VERSION ""

NS_ :

BS_:

BU_:

BO_ 2163223550 CN: 8 Vector__XXX
 SG_ CrashChecksum : 60|4@1+ (1,0) [0|15] "count" Vector__XXX
 SG_ CrashCounter : 56|4@1+ (1,0) [0|15] "count" Vector__XXX
 SG_ CrashType : 0|5@1+ (1,0) [0|31] "" Vector__XXX

BO_ 2230333950 WAND: 8 Vector__XXX
 SG_ WandAngle : 0|16@1+ (0.002,-64) [-64|64.51] "deg" Vector__XXX
 SG_ WandSensorFigureOfMerit : 16|2@1+ (1,0) [0|3] "" Vector__XXX

BO_ 2230334206 LDISP: 8 Vector__XXX
 SG_ MeasuredLinearDisplacement : 0|16@1+ (0.1,0) [0|6425.5] "mm" Vector__XXX
 SG_ LnrDsplmntSnsrSnsrFgrOfMrt : 16|2@1+ (1,0) [0|3] "" Vector__XXX

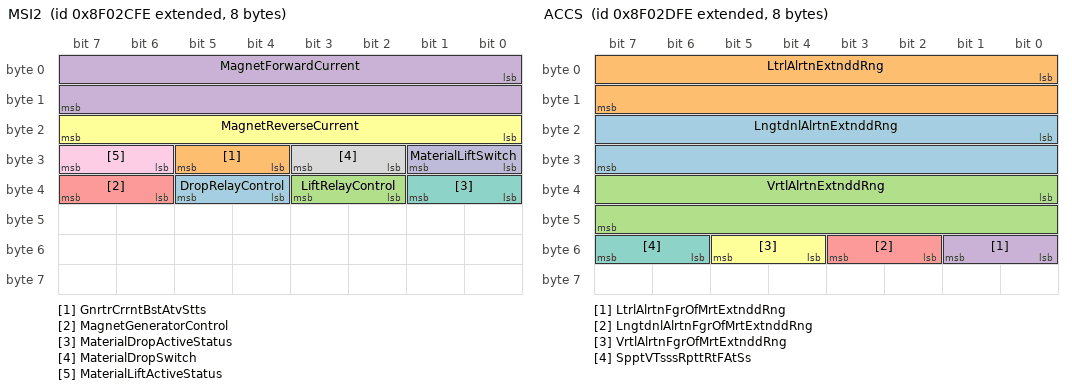
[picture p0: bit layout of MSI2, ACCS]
BO_ 2297441534 MSI2: 8 Vector__XXX
 SG_ DropRelayControl : 36|2@1+ (1,0) [0|3] "" Vector__XXX
 SG_ GnrtrCrrntBstAtvStts : 28|2@1+ (1,0) [0|3] "" Vector__XXX
 SG_ LiftRelayControl : 34|2@1+ (1,0) [0|3] "" Vector__XXX
 SG_ MagnetForwardCurrent : 0|16@1+ (1,0) [0|64255] "A" Vector__XXX
 SG_ MagnetGeneratorControl : 38|2@1+ (1,0) [0|3] "" Vector__XXX
 SG_ MagnetReverseCurrent : 16|8@1+ (1,0) [0|250] "A" Vector__XXX
 SG_ MaterialDropActiveStatus : 32|2@1+ (1,0) [0|3] "" Vector__XXX
 SG_ MaterialDropSwitch : 26|2@1+ (1,0) [0|3] "" Vector__XXX
 SG_ MaterialLiftActiveStatus : 30|2@1+ (1,0) [0|3] "" Vector__XXX
 SG_ MaterialLiftSwitch : 24|2@1+ (1,0) [0|3] "" Vector__XXX

BO_ 2297441790 ACCS: 8 Vector__XXX
 SG_ LngtdnlAlrtnExtnddRng : 16|16@1+ (0.01,-320) [-320|322.55] "m/(s*s)" Vector__XXX
 SG_ LtrlAlrtnExtnddRng : 0|16@1+ (0.01,-320) [-320|322.55] "m/(s*s)" Vector__XXX
 SG_ VrtlAlrtnExtnddRng : 32|16@1+ (0.01,-320) [-320|322.55] "m/(s*s)" Vector__XXX
 SG_ LtrlAlrtnFgrOfMrtExtnddRng : 48|2@1+ (1,0) [0|3] "" Vector__XXX
 SG_ LngtdnlAlrtnFgrOfMrtExtnddRng : 50|2@1+ (1,0) [0|3] "" Vector__XXX
 SG_ VrtlAlrtnFgrOfMrtExtnddRng : 52|2@1+ (1,0) [0|3] "" Vector__XXX
 SG_ SpptVTsssRpttRtFAtSs : 54|2@1+ (1,0) [0|3] "" Vector__XXX

BO_ 2297455358 ETC12: 8 Vector__XXX
 SG_ TrnsmssnDrtnlOtptShftSpd : 32|16@1+ (1,-32127) [-32127|32128] "rpm" Vector__XXX
 SG_ TrnsmssnHdrsttLp1Prssr : 0|16@1+ (1,0) [0|64255] "kPa" Vector__XXX
 SG_ TrnsmssnHdrsttLp2Prssr : 16|16@1+ (1,0) [0|64255] "kPa" Vector__XXX
 SG_ TrnsmssnIntrmdtShftSpd : 48|16@1+ (0.125,0) [0|8031.875] "rpm" Vector__XXX

BO_ 2297499902 B2: 8 Vector__XXX
 SG_ BrakePedalSwitch2 : 16|2@1+ (1,0) [0|3] "" Vector__XXX
 SG_ DmnddBrkAppltnPrssr : 0|16@1+ (0.1,0) [0|6425.5] "kPa" Vector__XXX

BO_ 2298375934 HRW: 8 Vector__XXX
 SG_ FrontAxleLeftWheelSpeed : 0|16@1+ (0.00390625,0) [0|250.99609375] "km/h" Vector__XXX
 SG_ FrontAxleRightWheelSpeed : 16|16@1+ (0.00390625,0) [0|250.99609375] "km/h" Vector__XXX
 SG_ RearAxleLeftWheelSpeed : 32|16@1+ (0.00390625,0) [0|250.99609375] "km/h" Vector__XXX
 SG_ RearAxleRightWheelSpeed : 48|16@1+ (0.00390625,0) [0|250.99609375] "km/h" Vector__XXX

BO_ 2348941054 TC1: 8 Vector__XXX
 SG_ DisengageDrivelineRequest : 4|2@1+ (1,0) [0|3] "" Vector__XXX
 SG_ DsnggDffrntlLkRqstCntrl : 32|2@1+ (1,0) [0|3] "" Vector__XXX
 SG_ DsnggDffrntlLkRqstCntrlFrnt : 34|2@1+ (1,0) [0|3] "" Vector__XXX
 SG_ DsnggDffrntlLkRqstCntrlRr : 36|2@1+ (1,0) [0|3] "" Vector__XXX
 SG_ DsnggDffrntlLkRqstFrntAxl1 : 24|2@1+ (1,0) [0|3] "" Vector__XXX
 SG_ DsnggDffrntlLkRqstFrntAxl2 : 26|2@1+ (1,0) [0|3] "" Vector__XXX
 SG_ DsnggDffrntlLkRqstRrAxl1 : 28|2@1+ (1,0) [0|3] "" Vector__XXX
 SG_ DsnggDffrntlLkRqstRrAxl2 : 30|2@1+ (1,0) [0|3] "" Vector__XXX
 SG_ RequestedPercentClutchSlip : 8|8@1+ (0.4,0) [0|100] "%" Vector__XXX
 SG_ TransmissionMode1 : 40|2@1+ (1,0) [0|3] "" Vector__XXX
 SG_ TransmissionMode2 : 42|2@1+ (1,0) [0|3] "" Vector__XXX
 SG_ TransmissionMode3 : 44|2@1+ (1,0) [0|3] "" Vector__XXX
 SG_ TransmissionMode4 : 46|2@1+ (1,0) [0|3] "" Vector__XXX
 SG_ TransmissionMode5 : 56|2@1+ (1,0) [0|3] "" Vector__XXX
 SG_ TransmissionMode6 : 58|2@1+ (1,0) [0|3] "" Vector__XXX
 SG_ TransmissionMode7 : 60|2@1+ (1,0) [0|3] "" Vector__XXX
 SG_ TransmissionMode8 : 62|2@1+ (1,0) [0|3] "" Vector__XXX
 SG_ TransmissionRequestedGear : 16|8@1+ (1,-125) [-64|64] "gear value" Vector__XXX
 SG_ TransmissionRequestedLaunchGear : 50|4@1+ (1,0) [0|15] "" Vector__XXX
 SG_ TrnsmssnAtNtrlMnlRtrnRqst : 48|2@1+ (1,0) [0|3] "" Vector__XXX
 SG_ TrnsmssnGrShftInhtRqst : 0|2@1+ (1,0) [0|3] "" Vector__XXX
 SG_ TrnsmssnLdRdtnInhtRqst : 38|2@1+ (1,0) [0|3] "" Vector__XXX
 SG_ TrnsmssnRvrsGrShftInhtRqst : 6|2@1+ (1,0) [0|3] "" Vector__XXX
 SG_ TrnsmssnShftSltrDsplMdSwth : 54|2@1+ (1,0) [0|3] "" Vector__XXX
 SG_ TrnsmssnTrqCnvrtrLkpRqst : 2|2@1+ (1,0) [0|3] "" Vector__XXX

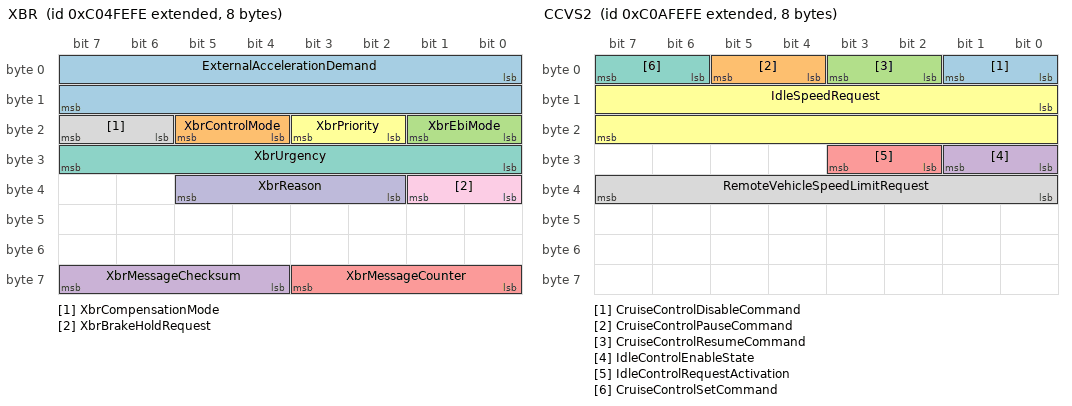
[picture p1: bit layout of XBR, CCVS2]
BO_ 2349137662 XBR: 8 Vector__XXX
 SG_ ExternalAccelerationDemand : 0|16@1+ (0.00048828125,-15.687) [-10|10] "m/(s*s)" Vector__XXX
 SG_ XbrControlMode : 20|2@1+ (1,0) [0|3] "" Vector__XXX
 SG_ XbrEbiMode : 16|2@1+ (1,0) [0|3] "" Vector__XXX
 SG_ XbrMessageChecksum : 60|4@1+ (1,0) [0|15] "count" Vector__XXX
 SG_ XbrMessageCounter : 56|4@1+ (1,0) [0|15] "count" Vector__XXX
 SG_ XbrPriority : 18|2@1+ (1,0) [0|3] "" Vector__XXX
 SG_ XbrUrgency : 24|8@1+ (0.4,0) [0|100] "%" Vector__XXX
 SG_ XbrCompensationMode : 22|2@1+ (1,0) [0|3] "" Vector__XXX
 SG_ XbrBrakeHoldRequest : 32|2@1+ (1,0) [0|3] "" Vector__XXX
 SG_ XbrReason : 34|4@1+ (1,0) [0|15] "" Vector__XXX

BO_ 2349399806 AUXIO5: 8 Vector__XXX
 SG_ AuxiliaryIOChannel3 : 48|16@1+ (1,0) [0|64255] "count" Vector__XXX
 SG_ AuxiliaryIOChannel4 : 32|16@1+ (1,0) [0|64255] "count" Vector__XXX
 SG_ AuxiliaryIOChannel5 : 16|16@1+ (1,0) [0|64255] "count" Vector__XXX
 SG_ AuxiliaryIOChannel6 : 0|16@1+ (1,0) [0|64255] "count" Vector__XXX

BO_ 2349465342 SRASI: 8 Vector__XXX
 SG_ StaticRollAngle : 0|8@1+ (1,-125) [-90|90] "deg" Vector__XXX
 SG_ StaticRollAngleStatus : 8|3@1+ (1,0) [0|7] "" Vector__XXX

BO_ 2349530878 CCVS2: 8 Vector__XXX
 SG_ CruiseControlDisableCommand : 0|2@1+ (1,0) [0|3] "" Vector__XXX
 SG_ CruiseControlPauseCommand : 4|2@1+ (1,0) [0|3] "" Vector__XXX
 SG_ CruiseControlResumeCommand : 2|2@1+ (1,0) [0|3] "" Vector__XXX
 SG_ IdleControlEnableState : 24|2@1+ (1,0) [0|3] "" Vector__XXX
 SG_ IdleControlRequestActivation : 26|2@1+ (1,0) [0|3] "" Vector__XXX
 SG_ IdleSpeedRequest : 8|16@1+ (0.125,0) [0|8031.875] "rpm" Vector__XXX
 SG_ CruiseControlSetCommand : 6|2@1+ (1,0) [0|3] "" Vector__XXX
 SG_ RemoteVehicleSpeedLimitRequest : 32|8@1+ (1,0) [0|250] "km/h" Vector__XXX

BO_ 2349596414 AEBS2: 8 Vector__XXX
 SG_ Aebs2MessageChecksum : 60|4@1+ (1,0) [0|15] "count" Vector__XXX
 SG_ Aebs2MessageCounter : 56|4@1+ (1,0) [0|15] "count" Vector__XXX
 SG_ DvAtvtDdFAdvdEBSst : 0|2@1+ (1,0) [0|3] "" Vector__XXX

BO_ 2349727486 TC2: 8 Vector__XXX
 SG_ TransmissionMode10 : 2|2@1+ (1,0) [0|3] "" Vector__XXX
 SG_ TransmissionMode9 : 0|2@1+ (1,0) [0|3] "" Vector__XXX
 SG_ TrnsmssnPrDfndMxmmGrAtvtnRqst : 4|2@1+ (1,0) [0|3] "" Vector__XXX
 SG_ TrnsmssnOtptShftBrkRqst : 6|2@1+ (1,0) [0|3] "" Vector__XXX
 SG_ TrnsmssnRqstdRvrsLnhGr : 8|4@1+ (1,0) [0|15] "" Vector__XXX
 SG_ SltdMxmmGrLmtAtvtnRqst : 12|2@1+ (1,0) [0|3] "" Vector__XXX
 SG_ TransmissionMode11 : 14|2@1+ (1,0) [0|3] "" Vector__XXX
 SG_ TransmissionMode12 : 16|2@1+ (1,0) [0|3] "" Vector__XXX
 SG_ TransmissionMode13 : 18|2@1+ (1,0) [0|3] "" Vector__XXX
 SG_ TransmissionMode14 : 20|2@1+ (1,0) [0|3] "" Vector__XXX
 SG_ TransmissionMode15 : 22|2@1+ (1,0) [0|3] "" Vector__XXX
 SG_ TransmissionMode16 : 24|2@1+ (1,0) [0|3] "" Vector__XXX
 SG_ TransmissionMode17 : 26|2@1+ (1,0) [0|3] "" Vector__XXX
 SG_ TransmissionMode18 : 28|2@1+ (1,0) [0|3] "" Vector__XXX
 SG_ TransmissionMode19 : 30|2@1+ (1,0) [0|3] "" Vector__XXX
 SG_ TransmissionMode20 : 32|2@1+ (1,0) [0|3] "" Vector__XXX
 SG_ DsnggDffrntlLkRqstRrAxl3 : 34|2@1+ (1,0) [0|3] "" Vector__XXX
 SG_ TrnsmssnCstMdDslRqst : 36|2@1+ (1,0) [0|3] "" Vector__XXX
 SG_ TrnsmssnExpltMnlMdRqst : 38|2@1+ (1,0) [0|3] "" Vector__XXX

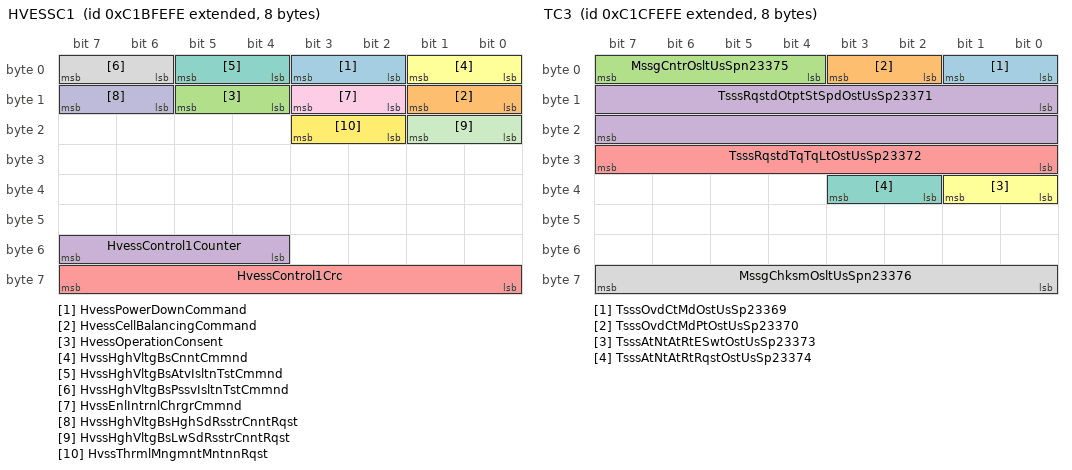
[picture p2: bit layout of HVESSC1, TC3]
BO_ 2350644990 HVESSC1: 8 Vector__XXX
 SG_ HvessPowerDownCommand : 2|2@1+ (1,0) [0|3] "" Vector__XXX
 SG_ HvessCellBalancingCommand : 8|2@1+ (1,0) [0|3] "" Vector__XXX
 SG_ HvessOperationConsent : 12|2@1+ (1,0) [0|3] "" Vector__XXX
 SG_ HvessControl1Counter : 52|4@1+ (1,0) [0|15] "" Vector__XXX
 SG_ HvessControl1Crc : 56|8@1+ (1,0) [0|250] "count" Vector__XXX
 SG_ HvssHghVltgBsCnntCmmnd : 0|2@1+ (1,0) [0|3] "" Vector__XXX
 SG_ HvssHghVltgBsAtvIsltnTstCmmnd : 4|2@1+ (1,0) [0|3] "" Vector__XXX
 SG_ HvssHghVltgBsPssvIsltnTstCmmnd : 6|2@1+ (1,0) [0|3] "" Vector__XXX
 SG_ HvssEnlIntrnlChrgrCmmnd : 10|2@1+ (1,0) [0|3] "" Vector__XXX
 SG_ HvssHghVltgBsHghSdRsstrCnntRqst : 14|2@1+ (1,0) [0|3] "" Vector__XXX
 SG_ HvssHghVltgBsLwSdRsstrCnntRqst : 16|2@1+ (1,0) [0|3] "" Vector__XXX
 SG_ HvssThrmlMngmntMntnnRqst : 18|2@1+ (1,0) [0|3] "" Vector__XXX

BO_ 2350710526 TC3: 8 Vector__XXX
 SG_ TsssOvdCtMdOstUsSp23369 : 0|2@1+ (1,0) [0|3] "" Vector__XXX
 SG_ TsssOvdCtMdPtOstUsSp23370 : 2|2@1+ (1,0) [0|3] "" Vector__XXX
 SG_ MssgCntrOsltUsSpn23375 : 4|4@1+ (1,0) [0|15] "count" Vector__XXX
 SG_ TsssRqstdOtptStSpdOstUsSp23371 : 8|16@1+ (0.25,-8031.75) [-8031.375|8031.75] "rpm" Vector__XXX
 SG_ TsssRqstdTqTqLtOstUsSp23372 : 24|8@1+ (1,-125) [-125|125] "%" Vector__XXX
 SG_ TsssAtNtAtRtESwtOstUsSp23373 : 32|2@1+ (1,0) [0|3] "" Vector__XXX
 SG_ TsssAtNtAtRtRqstOstUsSp23374 : 34|2@1+ (1,0) [0|3] "" Vector__XXX
 SG_ MssgChksmOsltUsSpn23376 : 56|8@1+ (1,0) [0|250] "count" Vector__XXX

BO_ 2350776062 EIC: 8 Vector__XXX
 SG_ EngineTimingAdvance : 0|16@1+ (0.0078125,-200) [-200|301.9921875] "deg" Vector__XXX

BO_ 2350841598 ALTC: 8 Vector__XXX
 SG_ AlternatorTorqueRampTimeCommand : 24|8@1+ (0.1,0) [0.1|25] "s" Vector__XXX
 SG_ AltrntrExttnMxmmCrrntLmt : 16|8@1+ (0.25,0) [0|62.5] "A" Vector__XXX
 SG_ AltrntrStpntVltgCmmnd : 0|16@1+ (0.001,0) [0|64.255] "V" Vector__XXX
 SG_ AltrntrTrqRmpMxmmSpdCmmnd : 32|8@1+ (32,0) [0|8000] "rpm" Vector__XXX

BO_ 2358902526 JLCM: 8 Vector__XXX
 SG_ Joystick1Lamp10Command : 18|2@1+ (1,0) [0|3] "" Vector__XXX
 SG_ Joystick1Lamp1Command : 0|2@1+ (1,0) [0|3] "" Vector__XXX
 SG_ Joystick1Lamp2Command : 2|2@1+ (1,0) [0|3] "" Vector__XXX
 SG_ Joystick1Lamp3Command : 4|2@1+ (1,0) [0|3] "" Vector__XXX
 SG_ Joystick1Lamp4Command : 6|2@1+ (1,0) [0|3] "" Vector__XXX
 SG_ Joystick1Lamp5Command : 8|2@1+ (1,0) [0|3] "" Vector__XXX
 SG_ Joystick1Lamp6Command : 10|2@1+ (1,0) [0|3] "" Vector__XXX
 SG_ Joystick1Lamp7Command : 12|2@1+ (1,0) [0|3] "" Vector__XXX
 SG_ Joystick1Lamp8Command : 14|2@1+ (1,0) [0|3] "" Vector__XXX
 SG_ Joystick1Lamp9Command : 16|2@1+ (1,0) [0|3] "" Vector__XXX
 SG_ Joystick2Lamp10Command : 38|2@1+ (1,0) [0|3] "" Vector__XXX
 SG_ Joystick2Lamp1Command : 20|2@1+ (1,0) [0|3] "" Vector__XXX
 SG_ Joystick2Lamp2Command : 22|2@1+ (1,0) [0|3] "" Vector__XXX
 SG_ Joystick2Lamp3Command : 24|2@1+ (1,0) [0|3] "" Vector__XXX
 SG_ Joystick2Lamp4Command : 26|2@1+ (1,0) [0|3] "" Vector__XXX
 SG_ Joystick2Lamp5Command : 28|2@1+ (1,0) [0|3] "" Vector__XXX
 SG_ Joystick2Lamp6Command : 30|2@1+ (1,0) [0|3] "" Vector__XXX
 SG_ Joystick2Lamp7Command : 32|2@1+ (1,0) [0|3] "" Vector__XXX
 SG_ Joystick2Lamp8Command : 34|2@1+ (1,0) [0|3] "" Vector__XXX
 SG_ Joystick2Lamp9Command : 36|2@1+ (1,0) [0|3] "" Vector__XXX
 SG_ Joystick3Lamp10Command : 58|2@1+ (1,0) [0|3] "" Vector__XXX
 SG_ Joystick3Lamp1Command : 40|2@1+ (1,0) [0|3] "" Vector__XXX
 SG_ Joystick3Lamp2Command : 42|2@1+ (1,0) [0|3] "" Vector__XXX
 SG_ Joystick3Lamp3Command : 44|2@1+ (1,0) [0|3] "" Vector__XXX
 SG_ Joystick3Lamp4Command : 46|2@1+ (1,0) [0|3] "" Vector__XXX
 SG_ Joystick3Lamp5Command : 48|2@1+ (1,0) [0|3] "" Vector__XXX
 SG_ Joystick3Lamp6Command : 50|2@1+ (1,0) [0|3] "" Vector__XXX
 SG_ Joystick3Lamp7Command : 52|2@1+ (1,0) [0|3] "" Vector__XXX
 SG_ Joystick3Lamp8Command : 54|2@1+ (1,0) [0|3] "" Vector__XXX
 SG_ Joystick3Lamp9Command : 56|2@1+ (1,0) [0|3] "" Vector__XXX

BO_ 2362572542 ASC6: 8 Vector__XXX
 SG_ LevelPresetFrontAxleLeft : 0|16@1+ (0.1,-3200) [-3200|3225.5] "mm" Vector__XXX
 SG_ LevelPresetFrontAxleRight : 16|16@1+ (0.1,-3200) [-3200|3225.5] "mm" Vector__XXX
 SG_ LevelPresetRearAxleLeft : 32|16@1+ (0.1,-3200) [-3200|3225.5] "mm" Vector__XXX
 SG_ LevelPresetRearAxleRight : 48|16@1+ (0.1,-3200) [-3200|3225.5] "mm" Vector__XXX

BO_ 2362638078 ASC2: 8 Vector__XXX
 SG_ AllwLvlCntrlDrngBrkngCmmnd : 54|2@1+ (1,0) [0|3] "" Vector__XXX
 SG_ AtmtTrtnHlpLdTrnsfr : 0|2@1+ (1,0) [0|3] "" Vector__XXX
 SG_ DamperStiffnessRequestFrontAxle : 24|8@1+ (0.4,0) [0|100] "%" Vector__XXX
 SG_ DamperStiffnessRequestRearAxle : 32|8@1+ (0.4,0) [0|100] "%" Vector__XXX
 SG_ DmprStffnssRqstLftTgAxl : 40|8@1+ (0.4,0) [0|100] "%" Vector__XXX
 SG_ KneelingCommandFrontAxle : 48|2@1+ (1,0) [0|3] "" Vector__XXX
 SG_ KneelingCommandRearAxle : 50|2@1+ (1,0) [0|3] "" Vector__XXX
 SG_ KneelingControlModeRequest : 6|2@1+ (1,0) [0|3] "" Vector__XXX
 SG_ KneelingRequestLeftSide : 2|2@1+ (1,0) [0|3] "" Vector__XXX
 SG_ KneelingRequestRightSide : 4|2@1+ (1,0) [0|3] "" Vector__XXX
 SG_ LevelControlModeRequest : 16|4@1+ (1,0) [0|15] "" Vector__XXX
 SG_ LiftAxle1PositionCommand : 20|2@1+ (1,0) [0|3] "" Vector__XXX
 SG_ LiftAxle2PositionCommand : 22|2@1+ (1,0) [0|3] "" Vector__XXX
 SG_ MemoryLevelRequest : 60|4@1+ (1,0) [0|15] "" Vector__XXX
 SG_ NominalLevelRequestFrontAxle : 8|4@1+ (1,0) [0|15] "" Vector__XXX
 SG_ NominalLevelRequestRearAxle : 12|4@1+ (1,0) [0|15] "" Vector__XXX
 SG_ PrhtAtmtArSspnsnCntrl : 58|2@1+ (1,0) [0|3] "" Vector__XXX
 SG_ ProhibitAirSuspensionControl : 52|2@1+ (1,0) [0|3] "" Vector__XXX
 SG_ SpdDpndntLvlCntrlRqst : 56|2@1+ (1,0) [0|3] "" Vector__XXX

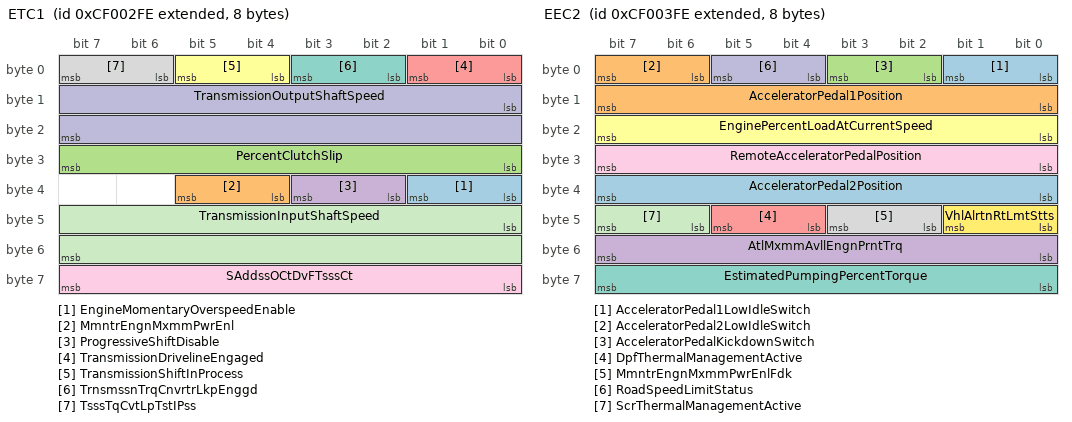
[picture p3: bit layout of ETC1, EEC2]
BO_ 2364539646 ETC1: 8 Vector__XXX
 SG_ EngineMomentaryOverspeedEnable : 32|2@1+ (1,0) [0|3] "" Vector__XXX
 SG_ MmntrEngnMxmmPwrEnl : 36|2@1+ (1,0) [0|3] "" Vector__XXX
 SG_ PercentClutchSlip : 24|8@1+ (0.4,0) [0|100] "%" Vector__XXX
 SG_ ProgressiveShiftDisable : 34|2@1+ (1,0) [0|3] "" Vector__XXX
 SG_ TransmissionDrivelineEngaged : 0|2@1+ (1,0) [0|3] "" Vector__XXX
 SG_ TransmissionShiftInProcess : 4|2@1+ (1,0) [0|3] "" Vector__XXX
 SG_ TrnsmssnTrqCnvrtrLkpEnggd : 2|2@1+ (1,0) [0|3] "" Vector__XXX
 SG_ TsssTqCvtLpTstIPss : 6|2@1+ (1,0) [0|3] "" Vector__XXX
 SG_ SAddssOCtDvFTsssCt : 56|8@1+ (1,0) [0|253] "sourceadr" Vector__XXX
 SG_ TransmissionOutputShaftSpeed : 8|16@1+ (0.125,0) [0|8031.875] "rpm" Vector__XXX
 SG_ TransmissionInputShaftSpeed : 40|16@1+ (0.125,0) [0|8031.875] "rpm" Vector__XXX

BO_ 2364539902 EEC2: 8 Vector__XXX
 SG_ AcceleratorPedal1LowIdleSwitch : 0|2@1+ (1,0) [0|3] "" Vector__XXX
 SG_ AcceleratorPedal2LowIdleSwitch : 6|2@1+ (1,0) [0|3] "" Vector__XXX
 SG_ AcceleratorPedalKickdownSwitch : 2|2@1+ (1,0) [0|3] "" Vector__XXX
 SG_ AtlMxmmAvllEngnPrntTrq : 48|8@1+ (0.4,0) [0|100] "%" Vector__XXX
 SG_ DpfThermalManagementActive : 44|2@1+ (1,0) [0|3] "" Vector__XXX
 SG_ EnginePercentLoadAtCurrentSpeed : 16|8@1+ (1,0) [0|125] "%" Vector__XXX
 SG_ EstimatedPumpingPercentTorque : 56|8@1+ (1,-125) [-125|125] "%" Vector__XXX
 SG_ MmntrEngnMxmmPwrEnlFdk : 42|2@1+ (1,0) [0|3] "" Vector__XXX
 SG_ RemoteAcceleratorPedalPosition : 24|8@1+ (0.4,0) [0|100] "%" Vector__XXX
 SG_ RoadSpeedLimitStatus : 4|2@1+ (1,0) [0|3] "" Vector__XXX
 SG_ ScrThermalManagementActive : 46|2@1+ (1,0) [0|3] "" Vector__XXX
 SG_ VhlAlrtnRtLmtStts : 40|2@1+ (1,0) [0|3] "" Vector__XXX
 SG_ AcceleratorPedal2Position : 32|8@1+ (0.4,0) [0|100] "%" Vector__XXX
 SG_ AcceleratorPedal1Position : 8|8@1+ (0.4,0) [0|100] "%" Vector__XXX

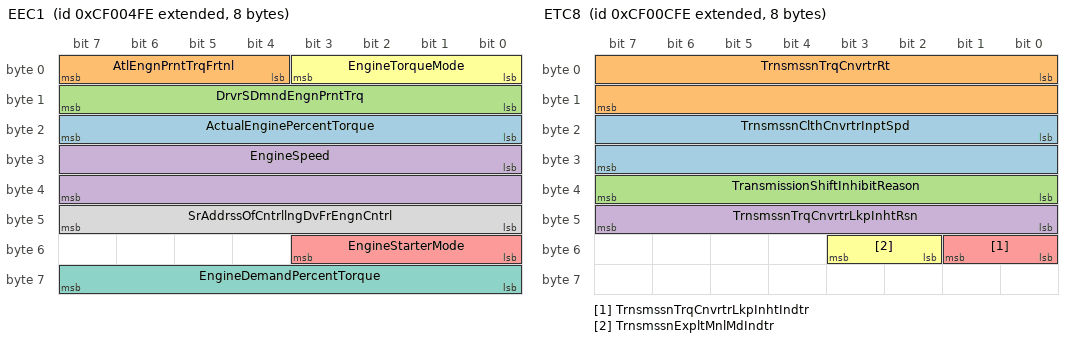
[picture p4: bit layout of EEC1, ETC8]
BO_ 2364540158 EEC1: 8 Vector__XXX
 SG_ ActualEnginePercentTorque : 16|8@1+ (1,-125) [0|125] "%" Vector__XXX
 SG_ AtlEngnPrntTrqFrtnl : 4|4@1+ (0.125,0) [0|0.875] "%" Vector__XXX
 SG_ DrvrSDmndEngnPrntTrq : 8|8@1+ (1,-125) [0|125] "%" Vector__XXX
 SG_ EngineSpeed : 24|16@1+ (0.125,0) [0|8031.875] "rpm" Vector__XXX
 SG_ EngineStarterMode : 48|4@1+ (1,0) [0|15] "" Vector__XXX
 SG_ EngineTorqueMode : 0|4@1+ (1,0) [0|15] "" Vector__XXX
 SG_ EngineDemandPercentTorque : 56|8@1+ (1,-125) [-125|125] "%" Vector__XXX
 SG_ SrAddrssOfCntrllngDvFrEngnCntrl : 40|8@1+ (1,0) [0|253] "sourceadr" Vector__XXX

BO_ 2364541694 EGF1: 8 Vector__XXX
 SG_ EngineIntakeAirMassFlowRate : 16|16@1+ (0.05,0) [0|3212.75] "kg/h" Vector__XXX
 SG_ EngnExhstGsRrltn1MssFlwRt : 0|16@1+ (0.05,0) [0|3212.75] "kg/h" Vector__XXX
 SG_ EngnExhstGsRrltn2MssFlwRt : 32|16@1+ (0.05,0) [0|3212.75] "kg/h" Vector__XXX
 SG_ TargetFreshAirMassFlow : 48|16@1+ (0.05,0) [0|3212.75] "kg/h" Vector__XXX

BO_ 2364542206 ETC8: 8 Vector__XXX
 SG_ TrnsmssnClthCnvrtrInptSpd : 16|16@1+ (0.125,0) [0|8031.875] "rpm" Vector__XXX
 SG_ TrnsmssnTrqCnvrtrRt : 0|16@1+ (0.001,0) [0|64.255] "" Vector__XXX
 SG_ TransmissionShiftInhibitReason : 32|8@1+ (1,0) [0|250] "" Vector__XXX
 SG_ TrnsmssnTrqCnvrtrLkpInhtRsn : 40|8@1+ (1,0) [0|250] "" Vector__XXX
 SG_ TrnsmssnTrqCnvrtrLkpInhtIndtr : 48|2@1+ (1,0) [0|3] "" Vector__XXX
 SG_ TrnsmssnExpltMnlMdIndtr : 50|2@1+ (1,0) [0|3] "" Vector__XXX

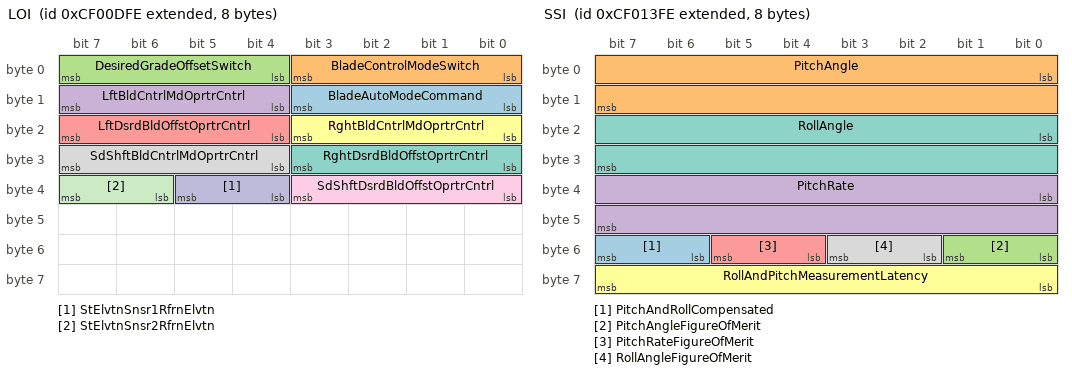
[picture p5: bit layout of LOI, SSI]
BO_ 2364542462 LOI: 8 Vector__XXX
 SG_ BladeAutoModeCommand : 8|4@1+ (1,0) [0|15] "" Vector__XXX
 SG_ BladeControlModeSwitch : 0|4@1+ (1,0) [0|15] "" Vector__XXX
 SG_ DesiredGradeOffsetSwitch : 4|4@1+ (1,0) [0|15] "" Vector__XXX
 SG_ LftBldCntrlMdOprtrCntrl : 12|4@1+ (1,0) [0|15] "" Vector__XXX
 SG_ LftDsrdBldOffstOprtrCntrl : 20|4@1+ (1,0) [0|15] "" Vector__XXX
 SG_ RghtBldCntrlMdOprtrCntrl : 16|4@1+ (1,0) [0|15] "" Vector__XXX
 SG_ RghtDsrdBldOffstOprtrCntrl : 24|4@1+ (1,0) [0|15] "" Vector__XXX
 SG_ SdShftBldCntrlMdOprtrCntrl : 28|4@1+ (1,0) [0|15] "" Vector__XXX
 SG_ SdShftDsrdBldOffstOprtrCntrl : 32|4@1+ (1,0) [0|15] "" Vector__XXX
 SG_ StElvtnSnsr1RfrnElvtn : 36|2@1+ (1,0) [0|3] "" Vector__XXX
 SG_ StElvtnSnsr2RfrnElvtn : 38|2@1+ (1,0) [0|3] "" Vector__XXX

BO_ 2364543998 SSI: 8 Vector__XXX
 SG_ PitchAndRollCompensated : 54|2@1+ (1,0) [0|3] "" Vector__XXX
 SG_ PitchAngle : 0|16@1+ (0.002,-64) [-64|64.51] "deg" Vector__XXX
 SG_ PitchAngleFigureOfMerit : 48|2@1+ (1,0) [0|3] "" Vector__XXX
 SG_ PitchRate : 32|16@1+ (0.002,-64) [-64|64.51] "deg/s" Vector__XXX
 SG_ PitchRateFigureOfMerit : 52|2@1+ (1,0) [0|3] "" Vector__XXX
 SG_ RollAndPitchMeasurementLatency : 56|8@1+ (0.5,0) [0|125] "ms" Vector__XXX
 SG_ RollAngle : 16|16@1+ (0.002,-64) [-64|64.51] "deg" Vector__XXX
 SG_ RollAngleFigureOfMerit : 50|2@1+ (1,0) [0|3] "" Vector__XXX

BO_ 2364544254 BI: 8 Vector__XXX
 SG_ BladeRotationAngle : 16|16@1+ (0.0078125,-200) [-200|301.9921875] "deg" Vector__XXX
 SG_ BladeRotationAngleFigureOfMerit : 42|2@1+ (1,0) [0|3] "" Vector__XXX
 SG_ RelativeBladeHeight : 0|16@1+ (0.1,-3200) [-3200|3225.5] "mm" Vector__XXX
 SG_ RtvBdHtAdBdRttAMstLt : 32|8@1+ (0.5,0) [0|125] "ms" Vector__XXX
 SG_ RltvBldHghtFgrOfMrt : 40|2@1+ (1,0) [0|3] "" Vector__XXX

BO_ 2364544510 RGTACRP: 8 Vector__XXX
 SG_ RqstdGnrtrOvrllPwrFtr : 32|16@1+ (0.00006103515625,-1) [-1|1] "" Vector__XXX
 SG_ RqstdGnrtrOvrllPwrFtrLggng : 48|2@1+ (1,0) [0|3] "" Vector__XXX
 SG_ RqstdGnrtrTtlARtvPwr : 0|32@1+ (1,-2000000000) [-2000000000|2211081215] "VA" Vector__XXX

BO_ 2364544766 CCS: 8 Vector__XXX
 SG_ EngineCylinder1CombustionStatus : 0|2@1+ (1,0) [0|3] "" Vector__XXX
 SG_ EngineCylinder2CombustionStatus : 2|2@1+ (1,0) [0|3] "" Vector__XXX
 SG_ EngineCylinder3CombustionStatus : 4|2@1+ (1,0) [0|3] "" Vector__XXX
 SG_ EngineCylinder4CombustionStatus : 6|2@1+ (1,0) [0|3] "" Vector__XXX
 SG_ EngineCylinder5CombustionStatus : 8|2@1+ (1,0) [0|3] "" Vector__XXX
 SG_ EngineCylinder6CombustionStatus : 10|2@1+ (1,0) [0|3] "" Vector__XXX
 SG_ EngineCylinder7CombustionStatus : 12|2@1+ (1,0) [0|3] "" Vector__XXX
 SG_ EngineCylinder8CombustionStatus : 14|2@1+ (1,0) [0|3] "" Vector__XXX
 SG_ EngineCylinder9CombustionStatus : 16|2@1+ (1,0) [0|3] "" Vector__XXX
 SG_ EngnClndr10CmstnStts : 18|2@1+ (1,0) [0|3] "" Vector__XXX
 SG_ EngnClndr11CmstnStts : 20|2@1+ (1,0) [0|3] "" Vector__XXX
 SG_ EngnClndr12CmstnStts : 22|2@1+ (1,0) [0|3] "" Vector__XXX
 SG_ EngnClndr13CmstnStts : 24|2@1+ (1,0) [0|3] "" Vector__XXX
 SG_ EngnClndr14CmstnStts : 26|2@1+ (1,0) [0|3] "" Vector__XXX
 SG_ EngnClndr15CmstnStts : 28|2@1+ (1,0) [0|3] "" Vector__XXX
 SG_ EngnClndr16CmstnStts : 30|2@1+ (1,0) [0|3] "" Vector__XXX
 SG_ EngnClndr17CmstnStts : 32|2@1+ (1,0) [0|3] "" Vector__XXX
 SG_ EngnClndr18CmstnStts : 34|2@1+ (1,0) [0|3] "" Vector__XXX
 SG_ EngnClndr19CmstnStts : 36|2@1+ (1,0) [0|3] "" Vector__XXX
 SG_ EngnClndr20CmstnStts : 38|2@1+ (1,0) [0|3] "" Vector__XXX
 SG_ EngnClndr21CmstnStts : 40|2@1+ (1,0) [0|3] "" Vector__XXX
 SG_ EngnClndr22CmstnStts : 42|2@1+ (1,0) [0|3] "" Vector__XXX
 SG_ EngnClndr23CmstnStts : 44|2@1+ (1,0) [0|3] "" Vector__XXX
 SG_ EngnClndr24CmstnStts : 46|2@1+ (1,0) [0|3] "" Vector__XXX

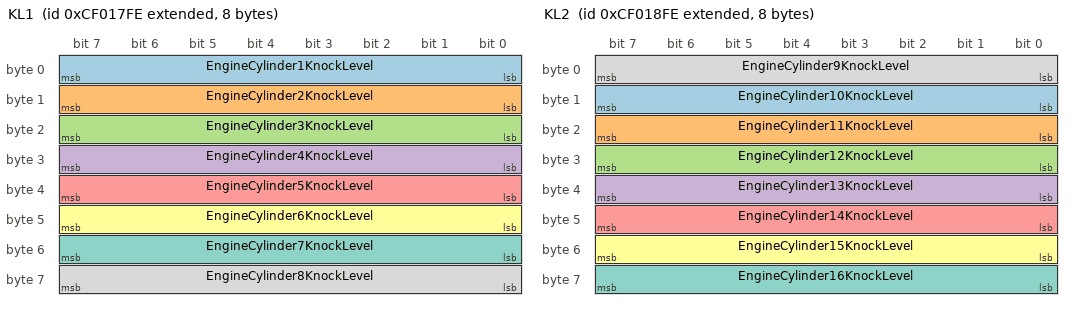
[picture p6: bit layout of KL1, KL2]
BO_ 2364545022 KL1: 8 Vector__XXX
 SG_ EngineCylinder1KnockLevel : 0|8@1+ (1,0) [0|100] "%" Vector__XXX
 SG_ EngineCylinder2KnockLevel : 8|8@1+ (1,0) [0|250] "%" Vector__XXX
 SG_ EngineCylinder3KnockLevel : 16|8@1+ (1,0) [0|250] "%" Vector__XXX
 SG_ EngineCylinder4KnockLevel : 24|8@1+ (1,0) [0|250] "%" Vector__XXX
 SG_ EngineCylinder5KnockLevel : 32|8@1+ (1,0) [0|250] "%" Vector__XXX
 SG_ EngineCylinder6KnockLevel : 40|8@1+ (1,0) [0|250] "%" Vector__XXX
 SG_ EngineCylinder7KnockLevel : 48|8@1+ (1,0) [0|250] "%" Vector__XXX
 SG_ EngineCylinder8KnockLevel : 56|8@1+ (1,0) [0|250] "%" Vector__XXX

BO_ 2364545278 KL2: 8 Vector__XXX
 SG_ EngineCylinder10KnockLevel : 8|8@1+ (1,0) [0|250] "%" Vector__XXX
 SG_ EngineCylinder11KnockLevel : 16|8@1+ (1,0) [0|250] "%" Vector__XXX
 SG_ EngineCylinder12KnockLevel : 24|8@1+ (1,0) [0|250] "%" Vector__XXX
 SG_ EngineCylinder13KnockLevel : 32|8@1+ (1,0) [0|250] "%" Vector__XXX
 SG_ EngineCylinder14KnockLevel : 40|8@1+ (1,0) [0|250] "%" Vector__XXX
 SG_ EngineCylinder15KnockLevel : 48|8@1+ (1,0) [0|250] "%" Vector__XXX
 SG_ EngineCylinder16KnockLevel : 56|8@1+ (1,0) [0|250] "%" Vector__XXX
 SG_ EngineCylinder9KnockLevel : 0|8@1+ (1,0) [0|250] "%" Vector__XXX

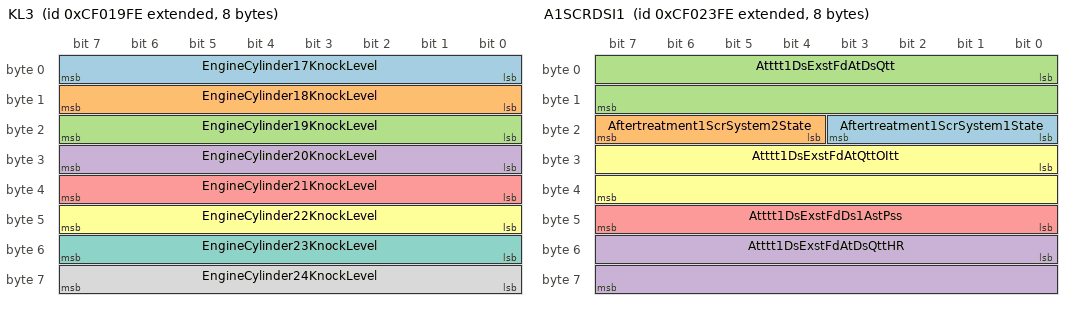
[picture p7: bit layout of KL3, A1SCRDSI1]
BO_ 2364545534 KL3: 8 Vector__XXX
 SG_ EngineCylinder17KnockLevel : 0|8@1+ (1,0) [0|250] "%" Vector__XXX
 SG_ EngineCylinder18KnockLevel : 8|8@1+ (1,0) [0|250] "%" Vector__XXX
 SG_ EngineCylinder19KnockLevel : 16|8@1+ (1,0) [0|250] "%" Vector__XXX
 SG_ EngineCylinder20KnockLevel : 24|8@1+ (1,0) [0|250] "%" Vector__XXX
 SG_ EngineCylinder21KnockLevel : 32|8@1+ (1,0) [0|250] "%" Vector__XXX
 SG_ EngineCylinder22KnockLevel : 40|8@1+ (1,0) [0|250] "%" Vector__XXX
 SG_ EngineCylinder23KnockLevel : 48|8@1+ (1,0) [0|250] "%" Vector__XXX
 SG_ EngineCylinder24KnockLevel : 56|8@1+ (1,0) [0|250] "%" Vector__XXX

BO_ 2364546302 RGAAC: 8 Vector__XXX
 SG_ RqstdGnrtrAvrgLnLnARmsVltg : 0|32@1+ (0.0078125,0) [0|32899071.9921875] "V" Vector__XXX

BO_ 2364546814 GC2: 8 Vector__XXX
 SG_ EngineLoadSetpointRequest : 24|16@1+ (0.5,0) [0|32127.5] "kW" Vector__XXX
 SG_ EngineSelfInducedDerateInhibit : 16|2@1+ (1,0) [0|3] "" Vector__XXX
 SG_ GeneratorGoverningBias : 0|16@1+ (0.004,-125) [-125|125] "%" Vector__XXX

BO_ 2364548094 A1SCRDSI1: 8 Vector__XXX
 SG_ Aftertreatment1ScrSystem1State : 16|4@1+ (1,0) [0|15] "" Vector__XXX
 SG_ Aftertreatment1ScrSystem2State : 20|4@1+ (1,0) [0|15] "" Vector__XXX
 SG_ Atttt1DsExstFdAtDsQtt : 0|16@1+ (0.3,0) [0|19276.5] "g/h" Vector__XXX
 SG_ Atttt1DsExstFdAtDsQttHR : 48|16@1+ (0.05,0) [0|3212.75] "g/min" Vector__XXX
 SG_ Atttt1DsExstFdDs1AstPss : 40|8@1+ (8,0) [0|2000] "kPa" Vector__XXX
 SG_ Atttt1DsExstFdAtQttOItt : 24|16@1+ (0.1,0) [0|6425.5] "g" Vector__XXX

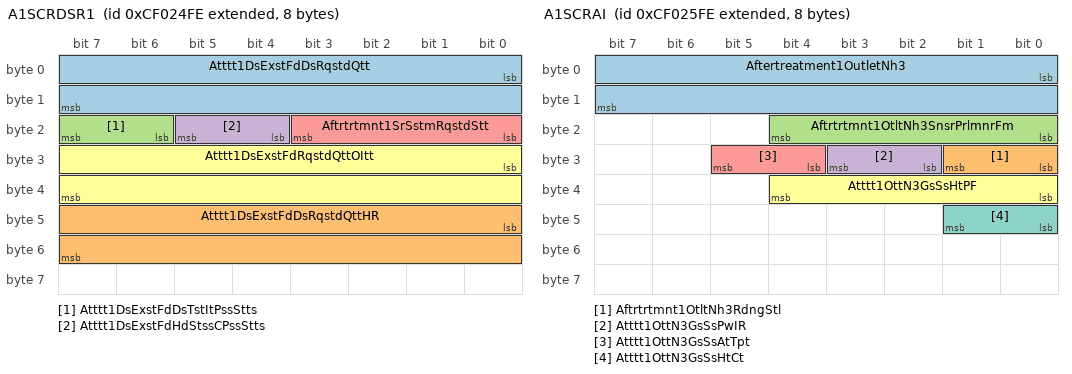
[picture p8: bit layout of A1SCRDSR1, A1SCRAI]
BO_ 2364548350 A1SCRDSR1: 8 Vector__XXX
 SG_ Atttt1DsExstFdDsRqstdQtt : 0|16@1+ (0.3,0) [0|19276.5] "g/h" Vector__XXX
 SG_ Atttt1DsExstFdDsRqstdQttHR : 40|16@1+ (0.05,0) [0|3212.75] "g/min" Vector__XXX
 SG_ Atttt1DsExstFdDsTstItPssStts : 22|2@1+ (1,0) [0|3] "" Vector__XXX
 SG_ Atttt1DsExstFdHdStssCPssStts : 20|2@1+ (1,0) [0|3] "" Vector__XXX
 SG_ Aftrtrtmnt1SrSstmRqstdStt : 16|4@1+ (1,0) [0|15] "" Vector__XXX
 SG_ Atttt1DsExstFdRqstdQttOItt : 24|16@1+ (0.1,0) [0|6425.5] "g" Vector__XXX

BO_ 2364548606 A1SCRAI: 8 Vector__XXX
 SG_ Aftertreatment1OutletNh3 : 0|16@1+ (0.05,-200) [-200|3012.75] "ppm" Vector__XXX
 SG_ Aftrtrtmnt1OtltNh3RdngStl : 24|2@1+ (1,0) [0|3] "" Vector__XXX
 SG_ Aftrtrtmnt1OtltNh3SnsrPrlmnrFm : 16|5@1+ (1,0) [0|31] "" Vector__XXX
 SG_ Atttt1OttN3GsSsPwIR : 26|2@1+ (1,0) [0|3] "" Vector__XXX
 SG_ Atttt1OttN3GsSsAtTpt : 28|2@1+ (1,0) [0|3] "" Vector__XXX
 SG_ Atttt1OttN3GsSsHtPF : 32|5@1+ (1,0) [0|31] "" Vector__XXX
 SG_ Atttt1OttN3GsSsHtCt : 40|2@1+ (1,0) [0|3] "" Vector__XXX

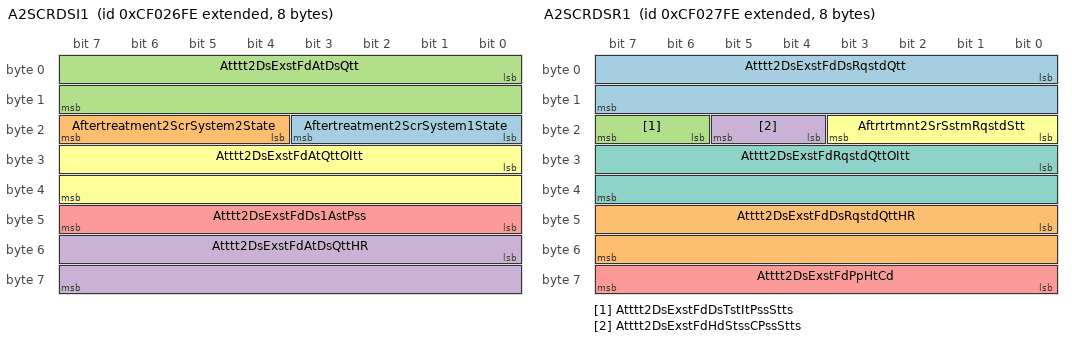
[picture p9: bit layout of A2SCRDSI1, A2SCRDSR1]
BO_ 2364548862 A2SCRDSI1: 8 Vector__XXX
 SG_ Aftertreatment2ScrSystem1State : 16|4@1+ (1,0) [0|15] "" Vector__XXX
 SG_ Aftertreatment2ScrSystem2State : 20|4@1+ (1,0) [0|15] "" Vector__XXX
 SG_ Atttt2DsExstFdAtDsQtt : 0|16@1+ (0.3,0) [0|19276.5] "g/h" Vector__XXX
 SG_ Atttt2DsExstFdAtDsQttHR : 48|16@1+ (0.05,0) [0|3212.75] "g/min" Vector__XXX
 SG_ Atttt2DsExstFdDs1AstPss : 40|8@1+ (8,0) [0|2000] "kPa" Vector__XXX
 SG_ Atttt2DsExstFdAtQttOItt : 24|16@1+ (0.1,0) [0|6425.5] "g" Vector__XXX

BO_ 2364549118 A2SCRDSR1: 8 Vector__XXX
 SG_ Atttt2DsExstFdDsRqstdQtt : 0|16@1+ (0.3,0) [0|19276.5] "g/h" Vector__XXX
 SG_ Atttt2DsExstFdDsRqstdQttHR : 40|16@1+ (0.05,0) [0|3212.75] "g/min" Vector__XXX
 SG_ Atttt2DsExstFdDsTstItPssStts : 22|2@1+ (1,0) [0|3] "" Vector__XXX
 SG_ Atttt2DsExstFdHdStssCPssStts : 20|2@1+ (1,0) [0|3] "" Vector__XXX
 SG_ Atttt2DsExstFdPpHtCd : 56|8@1+ (0.4,0) [0|100] "%" Vector__XXX
 SG_ Aftrtrtmnt2SrSstmRqstdStt : 16|4@1+ (1,0) [0|15] "" Vector__XXX
 SG_ Atttt2DsExstFdRqstdQttOItt : 24|16@1+ (0.1,0) [0|6425.5] "g" Vector__XXX

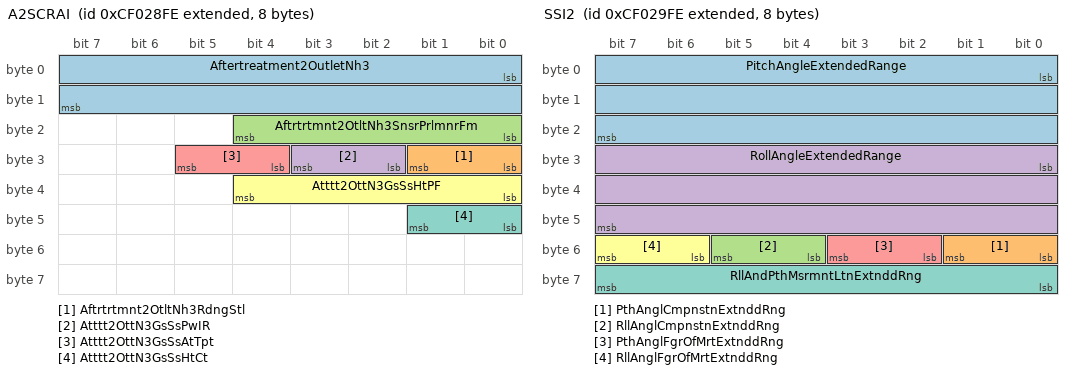
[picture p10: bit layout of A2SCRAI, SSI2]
BO_ 2364549374 A2SCRAI: 8 Vector__XXX
 SG_ Aftertreatment2OutletNh3 : 0|16@1+ (0.05,-200) [-200|3012.75] "ppm" Vector__XXX
 SG_ Aftrtrtmnt2OtltNh3RdngStl : 24|2@1+ (1,0) [0|3] "" Vector__XXX
 SG_ Aftrtrtmnt2OtltNh3SnsrPrlmnrFm : 16|5@1+ (1,0) [0|31] "" Vector__XXX
 SG_ Atttt2OttN3GsSsPwIR : 26|2@1+ (1,0) [0|3] "" Vector__XXX
 SG_ Atttt2OttN3GsSsAtTpt : 28|2@1+ (1,0) [0|3] "" Vector__XXX
 SG_ Atttt2OttN3GsSsHtPF : 32|5@1+ (1,0) [0|31] "" Vector__XXX
 SG_ Atttt2OttN3GsSsHtCt : 40|2@1+ (1,0) [0|3] "" Vector__XXX

BO_ 2364549630 SSI2: 8 Vector__XXX
 SG_ PitchAngleExtendedRange : 0|24@1+ (0.000030517578125,-250) [-250|251.999969482421] "deg" Vector__XXX
 SG_ PthAnglCmpnstnExtnddRng : 48|2@1+ (1,0) [0|3] "" Vector__XXX
 SG_ RllAnglCmpnstnExtnddRng : 52|2@1+ (1,0) [0|3] "" Vector__XXX
 SG_ RollAngleExtendedRange : 24|24@1+ (0.000030517578125,-250) [-250|251.999969482421] "deg" Vector__XXX
 SG_ PthAnglFgrOfMrtExtnddRng : 50|2@1+ (1,0) [0|3] "" Vector__XXX
 SG_ RllAnglFgrOfMrtExtnddRng : 54|2@1+ (1,0) [0|3] "" Vector__XXX
 SG_ RllAndPthMsrmntLtnExtnddRng : 56|8@1+ (0.5,0) [0|125] "ms" Vector__XXX

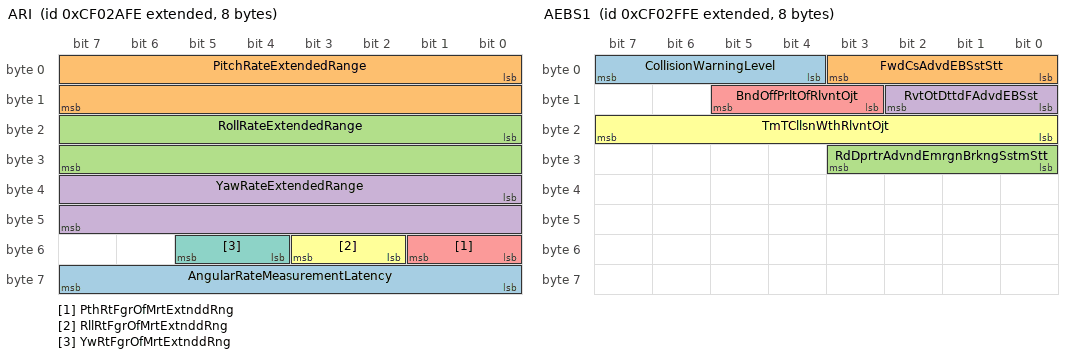
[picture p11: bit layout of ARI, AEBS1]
BO_ 2364549886 ARI: 8 Vector__XXX
 SG_ AngularRateMeasurementLatency : 56|8@1+ (0.5,0) [0|125] "ms" Vector__XXX
 SG_ PitchRateExtendedRange : 0|16@1+ (0.0078125,-250) [-250|251.9921875] "deg/s" Vector__XXX
 SG_ RollRateExtendedRange : 16|16@1+ (0.0078125,-250) [-250|251.9921875] "deg/s" Vector__XXX
 SG_ YawRateExtendedRange : 32|16@1+ (0.0078125,-250) [-250|251.9921875] "deg/s" Vector__XXX
 SG_ PthRtFgrOfMrtExtnddRng : 48|2@1+ (1,0) [0|3] "" Vector__XXX
 SG_ RllRtFgrOfMrtExtnddRng : 50|2@1+ (1,0) [0|3] "" Vector__XXX
 SG_ YwRtFgrOfMrtExtnddRng : 52|2@1+ (1,0) [0|3] "" Vector__XXX

BO_ 2364551166 AEBS1: 8 Vector__XXX
 SG_ CollisionWarningLevel : 4|4@1+ (1,0) [0|15] "" Vector__XXX
 SG_ FwdCsAdvdEBSstStt : 0|4@1+ (1,0) [0|15] "" Vector__XXX
 SG_ RdDprtrAdvndEmrgnBrkngSstmStt : 24|4@1+ (1,0) [0|15] "" Vector__XXX
 SG_ RvtOtDttdFAdvdEBSst : 8|3@1+ (1,0) [0|7] "" Vector__XXX
 SG_ BndOffPrltOfRlvntOjt : 11|3@1+ (1,0) [0|7] "" Vector__XXX
 SG_ TmTCllsnWthRlvntOjt : 16|8@1+ (0.05,0) [0|12.5] "s" Vector__XXX

BO_ 2364551422 WS: 8 Vector__XXX
 SG_ TransmitterCommandState : 20|4@1+ (1,0) [0|15] "" Vector__XXX
 SG_ TransmitterId1 : 24|24@1+ (1,0) [0|16449535] "ID" Vector__XXX
 SG_ WirelessRollingMessageCounter : 0|16@1+ (1,0) [0|64255] "count" Vector__XXX
 SG_ WirelessSignalStrength1 : 48|8@1+ (0.5,-125) [-125|0] "dBm" Vector__XXX

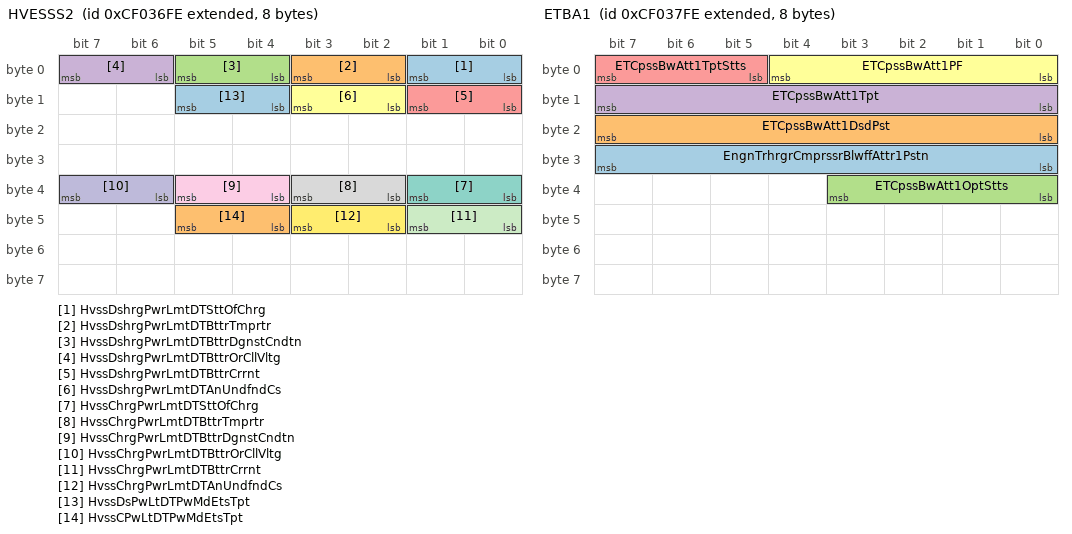
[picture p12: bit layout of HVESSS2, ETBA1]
BO_ 2364552958 HVESSS2: 8 Vector__XXX
 SG_ HvssDshrgPwrLmtDTSttOfChrg : 0|2@1+ (1,0) [0|3] "" Vector__XXX
 SG_ HvssDshrgPwrLmtDTBttrTmprtr : 2|2@1+ (1,0) [0|3] "" Vector__XXX
 SG_ HvssDshrgPwrLmtDTBttrDgnstCndtn : 4|2@1+ (1,0) [0|3] "" Vector__XXX
 SG_ HvssDshrgPwrLmtDTBttrOrCllVltg : 6|2@1+ (1,0) [0|3] "" Vector__XXX
 SG_ HvssDshrgPwrLmtDTBttrCrrnt : 8|2@1+ (1,0) [0|3] "" Vector__XXX
 SG_ HvssDshrgPwrLmtDTAnUndfndCs : 10|2@1+ (1,0) [0|3] "" Vector__XXX
 SG_ HvssChrgPwrLmtDTSttOfChrg : 32|2@1+ (1,0) [0|3] "" Vector__XXX
 SG_ HvssChrgPwrLmtDTBttrTmprtr : 34|2@1+ (1,0) [0|3] "" Vector__XXX
 SG_ HvssChrgPwrLmtDTBttrDgnstCndtn : 36|2@1+ (1,0) [0|3] "" Vector__XXX
 SG_ HvssChrgPwrLmtDTBttrOrCllVltg : 38|2@1+ (1,0) [0|3] "" Vector__XXX
 SG_ HvssChrgPwrLmtDTBttrCrrnt : 40|2@1+ (1,0) [0|3] "" Vector__XXX
 SG_ HvssChrgPwrLmtDTAnUndfndCs : 42|2@1+ (1,0) [0|3] "" Vector__XXX
 SG_ HvssDsPwLtDTPwMdEtsTpt : 12|2@1+ (1,0) [0|3] "" Vector__XXX
 SG_ HvssCPwLtDTPwMdEtsTpt : 44|2@1+ (1,0) [0|3] "" Vector__XXX

BO_ 2364553214 ETBA1: 8 Vector__XXX
 SG_ EngnTrhrgrCmprssrBlwffAttr1Pstn : 24|8@1+ (0.4,0) [0|100] "%" Vector__XXX
 SG_ ETCpssBwAtt1DsdPst : 16|8@1+ (0.4,0) [0|100] "%" Vector__XXX
 SG_ ETCpssBwAtt1OptStts : 32|4@1+ (1,0) [0|15] "" Vector__XXX
 SG_ ETCpssBwAtt1Tpt : 8|8@1+ (1,-40) [-40|210] "degC" Vector__XXX
 SG_ ETCpssBwAtt1TptStts : 5|3@1+ (1,0) [0|7] "" Vector__XXX
 SG_ ETCpssBwAtt1PF : 0|5@1+ (1,0) [0|31] "" Vector__XXX

BO_ 2364553470 ETFR: 8 Vector__XXX
 SG_ EngineCylinderTorque : 40|16@1+ (1,0) [0|64255] "Nm" Vector__XXX
 SG_ EngineDualFuelModeCommand : 56|2@1+ (1,0) [0|100] "" Vector__XXX
 SG_ EngnClndrDslMssFlwRtCmmnd : 24|16@1+ (0.00006103515625,0) [0|3.92181396484375] "kg/s" Vector__XXX
 SG_ EngnClndrGsMssFlwRtCmmnd : 8|16@1+ (0.00006103515625,0) [0|3.92181396484375] "kg/s" Vector__XXX
 SG_ EngnGsSstttnFlPrntgCmmnd : 0|8@1+ (0.5,0) [0|100] "%" Vector__XXX

BO_ 2364553726 EASI: 8 Vector__XXX
 SG_ EngineDesiredAirFuelRatio : 0|16@1+ (0.001,0) [0|64.255] "" Vector__XXX
 SG_ EngnFlSstm1TtlIntkMssArFlwRt : 16|16@1+ (0.0009765625,0) [0|62.7490234375] "kg/s" Vector__XXX
 SG_ EngnFlSstm2TtlIntkMssArFlwRt : 32|16@1+ (0.0009765625,0) [0|62.7490234375] "kg/s" Vector__XXX
 SG_ CommandedEquivalenceRatio : 48|16@1+ (0.001,0) [0|64.255] "" Vector__XXX

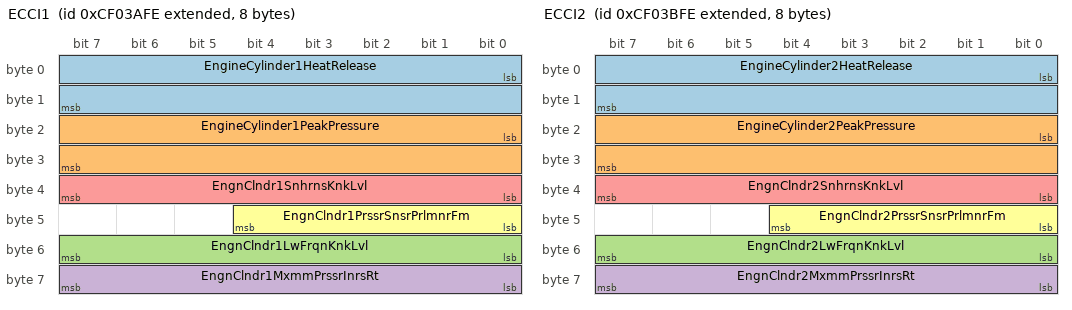
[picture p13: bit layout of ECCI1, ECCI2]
BO_ 2364553982 ECCI1: 8 Vector__XXX
 SG_ EngineCylinder1HeatRelease : 0|16@1+ (0.0001220703125,-1) [-1|6.8436279296875] "kJ/l" Vector__XXX
 SG_ EngineCylinder1PeakPressure : 16|16@1+ (0.0009765625,0) [0|62.7490234375] "MPa" Vector__XXX
 SG_ EngnClndr1LwFrqnKnkLvl : 48|8@1+ (1,0) [0|250] "%" Vector__XXX
 SG_ EngnClndr1MxmmPrssrInrsRt : 56|8@1+ (16,0) [0|4000] "kPa/deg crank angle" Vector__XXX
 SG_ EngnClndr1SnhrnsKnkLvl : 32|8@1+ (1,0) [0|100] "%" Vector__XXX
 SG_ EngnClndr1PrssrSnsrPrlmnrFm : 40|5@1+ (1,0) [0|31] "" Vector__XXX

BO_ 2364554238 ECCI2: 8 Vector__XXX
 SG_ EngineCylinder2HeatRelease : 0|16@1+ (0.0001220703125,-1) [-1|6.8436279296875] "kJ/l" Vector__XXX
 SG_ EngineCylinder2PeakPressure : 16|16@1+ (0.0009765625,0) [0|62.7490234375] "MPa" Vector__XXX
 SG_ EngnClndr2LwFrqnKnkLvl : 48|8@1+ (1,0) [0|250] "%" Vector__XXX
 SG_ EngnClndr2MxmmPrssrInrsRt : 56|8@1+ (16,0) [0|4000] "kPa/deg crank angle" Vector__XXX
 SG_ EngnClndr2SnhrnsKnkLvl : 32|8@1+ (1,0) [0|250] "%" Vector__XXX
 SG_ EngnClndr2PrssrSnsrPrlmnrFm : 40|5@1+ (1,0) [0|31] "" Vector__XXX

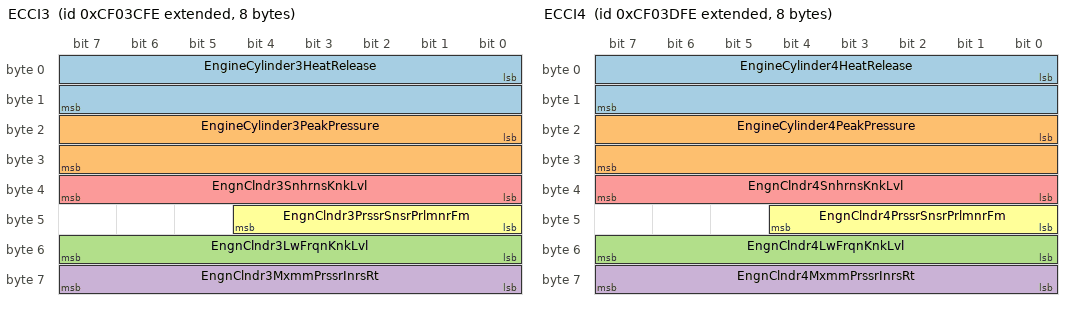
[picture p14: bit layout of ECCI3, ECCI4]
BO_ 2364554494 ECCI3: 8 Vector__XXX
 SG_ EngineCylinder3HeatRelease : 0|16@1+ (0.0001220703125,-1) [-1|6.8436279296875] "kJ/l" Vector__XXX
 SG_ EngineCylinder3PeakPressure : 16|16@1+ (0.0009765625,0) [0|62.7490234375] "MPa" Vector__XXX
 SG_ EngnClndr3LwFrqnKnkLvl : 48|8@1+ (1,0) [0|250] "%" Vector__XXX
 SG_ EngnClndr3MxmmPrssrInrsRt : 56|8@1+ (16,0) [0|4000] "kPa/deg crank angle" Vector__XXX
 SG_ EngnClndr3SnhrnsKnkLvl : 32|8@1+ (1,0) [0|250] "%" Vector__XXX
 SG_ EngnClndr3PrssrSnsrPrlmnrFm : 40|5@1+ (1,0) [0|31] "" Vector__XXX

BO_ 2364554750 ECCI4: 8 Vector__XXX
 SG_ EngineCylinder4HeatRelease : 0|16@1+ (0.0001220703125,-1) [-1|6.8436279296875] "kJ/l" Vector__XXX
 SG_ EngineCylinder4PeakPressure : 16|16@1+ (0.0009765625,0) [0|62.7490234375] "MPa" Vector__XXX
 SG_ EngnClndr4LwFrqnKnkLvl : 48|8@1+ (1,0) [0|250] "%" Vector__XXX
 SG_ EngnClndr4MxmmPrssrInrsRt : 56|8@1+ (16,0) [0|4000] "kPa/deg crank angle" Vector__XXX
 SG_ EngnClndr4SnhrnsKnkLvl : 32|8@1+ (1,0) [0|250] "%" Vector__XXX
 SG_ EngnClndr4PrssrSnsrPrlmnrFm : 40|5@1+ (1,0) [0|31] "" Vector__XXX

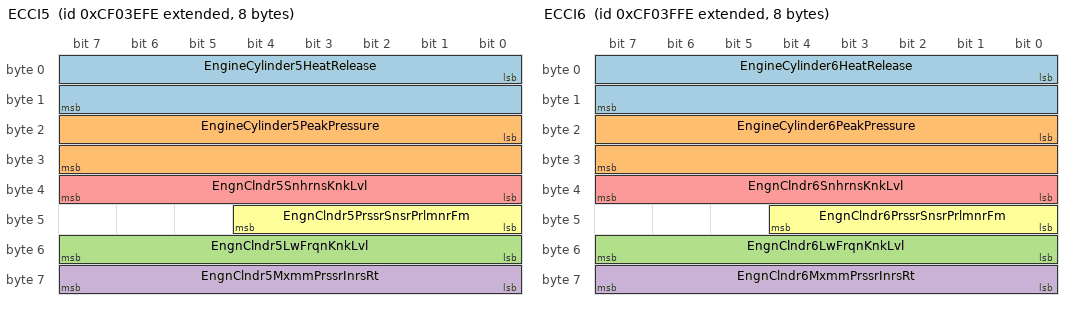
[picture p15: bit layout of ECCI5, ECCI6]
BO_ 2364555006 ECCI5: 8 Vector__XXX
 SG_ EngineCylinder5HeatRelease : 0|16@1+ (0.0001220703125,-1) [-1|6.8436279296875] "kJ/l" Vector__XXX
 SG_ EngineCylinder5PeakPressure : 16|16@1+ (0.0009765625,0) [0|62.7490234375] "MPa" Vector__XXX
 SG_ EngnClndr5LwFrqnKnkLvl : 48|8@1+ (1,0) [0|250] "%" Vector__XXX
 SG_ EngnClndr5MxmmPrssrInrsRt : 56|8@1+ (16,0) [0|4000] "kPa/deg crank angle" Vector__XXX
 SG_ EngnClndr5SnhrnsKnkLvl : 32|8@1+ (1,0) [0|250] "%" Vector__XXX
 SG_ EngnClndr5PrssrSnsrPrlmnrFm : 40|5@1+ (1,0) [0|31] "" Vector__XXX

BO_ 2364555262 ECCI6: 8 Vector__XXX
 SG_ EngineCylinder6HeatRelease : 0|16@1+ (0.0001220703125,-1) [-1|6.8436279296875] "kJ/l" Vector__XXX
 SG_ EngineCylinder6PeakPressure : 16|16@1+ (0.0009765625,0) [0|62.7490234375] "MPa" Vector__XXX
 SG_ EngnClndr6LwFrqnKnkLvl : 48|8@1+ (1,0) [0|250] "%" Vector__XXX
 SG_ EngnClndr6MxmmPrssrInrsRt : 56|8@1+ (16,0) [0|4000] "kPa/deg crank angle" Vector__XXX
 SG_ EngnClndr6SnhrnsKnkLvl : 32|8@1+ (1,0) [0|250] "%" Vector__XXX
 SG_ EngnClndr6PrssrSnsrPrlmnrFm : 40|5@1+ (1,0) [0|31] "" Vector__XXX

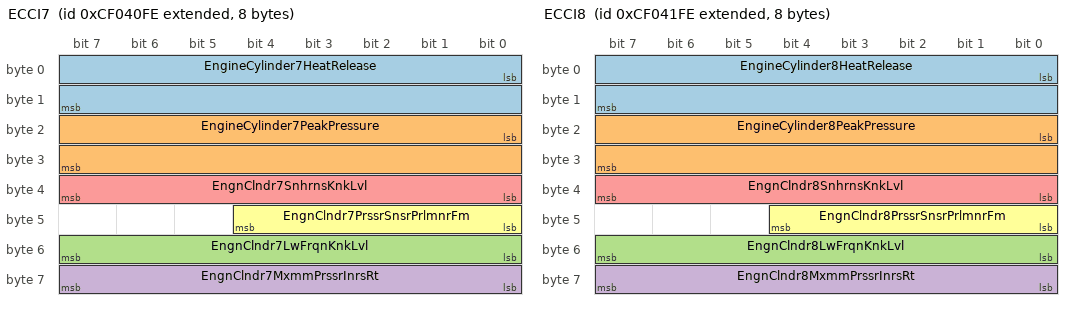
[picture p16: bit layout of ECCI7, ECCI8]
BO_ 2364555518 ECCI7: 8 Vector__XXX
 SG_ EngineCylinder7HeatRelease : 0|16@1+ (0.0001220703125,-1) [-1|6.8436279296875] "kJ/l" Vector__XXX
 SG_ EngineCylinder7PeakPressure : 16|16@1+ (0.0009765625,0) [0|62.7490234375] "MPa" Vector__XXX
 SG_ EngnClndr7LwFrqnKnkLvl : 48|8@1+ (1,0) [0|250] "%" Vector__XXX
 SG_ EngnClndr7MxmmPrssrInrsRt : 56|8@1+ (16,0) [0|4000] "kPa/deg crank angle" Vector__XXX
 SG_ EngnClndr7SnhrnsKnkLvl : 32|8@1+ (1,0) [0|250] "%" Vector__XXX
 SG_ EngnClndr7PrssrSnsrPrlmnrFm : 40|5@1+ (1,0) [0|31] "" Vector__XXX

BO_ 2364555774 ECCI8: 8 Vector__XXX
 SG_ EngineCylinder8HeatRelease : 0|16@1+ (0.0001220703125,-1) [-1|6.8436279296875] "kJ/l" Vector__XXX
 SG_ EngineCylinder8PeakPressure : 16|16@1+ (0.0009765625,0) [0|62.7490234375] "MPa" Vector__XXX
 SG_ EngnClndr8LwFrqnKnkLvl : 48|8@1+ (1,0) [0|250] "%" Vector__XXX
 SG_ EngnClndr8MxmmPrssrInrsRt : 56|8@1+ (16,0) [0|4000] "kPa/deg crank angle" Vector__XXX
 SG_ EngnClndr8SnhrnsKnkLvl : 32|8@1+ (1,0) [0|250] "%" Vector__XXX
 SG_ EngnClndr8PrssrSnsrPrlmnrFm : 40|5@1+ (1,0) [0|31] "" Vector__XXX

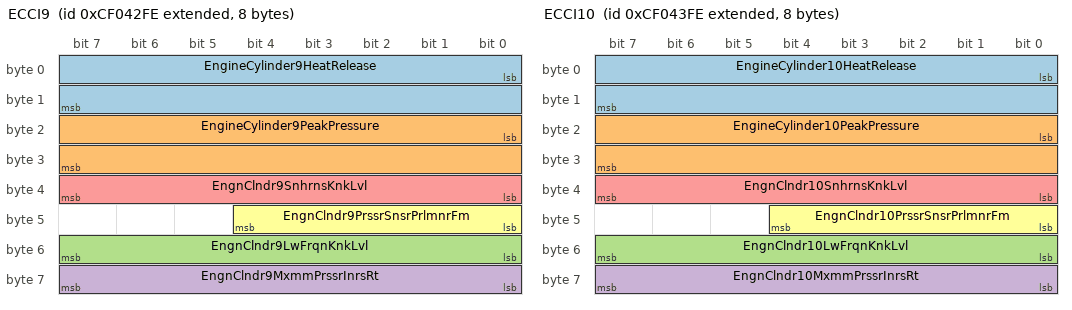
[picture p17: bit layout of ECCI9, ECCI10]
BO_ 2364556030 ECCI9: 8 Vector__XXX
 SG_ EngineCylinder9HeatRelease : 0|16@1+ (0.0001220703125,-1) [-1|6.8436279296875] "kJ/l" Vector__XXX
 SG_ EngineCylinder9PeakPressure : 16|16@1+ (0.0009765625,0) [0|62.7490234375] "MPa" Vector__XXX
 SG_ EngnClndr9LwFrqnKnkLvl : 48|8@1+ (1,0) [0|250] "%" Vector__XXX
 SG_ EngnClndr9MxmmPrssrInrsRt : 56|8@1+ (16,0) [0|4000] "kPa/deg crank angle" Vector__XXX
 SG_ EngnClndr9SnhrnsKnkLvl : 32|8@1+ (1,0) [0|250] "%" Vector__XXX
 SG_ EngnClndr9PrssrSnsrPrlmnrFm : 40|5@1+ (1,0) [0|31] "" Vector__XXX

BO_ 2364556286 ECCI10: 8 Vector__XXX
 SG_ EngineCylinder10HeatRelease : 0|16@1+ (0.0001220703125,-1) [-1|6.8436279296875] "kJ/l" Vector__XXX
 SG_ EngineCylinder10PeakPressure : 16|16@1+ (0.0009765625,0) [0|62.7490234375] "MPa" Vector__XXX
 SG_ EngnClndr10LwFrqnKnkLvl : 48|8@1+ (1,0) [0|250] "%" Vector__XXX
 SG_ EngnClndr10MxmmPrssrInrsRt : 56|8@1+ (16,0) [0|4000] "kPa/deg crank angle" Vector__XXX
 SG_ EngnClndr10SnhrnsKnkLvl : 32|8@1+ (1,0) [0|250] "%" Vector__XXX
 SG_ EngnClndr10PrssrSnsrPrlmnrFm : 40|5@1+ (1,0) [0|31] "" Vector__XXX

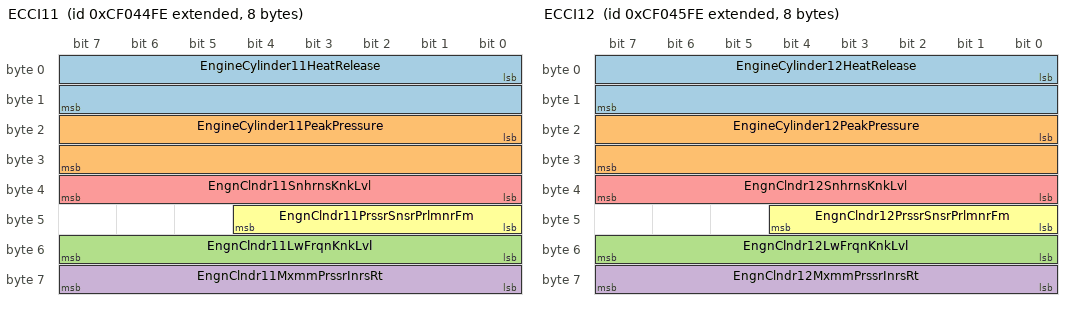
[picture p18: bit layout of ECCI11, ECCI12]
BO_ 2364556542 ECCI11: 8 Vector__XXX
 SG_ EngineCylinder11HeatRelease : 0|16@1+ (0.0001220703125,-1) [-1|6.8436279296875] "kJ/l" Vector__XXX
 SG_ EngineCylinder11PeakPressure : 16|16@1+ (0.0009765625,0) [0|62.7490234375] "MPa" Vector__XXX
 SG_ EngnClndr11LwFrqnKnkLvl : 48|8@1+ (1,0) [0|250] "%" Vector__XXX
 SG_ EngnClndr11MxmmPrssrInrsRt : 56|8@1+ (16,0) [0|4000] "kPa/deg crank angle" Vector__XXX
 SG_ EngnClndr11SnhrnsKnkLvl : 32|8@1+ (1,0) [0|250] "%" Vector__XXX
 SG_ EngnClndr11PrssrSnsrPrlmnrFm : 40|5@1+ (1,0) [0|31] "" Vector__XXX

BO_ 2364556798 ECCI12: 8 Vector__XXX
 SG_ EngineCylinder12HeatRelease : 0|16@1+ (0.0001220703125,-1) [-1|6.8436279296875] "kJ/l" Vector__XXX
 SG_ EngineCylinder12PeakPressure : 16|16@1+ (0.0009765625,0) [0|62.7490234375] "MPa" Vector__XXX
 SG_ EngnClndr12LwFrqnKnkLvl : 48|8@1+ (1,0) [0|250] "%" Vector__XXX
 SG_ EngnClndr12MxmmPrssrInrsRt : 56|8@1+ (16,0) [0|4000] "kPa/deg crank angle" Vector__XXX
 SG_ EngnClndr12SnhrnsKnkLvl : 32|8@1+ (1,0) [0|250] "%" Vector__XXX
 SG_ EngnClndr12PrssrSnsrPrlmnrFm : 40|5@1+ (1,0) [0|31] "" Vector__XXX

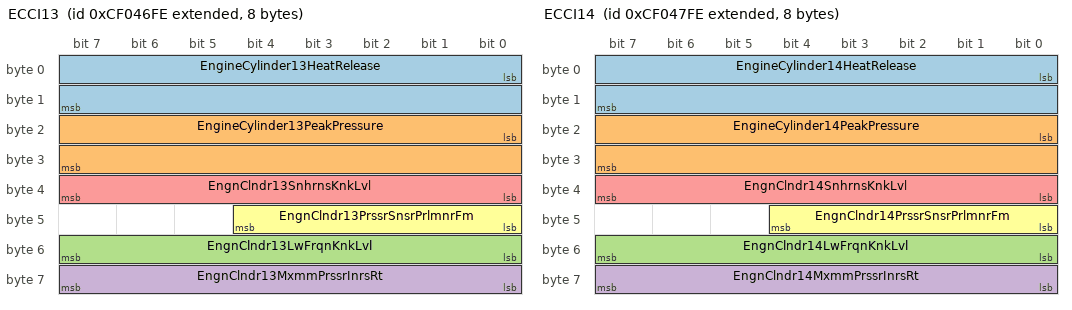
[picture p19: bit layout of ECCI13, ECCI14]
BO_ 2364557054 ECCI13: 8 Vector__XXX
 SG_ EngineCylinder13HeatRelease : 0|16@1+ (0.0001220703125,-1) [-1|6.8436279296875] "kJ/l" Vector__XXX
 SG_ EngineCylinder13PeakPressure : 16|16@1+ (0.0009765625,0) [0|62.7490234375] "MPa" Vector__XXX
 SG_ EngnClndr13LwFrqnKnkLvl : 48|8@1+ (1,0) [0|250] "%" Vector__XXX
 SG_ EngnClndr13MxmmPrssrInrsRt : 56|8@1+ (16,0) [0|4000] "kPa/deg crank angle" Vector__XXX
 SG_ EngnClndr13SnhrnsKnkLvl : 32|8@1+ (1,0) [0|250] "%" Vector__XXX
 SG_ EngnClndr13PrssrSnsrPrlmnrFm : 40|5@1+ (1,0) [0|31] "" Vector__XXX

BO_ 2364557310 ECCI14: 8 Vector__XXX
 SG_ EngineCylinder14HeatRelease : 0|16@1+ (0.0001220703125,-1) [-1|6.8436279296875] "kJ/l" Vector__XXX
 SG_ EngineCylinder14PeakPressure : 16|16@1+ (0.0009765625,0) [0|62.7490234375] "MPa" Vector__XXX
 SG_ EngnClndr14LwFrqnKnkLvl : 48|8@1+ (1,0) [0|250] "%" Vector__XXX
 SG_ EngnClndr14MxmmPrssrInrsRt : 56|8@1+ (16,0) [0|4000] "kPa/deg crank angle" Vector__XXX
 SG_ EngnClndr14SnhrnsKnkLvl : 32|8@1+ (1,0) [0|250] "%" Vector__XXX
 SG_ EngnClndr14PrssrSnsrPrlmnrFm : 40|5@1+ (1,0) [0|31] "" Vector__XXX

BO_ 2364557566 ECCI15: 8 Vector__XXX
 SG_ EngineCylinder15HeatRelease : 0|16@1+ (0.0001220703125,-1) [-1|6.8436279296875] "kJ/l" Vector__XXX
 SG_ EngineCylinder15PeakPressure : 16|16@1+ (0.0009765625,0) [0|62.7490234375] "MPa" Vector__XXX
 SG_ EngnClndr15LwFrqnKnkLvl : 48|8@1+ (1,0) [0|250] "%" Vector__XXX
 SG_ EngnClndr15MxmmPrssrInrsRt : 56|8@1+ (16,0) [0|4000] "kPa/deg crank angle" Vector__XXX
 SG_ EngnClndr15SnhrnsKnkLvl : 32|8@1+ (1,0) [0|250] "%" Vector__XXX
 SG_ EngnClndr15PrssrSnsrPrlmnrFm : 40|5@1+ (1,0) [0|31] "" Vector__XXX

CM_ BO_ 2163223550 "Crash Notification";
CM_ SG_ 2163223550 CrashChecksum "Crash Checksum: The Crash Checksum is used to verify the signal path from the airbag ECU to other devices in case of a crash.The 4 bit checksum is the sum of the high nibble and the low nibble of the sum of the identifier, the first 7 data bytes and ...";
CM_ SG_ 2163223550 CrashCounter "Crash Counter: The Crash Counter prevents other ECUs from reacting to a faulty transmission of the Crash Notification PG and serves as a safety mechanism. The Crash Counter becomes incremented by 1 for every sent message, and wraps around to 0 when t...";
CM_ SG_ 2163223550 CrashType "Crash Type: Type of crash event. 00000b = no crash00001b = frontal crash00010b = rear crash00100b = side crash (left)01000b = side crash (right)10000b = rolloverIt is possible to combine different Crash Types. (e.g. frontal and side crash (left) = 00...";
CM_ BO_ 2230333950 "Wand Sensor";
CM_ SG_ 2230333950 WandAngle "Wand Angle: A wand sensor measures the angle of deflection of a wand from its null position. This parameter reports the measured angle of a wand sensor.";
CM_ SG_ 2230333950 WandSensorFigureOfMerit "Wand Sensor Figure of Merit: Figure of Merit sensor status for a wand sensor.00b = Sensor fully functional01b = Sensor degraded10b = Sensor failed11b = Sensor not available";
CM_ BO_ 2230334206 "Linear Displacement Sensor";
CM_ SG_ 2230334206 MeasuredLinearDisplacement "Measured Linear Displacement: Distance to target as measured by the Linear Displacement Sensor.";
CM_ SG_ 2230334206 LnrDsplmntSnsrSnsrFgrOfMrt "Linear Displacement Sensor Sensor Figure of Merit: Figure of Merit sensor status of Linear Displacement Sensor.00b = Sensor fully functional01b = Sensor degraded10b = Sensor failed11b = Sensor not available";
CM_ BO_ 2297441534 "Magnet Status Information 2";
CM_ SG_ 2297441534 DropRelayControl "Drop Relay Control: Command signal used to Engage and Disengage the Drop Relay controlling a Steady-State Magnet.00b = Off, Disable Drop Relay Request01b = On, Enable Drop Relay Request10b = Reserved11b = Take No Action";
CM_ SG_ 2297441534 GnrtrCrrntBstAtvStts "Generator Current Boost Active Status: Status of generator current boost relay that can boost the generator output current for picking-up material operations. When this relay is on, the generator is generating the maximum current for the material han...";
CM_ SG_ 2297441534 LiftRelayControl "Lift Relay Control: Command signal used to Engage and Disengage the Lift Relay controlling a Steady-State Magnet.00b = Off, Disable Lift Relay Request 01b = On, Enable Lift Relay Request10b = Reserved11b = Take No Action";
CM_ SG_ 2297441534 MagnetForwardCurrent "Magnet Forward Current: The forward current being supplied by the generator to the electric magnet to create a magnet field to lift material.";
CM_ SG_ 2297441534 MagnetGeneratorControl "Magnet Generator Control: Command signal used to Enable and Disable the Generator controlling a Magnet.00b = Off, Disable Generator01b = On, Enable Generator10b = Reserved11b = Take No Action";
CM_ SG_ 2297441534 MagnetReverseCurrent "Magnet Reverse Current: A reverse current being supplied to the electric magnet to reduce the forward current generated magnet field as quick as possible so that the magnet can release material as fast as possible.";
CM_ SG_ 2297441534 MaterialDropActiveStatus "Material Drop Active Status: The status of Material Drop Relay. When it is on, the generator generates reverse direction current so that the material handler machine can release material.00b = Off01b = On10b = Error11b = Not Available";
CM_ SG_ 2297441534 MaterialDropSwitch "Material Drop Switch: This is a switch that can be used to enable the drop functionality of the Material Handler machine.00b = Don't Drop01b = Drop10b = Error11b = Not Available";
CM_ SG_ 2297441534 MaterialLiftActiveStatus "Material Lift Active Status: The status of Material Lift Relay. When it is on, the generator generates forward direction current so that the material handler machine can pick up material.00b = Off01b = On10b = Error11b = Not Available";
CM_ SG_ 2297441534 MaterialLiftSwitch "Material Lift Switch: This is a switch that can be used to enable the lift functionality of the Material Handler machine. When it is activated, the magnet is energized to pick up material.00b = Don't Lift01b = Lift10b = Error11b = Not Available...";
CM_ BO_ 2297441790 "Acceleration Sensor";
CM_ SG_ 2297441790 LngtdnlAlrtnExtnddRng "Longitudinal Acceleration (Extended Range): Indicates longitudinal acceleration of the vehicle (the component of vehicle acceleration vector along the X-axis).  A positive longitudinal acceleration signal results when the vehicle speed increases in t...";
CM_ SG_ 2297441790 LtrlAlrtnExtnddRng "Lateral Acceleration (Extended Range): Indicates lateral acceleration of the vehicle (the component of vehicle acceleration vector along the Y-axis).  A positive lateral acceleration signal results when the vehicle is accelerated to the left.  This p...";
CM_ SG_ 2297441790 VrtlAlrtnExtnddRng "Vertical Acceleration (Extended Range): Indicates vertical acceleration of the vehicle and the effect of gravity (the component of vehicle acceleration vector along the Z-axis).  A positive vertical acceleration signal of 1 gravity results when the v...";
CM_ SG_ 2297441790 LtrlAlrtnFgrOfMrtExtnddRng "Lateral Acceleration Figure of Merit (Extended Range): Figure of merit for lateral acceleration measurement.00b = lateral acceleration is fully functional.  Data is within sensor specification01b = lateral acceleration is degraded.  Data is suspect d...";
CM_ SG_ 2297441790 LngtdnlAlrtnFgrOfMrtExtnddRng "Longitudinal Acceleration Figure of Merit (Extended Range): Figure of merit for longitudinal acceleration measurement.00b = longitudinal acceleration is fully functional.  Data is within sensor specification01b = longitudinal acceleration is degraded...";
CM_ SG_ 2297441790 VrtlAlrtnFgrOfMrtExtnddRng "Vertical Acceleration Figure of Merit (Extended Range): Figure of merit for vertical acceleration measurement.00b = vertical acceleration is fully functional.  Data is within sensor specification01b = verticalacceleration is degraded.  Data is suspec...";
CM_ SG_ 2297441790 SpptVTsssRpttRtFAtSs "Support Variable Transmission Repetition Rate for Acceleration Sensor: Indicates which acceleration transmission rate are supported by the ECU in addition to the required 10 ms transmission rate.00b = Reserve for SAE assignment01b = Reserved for SAE ...";
CM_ BO_ 2297455358 "Electronic Transmission Controller #12";
CM_ SG_ 2297455358 TrnsmssnDrtnlOtptShftSpd "Transmission Directional Output Shaft Speed: The rotational velocity and direction of the output shaft. Positive values are used for forward vehicle motion, negative values for reverse vehicle motion.SPN 191 should be used when direction is not used....";
CM_ SG_ 2297455358 TrnsmssnHdrsttLp1Prssr "Transmission Hydrostatic Loop 1 Pressure: Oil pressure in the transmission hydrostatic loop #1 between the pump and motor.";
CM_ SG_ 2297455358 TrnsmssnHdrsttLp2Prssr "Transmission Hydrostatic Loop 2 Pressure: Oil pressure in the transmission hydrostatic loop #2 between the pump and motor.";
CM_ SG_ 2297455358 TrnsmssnIntrmdtShftSpd "Transmission Intermediate Shaft Speed: Rotational velocity of the first intermediate shaft of the transmission.";
CM_ BO_ 2297499902 "Brakes 2";
CM_ SG_ 2297499902 BrakePedalSwitch2 "Brake Pedal Switch 2: Second switch signal instance which indicates that the driver operated brake foot pedal is being pressed. This parameter is functionally equivalent to SPN 597, but derived from a second, independent sensor and may be used where ...";
CM_ SG_ 2297499902 DmnddBrkAppltnPrssr "Demanded Brake Application Pressure: Gage pressure of the compressed air or fluid in the vehicle braking system that is used to apply brake shoes (or pads) against the brake drums (or discs). This is the brake application pressure demanded by the veh...";
CM_ BO_ 2298375934 "High Resolution Wheel Speed";
CM_ SG_ 2298375934 FrontAxleLeftWheelSpeed "Front Axle, Left Wheel Speed: High resolution measurement of the speed of the left wheel on the front axle.";
CM_ SG_ 2298375934 FrontAxleRightWheelSpeed "Front axle, right wheel speed: High resolution measurement of the speed of the right wheel on the front axle.";
CM_ SG_ 2298375934 RearAxleLeftWheelSpeed "Rear axle, left wheel speed: High resolution measurement of the speed of the left wheel on the rear axle.";
CM_ SG_ 2298375934 RearAxleRightWheelSpeed "Rear axle, right wheel speed: High resolution measurement of the speed of the right wheel on the rear axle.";
CM_ BO_ 2348941054 "Transmission Control 1";
CM_ SG_ 2348941054 DisengageDrivelineRequest "Disengage Driveline Request: Command signal used to simply disengage the driveline, e.g., to prevent engine drag torque from causing high wheel slip on slippery surfaces.00b = Allow driveline engagement01b = Disengage driveline10b = Reserved11b = Tak...";
CM_ SG_ 2348941054 DsnggDffrntlLkRqstCntrl "Disengage Differential Lock Request - Central: Command parameter used to disengage the various differential locks, e.g., to allow an undistributed individual wheel control by ABS.  The differential locks are located as defined in Figure SPN564_A.00b ...";
CM_ SG_ 2348941054 DsnggDffrntlLkRqstCntrlFrnt "Disengage Differential Lock Request - Central Front: Command parameter used to disengage the various differential locks, e.g., to allow an undistributed individual wheel control by ABS.  The differential locks are located as defined in Figure SPN564_...";
CM_ SG_ 2348941054 DsnggDffrntlLkRqstCntrlRr "Disengage Differential Lock Request - Central Rear: Command parameter used to disengage the various differential locks, e.g., to allow an undistributed individual wheel control by ABS.  The differential locks are located as defined in Figure SPN564_A...";
CM_ SG_ 2348941054 DsnggDffrntlLkRqstFrntAxl1 "Disengage Differential Lock Request - Front Axle 1: Command parameter used to disengage the various differential locks, e.g., to allow an undistributed individual wheel control by ABS.  The differential locks are located as defined in Figure SPN564_A...";
CM_ SG_ 2348941054 DsnggDffrntlLkRqstFrntAxl2 "Disengage Differential Lock Request - Front Axle 2: Command parameter used to disengage the various differential locks, e.g., to allow an undistributed individual wheel control by ABS.  The differential locks are located as defined in Figure SPN564_A...";
CM_ SG_ 2348941054 DsnggDffrntlLkRqstRrAxl1 "Disengage Differential Lock Request - Rear Axle 1: Command parameter used to disengage the various differential locks, e.g., to allow an undistributed individual wheel control by ABS.  The differential locks are located as defined in Figure SPN564_A....";
CM_ SG_ 2348941054 DsnggDffrntlLkRqstRrAxl2 "Disengage Differential Lock Request - Rear Axle 2: Command parameter used to disengage the various differential locks, e.g., to allow an undistributed individual wheel control by ABS.  The differential locks are located as defined in Figure SPN564_A....";
CM_ SG_ 2348941054 RequestedPercentClutchSlip "Requested Percent Clutch Slip: Parameter which represents the percent clutch slip requested by a device.";
CM_ SG_ 2348941054 TransmissionMode1 "Transmission Mode 1: Indicates whether transmission mode 1 is enabled.  Modes are manufacturer specific and are not necessarily mutually exclusive.  See also SPN 2536.00b = Disable01b = Enable10b = Reserved11b = Take no action";
CM_ SG_ 2348941054 TransmissionMode2 "Transmission Mode 2: Indicates whether transmission mode 2 is enabled.  Modes are manufacturer specific and are not necessarily mutually exclusive.  See also SPN 2537.00b = Disable01b = Enable10b = Reserved11b = Take no action";
CM_ SG_ 2348941054 TransmissionMode3 "Transmission Mode 3: Indicates whether transmission mode 3 is enabled.  Modes are manufacturer specific and are not necessarily mutually exclusive.  See also SPN 2538.00b = Disable01b = Enable10b = Reserved11b = Take no action";
CM_ SG_ 2348941054 TransmissionMode4 "Transmission Mode 4: Indicates whether transmission mode 4 is enabled.  Modes are manufacturer specific and are not necessarily mutually exclusive.  See also SPN 2539.00b = Disable01b = Enable10b = Reserved11b = Take no action";
CM_ SG_ 2348941054 TransmissionMode5 "Transmission Mode 5: Indicates whether transmission mode 5 is enabled. Modes are manufacturer specific and are not necessarily mutually exclusive. See also SPN 4250.00b = Disable01b = Enable10b = Reserved11b = Take no action";
CM_ SG_ 2348941054 TransmissionMode6 "Transmission Mode 6: Indicates whether transmission mode 6 is enabled. Modes are manufacturer specific and are not necessarily mutually exclusive. See also SPN 4251.00b = Disable01b = Enable10b = Reserved11b = Take no action";
CM_ SG_ 2348941054 TransmissionMode7 "Transmission Mode 7: Indicates whether transmission mode 7 is enabled. Modes are manufacturer specific and are not necessarily mutually exclusive. See also SPN 4252.00b = Disable01b = Enable10b = Reserved11b = Take no action";
CM_ SG_ 2348941054 TransmissionMode8 "Transmission Mode 8: Indicates whether transmission mode 8 is enabled. Modes are manufacturer specific and are not necessarily mutually exclusive. See also SPN 4253.00b = Disable01b = Enable10b = Reserved11b = Take no action";
CM_ SG_ 2348941054 TransmissionRequestedGear "Transmission Requested Gear: Gear requested by the operator, ABS, or engine.Negative values are reverse gears, positive values are forward gears, zero is neutral, parameter specific indicators are listed below.Parameter specific values for this param...";
CM_ SG_ 2348941054 TransmissionRequestedLaunchGear "Transmission Requested Launch Gear: Initial gear for the transmission to start out in when the vehicle is launched from a standing stop, as specified by the vehicle operator or vehicle system. Automatic transmissions typically default to starting out...";
CM_ SG_ 2348941054 TrnsmssnAtNtrlMnlRtrnRqst "Transmission Auto-Neutral (Manual Return) Request: This parameter conveys a vehicle system desire to override the operator's current shift selector request (e.g. Drive, Reverse) and shift the transmission into Neutral. Manual Return indicates this pa...";
CM_ SG_ 2348941054 TrnsmssnGrShftInhtRqst "Transmission Gear Shift Inhibit Request: Command signal to inhibit gear shifts.00b = Gear shifts are allowed  (disable function)01b = Gear shifts are inhibited  (enable function)10b = Reserved11b = Take no action  (leave function as is)";
CM_ SG_ 2348941054 TrnsmssnLdRdtnInhtRqst "Transmission Load Reduction Inhibit Request: Request signal to the transmission to inhibit activation of load reduction functions.Automatic transmissions may incorporate functions designed to reduce engine load during certain operating conditions (ve...";
CM_ SG_ 2348941054 TrnsmssnRvrsGrShftInhtRqst "Transmission Reverse Gear Shift Inhibit Request: Allows devices external to the normal transmission shift selector system to request the transmission to inhibit shifts into any Reverse gear and force the transmission into Neutral if it is currently i...";
CM_ SG_ 2348941054 TrnsmssnShftSltrDsplMdSwth "Transmission Shift Selector Display Mode Switch: Status of the operator's switch used to 'toggle' through multiple display modes of a shift selector display.  When a shift selector display is capable of displaying more than just range information, th...";
CM_ SG_ 2348941054 TrnsmssnTrqCnvrtrLkpRqst "Transmission Torque Converter Lockup Request: Command signal to override normal transmission control of the torque converter lockup clutch. This command may be used to control lockup as needed for different operating modes or environmental conditions...";
CM_ BO_ 2349137662 "External Brake Request";
CM_ SG_ 2349137662 ExternalAccelerationDemand "External Acceleration Demand: Parameter provided to the brake system from external sources. This is the acceleration which the brake system is expected to realize. It is specified as an absolute acceleration in reference to the road.  Positive values...";
CM_ SG_ 2349137662 XbrControlMode "XBR Control Mode: The XBR Control Mode is used as an input to the brake system and defines how the external acceleration demand has to be realized.00b = Override disabled - Disable any existing control commanded by the source of this command.01b = Ac...";
CM_ SG_ 2349137662 XbrEbiMode "XBR EBI Mode: The XBR EBI (Endurance Brake Integration) Mode is used as an input for the brake system to prescribe the use of endurance brakes like retarders or engine brakes.00b = No Endurance Brake Integration allowedThe demanded acceleration must ...";
CM_ SG_ 2349137662 XbrMessageChecksum "XBR Message Checksum: The XBR message checksum is used to verify the signal path from the demanding device to the brake controller on electronic brake systems.  The support of this parameter is mandatory if PGN 1024 is supported as there is no means ...";
CM_ SG_ 2349137662 XbrMessageCounter "XBR Message Counter: The XBR message counter is to verify the signal path from the demanding device to the brake controller on electronic brake systems..  The support of this parameter is mandatory.Note:  The initial value of the 4 bit message counte...";
CM_ SG_ 2349137662 XbrPriority "XBR Priority: The XBR Priority is used as an input to the brake system to manage the priority of overlapping external and internal requests.00b = Highest priority - used for emergency situations, e.g. for future Collision Avoidance System.  This mode...";
CM_ SG_ 2349137662 XbrUrgency "XBR urgency: The idea of the urgency value is to adjust the endurance brake integration behavior in the EBS system according to the traffic situation.On low urgency values (0%, e.g. downhill cruise control or preceding vehicle far ahead) the brake sy...";
CM_ SG_ 2349137662 XbrCompensationMode "XBR Compensation Mode: The parameter indicates whether the XBR request is a request for retardation (deceleration caused by braking) only, i.e. without the brake system making any compensations for other known sources of deceleration that it can calc...";
CM_ SG_ 2349137662 XbrBrakeHoldRequest "XBR Brake Hold Request: This parameter is used by external sources to request the brake system to hold the vehicle still using service brakes.00b = Brake Hold not requested01b = Brake Hold requested10b = Reserved11b = Not available";
CM_ SG_ 2349137662 XbrReason "XBR Reason: This state indicates the reason of the sending device for the XBR command.XBR Reason is not in prioritized order. Not all modes may be relevant for a given device. Some devices may not implement all control modes.XBR Reason is not intende...";
CM_ BO_ 2349399806 "Auxiliary Input/Output Status 5";
CM_ SG_ 2349399806 AuxiliaryIOChannel3 "Auxiliary I/O Channel #3: Identifies the current value of auxiliary input/output channels that are configured uniquely per application.";
CM_ SG_ 2349399806 AuxiliaryIOChannel4 "Auxiliary I/O Channel #4: Identifies the current value of auxiliary input/output channels that are configured uniquely per application.";
CM_ SG_ 2349399806 AuxiliaryIOChannel5 "Auxiliary I/O Channel #5: Identifies the current value of auxiliary input/output channels that are configured uniquely per application.";
CM_ SG_ 2349399806 AuxiliaryIOChannel6 "Auxiliary I/O Channel #6: Identifies the current value of auxiliary input/output channels that are configured uniquely per application.";
CM_ BO_ 2349465342 "Static Roll Angle Sensor Information";
CM_ SG_ 2349465342 StaticRollAngle "Static Roll Angle: The measured static roll angle between the vehicle y-axis and the ground plane about the X-axis.  The sign of the roll angle is determined in accordance to the right-hand rule about the X-axis, as specified in SAE J670.  Roll angle...";
CM_ SG_ 2349465342 StaticRollAngleStatus "Static Roll Angle Status: Status of the transmitted roll angle data.000b = Sensor Busy001b = Sensor OK010b = Sensor Defect011b = Sensor Reboots100b = Angle Data Invalid101b = Reserved110b = Error111b = Not available";
CM_ BO_ 2349530878 "Cruise Control / Vehicle Speed 2";
CM_ SG_ 2349530878 CruiseControlDisableCommand "Cruise Control Disable Command: This parameter is used to disable cruise control from a source other than the driver controlled switch if cruise control is active.  It is also used to inhibit cruise control from becoming active if it is not currently...";
CM_ SG_ 2349530878 CruiseControlPauseCommand "Cruise Control Pause Command: This parameter is used to temporarily disable cruise control from a source other than the driver controlled switch if cruise control is active.  If this parameter is used to disable cruise control, then cruise control wi...";
CM_ SG_ 2349530878 CruiseControlResumeCommand "Cruise Control Resume Command: This parameter is used to request the cruise control to resume operation from a source other than the driver controlled switch.  Implementers may wish to restrict the conditions in which cruise control will be resumed d...";
CM_ SG_ 2349530878 IdleControlEnableState "Idle Control Enable State: Indicates whether enabling conditions (switch position, park brake, transmission neutral status, etc.) have been met for an idle speed request. Similar to a cruise control enable switch, this parameter does not activate the...";
CM_ SG_ 2349530878 IdleControlRequestActivation "Idle Control Request Activation: Indicates whether the idle speed request (SPN 8438) should be honored. This parameter does not inhibit or apply to Engine Operator Primary Intermediate Speed Select (SPN 2880).00b = Idle speed request is not active01b...";
CM_ SG_ 2349530878 IdleSpeedRequest "Idle Speed Request: Requested idle speed. Allows an operator or ECU to modify the engine idle setpoint within a range supported by the engine. Requests above or below the supported range should result in a speed at the limit of the supported range. S...";
CM_ SG_ 2349530878 CruiseControlSetCommand "Cruise Control Set Command: Used to set the cruise control speed from a source other than the driver controlled switch when Cruise Control Enable Switch (SPN 596) is ON and Cruise Control Disable Command (SPN 5603), if supported, indicates allowed.Se...";
CM_ SG_ 2349530878 RemoteVehicleSpeedLimitRequest "Remote Vehicle Speed Limit Request: Indicates a request to temporarily limit the maximum vehicle speed.  The value is sent from a body builder platform or other vehicle system.As this request may be used to fulfill regulatory purposes, it shall overr...";
CM_ BO_ 2349596414 "Advanced Emergency Braking System 2";
CM_ SG_ 2349596414 Aebs2MessageChecksum "AEBS2 message checksum: Used to check the message checksum of the transmitting (HMI) unit within the AEBS2 system.For SAE J1939-21 implementations, the Message ID is the classic CAN indentifier.For SAE J1939-22 implementations, the Message ID content...";
CM_ SG_ 2349596414 Aebs2MessageCounter "AEBS2 message Counter: The message counter is increased with every transmitted AEBS2 message.  After reaching a value of Fh the next value will be 0.";
CM_ SG_ 2349596414 DvAtvtDdFAdvdEBSst "Driver activation demand for Advanced Emergency Braking System: According to the Vienna world convention on road traffic the driver must be provided with means to deactivate an Advanced Emergency Braking System. This command is to be transmitted from...";
CM_ BO_ 2349727486 "Transmission Control 2";
CM_ SG_ 2349727486 TransmissionMode10 "Transmission Mode 10: Indicates whether transmission mode 10 is enabled. Modes are manufacturer specific and are not necessarily mutually exclusive. See also SPN 6568. 00b = Disable01b = Enable10b = Reserved11b = Take no action";
CM_ SG_ 2349727486 TransmissionMode9 "Transmission Mode 9: Indicates whether transmission mode 9 is enabled. Modes are manufacturer specific and are not necessarily mutually exclusive. See also SPN 6567. 00b = Disable01b = Enable10b = Reserved11b = Take no action";
CM_ SG_ 2349727486 TrnsmssnPrDfndMxmmGrAtvtnRqst "Transmission Pre-Defined Maximum Gear Activation Request: This parameter requests that the transmission not operate in ranges above a pre-defined or calibrated range as configured in the transmission or other controller. For example, this parameter c...";
CM_ SG_ 2349727486 TrnsmssnOtptShftBrkRqst "Transmission Output Shaft Brake Request: This parameter requests that the transmission apply either internal or external braking systems for the purpose of stopping output shaft rotation. Such action is typically used to facilitate engagement of spli...";
CM_ SG_ 2349727486 TrnsmssnRqstdRvrsLnhGr "Transmission Requested Reverse Launch Gear: Initial Reverse gear for the transmission to start out in when the vehicle is launched from a standing stop, as specified by the vehicle operator or vehicle system. Automatic transmissions typically default...";
CM_ SG_ 2349727486 SltdMxmmGrLmtAtvtnRqst "Selected Maximum Gear Limit Activation Request: When this parameter transitions from 00b to 01b, the transmission will set a maximum gear limit that is equal to the current operating gear. This limit only applies to the current operating direction, i...";
CM_ SG_ 2349727486 TransmissionMode11 "Transmission Mode 11: Indicates whether transmission mode 11 is enabled.  Modes are manufacturer specific and are not necessarily mutually exclusive.  See also SPN 12939.00b = Disable01b = Enable10b = Reserved11b = Take no action";
CM_ SG_ 2349727486 TransmissionMode12 "Transmission Mode 12: Indicates whether transmission mode 12 is enabled.  Modes are manufacturer specific and are not necessarily mutually exclusive.  See also SPN 12940.00b = Disable01b = Enable10b = Reserved11b = Take no action";
CM_ SG_ 2349727486 TransmissionMode13 "Transmission Mode 13: Indicates whether transmission mode 13 is enabled.  Modes are manufacturer specific and are not necessarily mutually exclusive.  See also SPN 12941.00b = Disable01b = Enable10b = Reserved11b = Take no action";
CM_ SG_ 2349727486 TransmissionMode14 "Transmission Mode 14: Indicates whether transmission mode 14 is enabled.  Modes are manufacturer specific and are not necessarily mutually exclusive.  See also SPN 12942.00b = Disable01b = Enable10b = Reserved11b = Take no action";
CM_ SG_ 2349727486 TransmissionMode15 "Transmission Mode 15: Indicates whether transmission mode 15 is enabled.  Modes are manufacturer specific and are not necessarily mutually exclusive.  See also SPN 12943.00b = Disable01b = Enable10b = Reserved11b = Take no action";
CM_ SG_ 2349727486 TransmissionMode16 "Transmission Mode 16: Indicates whether transmission mode 16 is enabled.  Modes are manufacturer specific and are not necessarily mutually exclusive.  See also SPN 12944.00b = Disable01b = Enable10b = Reserved11b = Take no action";
CM_ SG_ 2349727486 TransmissionMode17 "Transmission Mode 17: Indicates whether transmission mode 17 is enabled.  Modes are manufacturer specific and are not necessarily mutually exclusive.  See also SPN 12945.00b = Disable01b = Enable10b = Reserved11b = Take no action";
CM_ SG_ 2349727486 TransmissionMode18 "Transmission Mode 18: Indicates whether transmission mode 18 is enabled.  Modes are manufacturer specific and are not necessarily mutually exclusive.  See also SPN 12946.00b = Disable01b = Enable10b = Reserved11b = Take no action";
CM_ SG_ 2349727486 TransmissionMode19 "Transmission Mode 19: Indicates whether transmission mode 19 is enabled.  Modes are manufacturer specific and are not necessarily mutually exclusive.  See also SPN 12947.00b = Disable01b = Enable10b = Reserved11b = Take no action";
CM_ SG_ 2349727486 TransmissionMode20 "Transmission Mode 20: Indicates whether transmission mode 20 is enabled.  Modes are manufacturer specific and are not necessarily mutually exclusive.  See also SPN 12948.00b = Disable01b = Enable10b = Reserved11b = Take no action";
CM_ SG_ 2349727486 DsnggDffrntlLkRqstRrAxl3 "Disengage Differential Lock Request - Rear Axle 3: Command parameter used to disengage the various differential locks, e.g., to allow an undistributed individual wheel control by ABS. The differential locks are located as defined in Figure SPN 564.  ...";
CM_ SG_ 2349727486 TrnsmssnCstMdDslRqst "Transmission Coast Mode Disable Request: Parameter indicates the desire of the operator or other vehicle system to disable Transmission Coast Mode, a function where the transmission internally disconnects from the driveline in order to reduce engine ...";
CM_ SG_ 2349727486 TrnsmssnExpltMnlMdRqst "Transmission Explicit Manual Mode Request: This input expresses operator or vehicle system desire for the transmission to operate in an explicit manual mode, where the transmission will only shift from the current range when explicitly directed to do...";
CM_ BO_ 2350644990 "High Voltage Energy Storage System Control 1";
CM_ SG_ 2350644990 HvessPowerDownCommand "HVESS Power-Down Command: Command to shut down the High Voltage Energy Storage System (or Pack 1 in systems with only one pack).  A normal power-down may involve steps that take some period of time (tests, writing of data, etc.).  However, an emergen...";
CM_ SG_ 2350644990 HvessCellBalancingCommand "HVESS Cell Balancing Command: Command for the High Voltage Energy Storage System (or Pack 1 in systems with only one pack) to perform cell balancing.This parameter provides HVES system level information. If there are multiple packs in the system, the...";
CM_ SG_ 2350644990 HvessOperationConsent "HVESS Operation Consent: This parameter provides an indication to the High Voltage Energy Storage System (or Pack 1 in systems with only one pack) that an external device is ready for this HVES instance to proceed with normal operation.  In applicati...";
CM_ SG_ 2350644990 HvessControl1Counter "HVESS Control 1 Counter: The message counter is used to detect situations where the transmitting ECU malfunction repeats the same frame all the time. The receiver of the information may use the counter parameter to detect this situation. The transmit...";
CM_ SG_ 2350644990 HvessControl1Crc "HVESS Control 1 CRC: The CRC is defined as follows: - Length: 8 bits- Polynomial: x^8+x^5+x^3+x^2+x+1- Initial Value: FFh- Input Data Reflection: Not reflected- Result Data Reflection: Not reflected- XOR value: FFh SAE makes no claim of the functiona...";
CM_ SG_ 2350644990 HvssHghVltgBsCnntCmmnd "HVESS High-Voltage Bus Connect Command: Command to connect the High Voltage Energy Storage System (or Pack 1 in systems with only one pack) to the high-voltage bus.  The emergency contactor closure request may be used in situations where one or more ...";
CM_ SG_ 2350644990 HvssHghVltgBsAtvIsltnTstCmmnd "HVESS High-Voltage Bus Active Isolation Test Command: Command for the High Voltage Energy Storage System (or Pack 1 in systems with only one pack) to perform an active electrical isolation test on the high voltage bus.An active isolation test might u...";
CM_ SG_ 2350644990 HvssHghVltgBsPssvIsltnTstCmmnd "HVESS High-Voltage Bus Passive Isolation Test Command: Command for the High Voltage Energy Storage System (or Pack 1 in systems with only one pack) to perform a passive electrical isolation test on the high voltage bus.A passive isolation test uses a...";
CM_ SG_ 2350644990 HvssEnlIntrnlChrgrCmmnd "HVESS Enable Internal Charger Command: When the HVES has an internal charger this parameter will enable it.   External chargers may use the External Energy Source Connection Demand (SPN 7890) and related SPs.This parameter provides HVES system level ...";
CM_ SG_ 2350644990 HvssHghVltgBsHghSdRsstrCnntRqst "HVESS High-Voltage Bus High Side Resistor Connect Request: This parameter is used to request connection of this HVES instance High-Voltage bus high side resistor in order to perform an isolation test.  See also SPN 8434  (HVESS High-Voltage Bus Low S...";
CM_ SG_ 2350644990 HvssHghVltgBsLwSdRsstrCnntRqst "HVESS High-Voltage Bus Low Side Resistor Connect Request: This parameter is used to request connection of this HVES instance High-Voltage bus low side resistor in order to perform an isolation test.  See also SPN 8433  (HVESS Low-Voltage Bus High Sid...";
CM_ SG_ 2350644990 HvssThrmlMngmntMntnnRqst "HVESS Thermal Management Maintenance Request: Request to engage Thermal Management Maintenance Mode for the High Voltage Energy Storage System (or Pack 1 in systems with only one pack).   00b = HVESS Thermal Management Maintenance Mode is not request...";
CM_ BO_ 2350710526 "Transmission Control 3 (Obsolete, see PGN 16896)";
CM_ SG_ 2350710526 TsssOvdCtMdOstUsSp23369 "Transmission Override Control Mode (obsolete, use SPN 23369): The override control mode defines the type of control mode used to control transmission operation.00b = Override disabled - Disable any existing control commanded by the source of this com...";
CM_ SG_ 2350710526 TsssOvdCtMdPtOstUsSp23370 "Transmission Override Control Mode Priority (obsolete, use SPN 23370): This field is used as an input to the transmission to determine the priority of the Override Control Mode received in the Torque/Speed Control message.  The default is 11b (Low pr...";
CM_ SG_ 2350710526 MssgCntrOsltUsSpn23375 "Message Counter (obsolete, use SPN 23375): The message counter is used to detect situations where the transmitting ECU malfunction repeats the same frame all the time.  The receiver of the information may use the counter parameter to detect this situ...";
CM_ SG_ 2350710526 TsssRqstdOtptStSpdOstUsSp23371 "Transmission Requested Output Shaft Speed (obsolete, use SPN 23371): Used to request output shaft speed of the transmission which has a output through a driveline to the wheels of a machine/vehicle.";
CM_ SG_ 2350710526 TsssRqstdTqTqLtOstUsSp23372 "Transmission Requested Torque / Torque Limit (obsolete, use SPN 23372): Requested transmission output torque measured as a percentage of Transmission Reference Torque (SPN 7778). This is the output torque at which the transmission is expected to oper...";
CM_ SG_ 2350710526 TsssAtNtAtRtESwtOstUsSp23373 "Transmission Auto-Neutral (Auto-Return) Enable Switch (obsolete, use SPN 23373): This enable switch is required for use with interfaces using SPN 21252 [Transmission Auto-Neutral (Auto-Return) Request].  It allows the operator to prohibit the transmi...";
CM_ SG_ 2350710526 TsssAtNtAtRtRqstOstUsSp23374 "Transmission Auto-Neutral (Auto-Return) Request (obsolete, use SPN 23374): This parameter conveys a vehicle system desire to (a) override the operator's current shift selector request (e.g. Drive, Reverse) and shift the transmission into Neutral, and...";
CM_ SG_ 2350710526 MssgChksmOsltUsSpn23376 "Message Checksum (obsolete, use SPN 23376): The message checksum is used to verify the signal path from the transmitting device to the receiving device. The message checksum is calculated using the first 7 data bytes, the message counter and the byte...";
CM_ BO_ 2350776062 "Engine Ignition Controller";
CM_ SG_ 2350776062 EngineTimingAdvance "Engine Timing Advance: Ignition timing as a command to the ignition control module.  Positive values command an increasingly advanced timing from TDC. The same timing applies to all cylinders. Use SPN 7356 - SPN 7379 for cylinder specific timing offs...";
CM_ BO_ 2350841598 "Alternator Control";
CM_ SG_ 2350841598 AlternatorTorqueRampTimeCommand "Alternator Torque Ramp Time Command: Sets the torque ramp rate in which the alternator can respond to a change in electrical load. 100% represents the reference engine torque (SPN 544). This value will be applied if the alternator speed is less than ...";
CM_ SG_ 2350841598 AltrntrExttnMxmmCrrntLmt "Alternator Excitation Maximum Current Limit: Command sent to alternator to set the maximum excitation current of the alternator.";
CM_ SG_ 2350841598 AltrntrStpntVltgCmmnd "Alternator Setpoint Voltage Command: Setpoint voltage command to alternator. The setpoint voltage is the point that is regulated by the alternator. This may or may not be the output of the alternator.";
CM_ SG_ 2350841598 AltrntrTrqRmpMxmmSpdCmmnd "Alternator Torque Ramp Maximum Speed Command: The Alternator Torque Ramp Time Command (SPN 7591) is applied if the alternator speed is less than Alternator Torque Ramp Maximum Speed Command (SPN 7592). If the alternator speed is greater than Alternat...";
CM_ BO_ 2358902526 "Joystick Lamp Command Message";
CM_ SG_ 2358902526 Joystick1Lamp10Command "Joystick 1 Lamp 10 Command: Tells joystick 1 to switch on/off/blinking lamp 10.00b = Off01b = On10b = Blinking11b = Don't care / Take no action";
CM_ SG_ 2358902526 Joystick1Lamp1Command "Joystick 1 Lamp 1 Command: Tells joystick 1 to switch on/off/blinking lamp 1.00b = Off01b = On10b = Blinking11b = Don't care / Take no action";
CM_ SG_ 2358902526 Joystick1Lamp2Command "Joystick 1 Lamp 2 Command: Tells joystick 1 to switch on/off/blinking lamp 2.00b = Off01b = On10b = Blinking11b = Don't care / Take no action";
CM_ SG_ 2358902526 Joystick1Lamp3Command "Joystick 1 Lamp 3 Command: Tells joystick 1 to switch on/off/blinking lamp 3.00b = Off01b = On10b = Blinking11b = Don't care / Take no action";
CM_ SG_ 2358902526 Joystick1Lamp4Command "Joystick 1 Lamp 4 Command: Tells joystick 1 to switch on/off/blinking lamp 4.00b = Off01b = On10b = Blinking11b = Don't care / Take no action";
CM_ SG_ 2358902526 Joystick1Lamp5Command "Joystick 1 Lamp 5 Command: Tells joystick 1 to switch on/off/blinking lamp 5.00b = Off01b = On10b = Blinking11b = Don't care / Take no action";
CM_ SG_ 2358902526 Joystick1Lamp6Command "Joystick 1 Lamp 6 Command: Tells joystick 1 to switch on/off/blinking lamp 6.00b = Off01b = On10b = Blinking11b = Don't care / Take no action";
CM_ SG_ 2358902526 Joystick1Lamp7Command "Joystick 1 Lamp 7 Command: Tells joystick 1 to switch on/off/blinking lamp 7.00b = Off01b = On10b = Blinking11b = Don't care / Take no action";
CM_ SG_ 2358902526 Joystick1Lamp8Command "Joystick 1 Lamp 8 Command: Tells joystick 1 to switch on/off/blinking lamp 8.00b = Off01b = On10b = Blinking11b = Don't care / Take no action";
CM_ SG_ 2358902526 Joystick1Lamp9Command "Joystick 1 Lamp 9 Command: Tells joystick 1 to switch on/off/blinking lamp 9.00b = Off01b = On10b = Blinking11b = Don't care / Take no action";
CM_ SG_ 2358902526 Joystick2Lamp10Command "Joystick 2 Lamp 10 Command: Tells joystick 2 to switch on/off/blinking lamp 10.00b = Off01b = On10b = Blinking11b = Don't care / Take no action";
CM_ SG_ 2358902526 Joystick2Lamp1Command "Joystick 2 Lamp 1 Command: Tells joystick 2 to switch on/off/blinking lamp 1.00b = Off01b = On10b = Blinking11b = Don't care / Take no action";
CM_ SG_ 2358902526 Joystick2Lamp2Command "Joystick 2 Lamp 2 Command: Tells joystick 2 to switch on/off/blinking lamp 2.00b = Off01b = On10b = Blinking11b = Don't care / Take no action";
CM_ SG_ 2358902526 Joystick2Lamp3Command "Joystick 2 Lamp 3 Command: Tells joystick 2 to switch on/off/blinking lamp 3.00b = Off01b = On10b = Blinking11b = Don't care / Take no action";
CM_ SG_ 2358902526 Joystick2Lamp4Command "Joystick 2 Lamp 4 Command: Tells joystick 2 to switch on/off/blinking lamp 4.00b = Off01b = On10b = Blinking11b = Don't care / Take no action";
CM_ SG_ 2358902526 Joystick2Lamp5Command "Joystick 2 Lamp 5 Command: Tells joystick 2 to switch on/off/blinking lamp 5.00b = Off01b = On10b = Blinking11b = Don't care / Take no action";
CM_ SG_ 2358902526 Joystick2Lamp6Command "Joystick 2 Lamp 6 Command: Tells joystick 2 to switch on/off/blinking lamp 6.00b = Off01b = On10b = Blinking11b = Don't care / Take no action";
CM_ SG_ 2358902526 Joystick2Lamp7Command "Joystick 2 Lamp 7 Command: Tells joystick 2 to switch on/off/blinking lamp 7.00b = Off01b = On10b = Blinking11b = Don't care / Take no action";
CM_ SG_ 2358902526 Joystick2Lamp8Command "Joystick 2 Lamp 8 Command: Tells joystick 2 to switch on/off/blinking lamp 8.00b = Off01b = On10b = Blinking11b = Don't care / Take no action";
CM_ SG_ 2358902526 Joystick2Lamp9Command "Joystick 2 Lamp 9 Command: Tells joystick 2 to switch on/off/blinking lamp 9.00b = Off01b = On10b = Blinking11b = Don't care / Take no action";
CM_ SG_ 2358902526 Joystick3Lamp10Command "Joystick 3 Lamp 10 Command: Tells joystick 3 to switch on/off/blinking lamp 10.00b = Off01b = On10b = Blinking11b = Don't care / Take no action";
CM_ SG_ 2358902526 Joystick3Lamp1Command "Joystick 3 Lamp 1 Command: Tells joystick 3 to switch on/off/blinking lamp 1.00b = Off01b = On10b = Blinking11b = Don't care / Take no action";
CM_ SG_ 2358902526 Joystick3Lamp2Command "Joystick 3 Lamp 2 Command: Tells joystick 3 to switch on/off/blinking lamp 2.00b = Off01b = On10b = Blinking11b = Don't care / Take no action";
CM_ SG_ 2358902526 Joystick3Lamp3Command "Joystick 3 Lamp 3 Command: Tells joystick 3 to switch on/off/blinking lamp 3.00b = Off01b = On10b = Blinking11b = Don't care / Take no action";
CM_ SG_ 2358902526 Joystick3Lamp4Command "Joystick 3 Lamp 4 Command: Tells joystick 3 to switch on/off/blinking lamp 4.00b = Off01b = On10b = Blinking11b = Don't care / Take no action";
CM_ SG_ 2358902526 Joystick3Lamp5Command "Joystick 3 Lamp 5 Command: Tells joystick 3 to switch on/off/blinking lamp 5.00b = Off01b = On10b = Blinking11b = Don't care / Take no action";
CM_ SG_ 2358902526 Joystick3Lamp6Command "Joystick 3 Lamp 6 Command: Tells joystick 3 to switch on/off/blinking lamp 6.00b = Off01b = On10b = Blinking11b = Don't care / Take no action";
CM_ SG_ 2358902526 Joystick3Lamp7Command "Joystick 3 Lamp 7 Command: Tells joystick 3 to switch on/off/blinking lamp 7.00b = Off01b = On10b = Blinking11b = Don't care / Take no action";
CM_ SG_ 2358902526 Joystick3Lamp8Command "Joystick 3 Lamp 8 Command: Tells joystick 3 to switch on/off/blinking lamp 8.00b = Off01b = On10b = Blinking11b = Don't care / Take no action";
CM_ SG_ 2358902526 Joystick3Lamp9Command "Joystick 3 Lamp 9 Command: Tells joystick 3 to switch on/off/blinking lamp 9.00b = Off01b = On10b = Blinking11b = Don't care / Take no action";
CM_ BO_ 2362572542 "Air Suspension Control 6";
CM_ SG_ 2362572542 LevelPresetFrontAxleLeft "Level Preset Front Axle Left: Set value for nominal level 'preset level' at the left side of the front axle. This value is referred to 'Normal level 1'.  For explanations of normal level 1 see parameter SPN 1734 - Nominal Level Front Axle.";
CM_ SG_ 2362572542 LevelPresetFrontAxleRight "Level Preset Front Axle Right: Set value for nominal level 'preset level' at the right side of the front axle. This value is referred to 'Normal level 1'.  For explanations of normal level 1 see SPN 1734 - Nominal Level Front Axle.";
CM_ SG_ 2362572542 LevelPresetRearAxleLeft "Level Preset Rear Axle Left: Set value for nominal level 'preset level' at the left side of the rear axle. This value is referred to 'Normal level 1'.  For explanations of normal level 1 see SPN 1734 - Nominal Level Front Axle.";
CM_ SG_ 2362572542 LevelPresetRearAxleRight "Level Preset Rear Axle Right: Set value for nominal level 'preset level' at the right side of the rear axle. This value is referred to 'Normal level 1'.  For explanations of normal level 1 see SPN 1734 - Nominal Level Front Axle.";
CM_ BO_ 2362638078 "Air Suspension Control 2";
CM_ SG_ 2362638078 AllwLvlCntrlDrngBrkngCmmnd "Allow Level Control During Braking Command: This parameter overides the inhibit of level control during braking.00b = Disallow level control during braking (normal operation)01b = Allow level control during braking10b = Reserved11b = Don't' care/take...";
CM_ SG_ 2362638078 AtmtTrtnHlpLdTrnsfr "Automatic traction help (load transfer): This signal enables the traction help (load transfer) in case of an active ASR function00b = Disable automatic traction help 01b = Enable automatic traction help 10b = Reserved11b = Don't care";
CM_ SG_ 2362638078 DamperStiffnessRequestFrontAxle "Damper Stiffness Request Front Axle: Demand value for the shock absorber control at the front axle.";
CM_ SG_ 2362638078 DamperStiffnessRequestRearAxle "Damper Stiffness Request Rear Axle: Demand value for the shock absorber control at the rear  axle.";
CM_ SG_ 2362638078 DmprStffnssRqstLftTgAxl "Damper Stiffness Request Lift / Tag Axle: Demand value for the shock absorber control at the lift or tag axle";
CM_ SG_ 2362638078 KneelingCommandFrontAxle "Kneeling Command - Front Axle: Command signal to activate the kneeling functionality at the front axle of the vehicle00b = Deactivate kneeling01b = Activate kneeling10b = Reserved11b = Don't care/take no action";
CM_ SG_ 2362638078 KneelingCommandRearAxle "Kneeling Command - Rear Axle: Command signal to activate the kneeling functionality at the rear axle of the vehicle.00b = Deactivate kneeling01b = Activate kneeling10b = Reserved11b = Don't care/take no action";
CM_ SG_ 2362638078 KneelingControlModeRequest "Kneeling Control Mode Request: Command signal to select the kneeling functionality00b = Automatically actuated01b = Manually actuated10b = Reserved11b = Don't care/take no action";
CM_ SG_ 2362638078 KneelingRequestLeftSide "Kneeling Request Left Side: Command signal to activate the kneeling functionality on the left side of the vehicle00b = No kneeling request01b = Kneeling request10b = Reserved11b = Don't care/take no action";
CM_ SG_ 2362638078 KneelingRequestRightSide "Kneeling Request Right Side: Command signal to activate the kneeling functionality on the right side of the vehicle00b = No kneeling request01b = Kneeling request10b = Reserved11b = Don't care/take no action";
CM_ SG_ 2362638078 LevelControlModeRequest "Level Control Mode Request: Command signal to activate a level control mode0000b = Normal operation; i.e. the system performs a pure control of the vehicle height0001b = Traction help (load transfer); i.e. the driven axle is loaded to a maximum value...";
CM_ SG_ 2362638078 LiftAxle1PositionCommand "Lift Axle 1 Position Command: Signal to command the position/load condition of lift/tag axle #1.  Numbering of lift/tag axles starts at front axle.00b = Lift axle position down / tag axle laden01b = Lift axle position up / tag axle unladen10b = Reser...";
CM_ SG_ 2362638078 LiftAxle2PositionCommand "Lift Axle 2 Position Command: Signal to command the position / load condition of lift / tag axle #2.  Numbering of lift/tag axles starts at front axle.00b = Lift axle position down / tag axle laden01b = Lift axle position up / tag axle unladen10b = R...";
CM_ SG_ 2362638078 MemoryLevelRequest "Memory level request: Signal which indicates that the air suspension control requests a memory level or a memory level shall be stored.The storage of  the current memory level is requested by  Store memory level x. The acknowledge is set in memory le...";
CM_ SG_ 2362638078 NominalLevelRequestFrontAxle "Nominal Level Request Front Axle: Command signal to activate a level of the front axle programmed and/or memorized in the ECU   For explanations of nominal level see SPN 1734 - Nominal Level Front Axle.0000b = No level request0001b = Normal Level 1,(...";
CM_ SG_ 2362638078 NominalLevelRequestRearAxle "Nominal Level Request Rear Axle: Command signal to activate a level of the rear axle programmed and/or memorized in the ECU.  For explanations of nominal level see SPN 1734 - Nominal Level Front Axle.0000b = No level request0001b = Normal Level 1,(i....";
CM_ SG_ 2362638078 PrhtAtmtArSspnsnCntrl "Prohibit Automatic Air Suspension Control: This parameter is an internal request to the air suspension control system to prohibit automatic air suspension control.  If the request is accepted,  response intended to be sent in  ASC1 (additional status...";
CM_ SG_ 2362638078 ProhibitAirSuspensionControl "Prohibit air suspension control: This parameter is an external request to the air suspension control system to prohibit all air suspension control.  If the request is accepted,  response intended to be sent in  ASC1 (additional status requested in AS...";
CM_ SG_ 2362638078 SpdDpndntLvlCntrlRqst "Speed Dependent Level Control Request: This parameter activates speed dependent level control in suspension system.00b = Deactivate01b = Activate10b = Reserved11b = Don't care/take no action";
CM_ BO_ 2364539646 "Electronic Transmission Controller 1";
CM_ SG_ 2364539646 EngineMomentaryOverspeedEnable "Engine Momentary Overspeed Enable: Command signal used to indicate that the engine speed may be boosted up to the maximum engine overspeed value to accommodate transmission downshifts.  The maximum time for overspeed is limited by the time defined in...";
CM_ SG_ 2364539646 MmntrEngnMxmmPwrEnl "Momentary Engine Maximum Power Enable: Momentarily Requesting highest torque map from the engine control00b = not requesting maximum power available01b = momentarily requesting maximum power available10b = fault11b = not available";
CM_ SG_ 2364539646 PercentClutchSlip "Percent Clutch Slip: Parameter which represents the ratio of input shaft speed to current engine speed (in percent).Percent Clutch Slip = ((Engine rpm - Input shaft rpm)/(Engine rpm)) x 100";
CM_ SG_ 2364539646 ProgressiveShiftDisable "Progressive Shift Disable: Command signal used to indicate that progressive shifting by the engine should be disallowed.00b = Progressive shift is not disabled01b = Progressive shift is disabled10b = Reserved11b = Take no action";
CM_ SG_ 2364539646 TransmissionDrivelineEngaged "Transmission Driveline Engaged: Driveline engaged indicates the transmission controlled portion of the driveline is engaged sufficiently to allow a transfer of torque through the transmission.  Driveline engaged is ACTIVE whenever the transmission is...";
CM_ SG_ 2364539646 TransmissionShiftInProcess "Transmission Shift In Process: Indicates that the transmission is in process of shifting from the current gear to the selected gear. This state is generally ACTIVE during the entire time that the transmission controls the vehicle during a shift. This...";
CM_ SG_ 2364539646 TrnsmssnTrqCnvrtrLkpEnggd "Transmission Torque Converter Lockup Engaged: State signal which indicates whether the torque converter lockup is engaged.00b = Torque converter lockup disengaged01b = Torque converter lockup engaged10b = Error11b = Not available";
CM_ SG_ 2364539646 TsssTqCvtLpTstIPss "Transmission Torque Converter Lockup Transition in Process: State signal indicating whether or not the transmission torque converter lock up clutch is transitioning between being applied and being released.  The broadcast value should be set to 01b a...";
CM_ SG_ 2364539646 SAddssOCtDvFTsssCt "Source Address of Controlling Device for Transmission Control: The source address of the SAE J1939 device currently controlling the transmission. Its value may be the source address of the ECU transmitting the message (which means that no external SA...";
CM_ SG_ 2364539646 TransmissionOutputShaftSpeed "Transmission Output Shaft Speed: Calculated speed of the transmission output shaft.Note on SP use by multiple controller applications:A vehicle with multiple physical transmissions may broadcast instances of this PG from different controller applicat...";
CM_ SG_ 2364539646 TransmissionInputShaftSpeed "Transmission Input Shaft Speed: Rotational velocity of the primary shaft transferring power into the transmission.  When a torque converter is present, it is the output of the torque converter.Notes Relating to DCT (Dual Clutch Transmission) applicat...";
CM_ BO_ 2364539902 "Electronic Engine Controller 2";
CM_ SG_ 2364539902 AcceleratorPedal1LowIdleSwitch "Accelerator Pedal 1 Low Idle Switch: Switch signal which indicates the state of the accelerator pedal 1 low idle switch.  The low idle switch is defined in SAE Recommended Practice J1843.00b = Accelerator pedal 1 not in low idle condition01b = Accele...";
CM_ SG_ 2364539902 AcceleratorPedal2LowIdleSwitch "Accelerator Pedal 2 Low Idle Switch: Switch signal which indicates the state of the accelerator pedal 2 low idle switch.  The low idle switch is defined in SAE J1843.00b = Accelerator pedal 2 not in low idle condition01b = Accelerator pedal 2 in low ...";
CM_ SG_ 2364539902 AcceleratorPedalKickdownSwitch "Accelerator Pedal Kickdown Switch: Switch signal which indicates whether the accelerator pedal kickdown switch is opened or closed.  The kickdown switch is defined in SAE J1843.00b = Kickdown passive01b = Kickdown active10b = Error11b = Not available...";
CM_ SG_ 2364539902 AtlMxmmAvllEngnPrntTrq "Actual Maximum Available Engine - Percent Torque: This is the maximum amount of torque that the engine can immediately deliver as a percentage of the reference engine torque (SPN 544).  The Actual Maximum Available Engine - Percent Torque shall take ...";
CM_ SG_ 2364539902 DpfThermalManagementActive "DPF Thermal Management Active: Indicates that the exhaust temperatures have been elevated for regeneration of the diesel particulate filter aftertreatment system or in preparation of regeneration of the diesel particulate aftertreatment system.00b = ...";
CM_ SG_ 2364539902 EnginePercentLoadAtCurrentSpeed "Engine Percent Load At Current Speed: The ratio of actual engine percent torque (indicated) to maximum indicated torque available at the current engine speed, clipped to zero torque during engine braking.";
CM_ SG_ 2364539902 EstimatedPumpingPercentTorque "Estimated Pumping - Percent Torque: The calculated torque that indicates the estimated amount of torque loss due to the engine air handling system. The value transmitted in this parameter is included in SPN 514 (Nominal Friction - Percent Torque).  T...";
CM_ SG_ 2364539902 MmntrEngnMxmmPwrEnlFdk "Momentary Engine Maximum Power Enable Feedback: Momentarily requesting Engine Maximum Power Enable - feature support feedback00b = disabled01b = supported 10b = reserved11b = don't care";
CM_ SG_ 2364539902 RemoteAcceleratorPedalPosition "Remote Accelerator Pedal Position: The ratio of actual position of the remote analog engine speed/torque request input device (such as an accelerator pedal or throttle lever) to the maximum position of the input device.     For example, in on-highway...";
CM_ SG_ 2364539902 RoadSpeedLimitStatus "Road Speed Limit Status: Status (active or not active) of the system used to limit maximum vehicle velocity.00b = Active01b = Not Active10b = Error11b = Not availableNOTE - While somewhat inconsistent with other J1939 status parameters, the states de...";
CM_ SG_ 2364539902 ScrThermalManagementActive "SCR Thermal Management Active: Indicates that the exhaust temperatures have been elevated for regeneration of the SCR aftertreatment system or in preparation of regeneration of the SCR aftertreatment system.00b = SCR Thermal Management is not active0...";
CM_ SG_ 2364539902 VhlAlrtnRtLmtStts "Vehicle Acceleration Rate Limit Status: Status (active or not active) of the system used to limit maximum forward vehicle acceleration.00b = Limit not active01b = Limit active10b = Reserved11b = Not availableNOTE:  The effects of emission control lim...";
CM_ SG_ 2364539902 AcceleratorPedal2Position "Accelerator Pedal 2 Position: The ratio of actual position of the second analog engine speed/torque request input device (such as an accelerator pedal or throttle lever) to the maximum position of the input device.  This parameter is intended for sec...";
CM_ SG_ 2364539902 AcceleratorPedal1Position "Accelerator Pedal 1 Position: This parameter is intended for the primary accelerator control in an application. SPN 91 is the calculated ratio of actual position of the operator's [engine] speed request or [engine] torque request input device (most c...";
CM_ BO_ 2364540158 "Electronic Engine Controller 1";
CM_ SG_ 2364540158 ActualEnginePercentTorque "Actual Engine - Percent Torque: The calculated output torque of the engine.  The data is transmitted in indicated torque as a percent of reference engine torque (see the engine configuration message, PGN 65251).  The engine percent torque value will ...";
CM_ SG_ 2364540158 AtlEngnPrntTrqFrtnl "Actual Engine - Percent Torque (Fractional): This parameter displays an additional torque in percent of the reference engine torque. When the MSB is set to 1, this parameter is not available.  When the MSB is set to 0, bits 1 to 3 indicate the desire...";
CM_ SG_ 2364540158 DrvrSDmndEngnPrntTrq "Driver's Demand Engine - Percent Torque: The requested torque output of the engine by the driver. It is based on input from the following requestors external to the powertrain: operator (via the accelerator pedal), cruise control and/or road speed li...";
CM_ SG_ 2364540158 EngineSpeed "Engine Speed: Actual engine speed which is calculated over a minimum crankshaft angle of 720 degrees divided by the number of cylinders.";
CM_ SG_ 2364540158 EngineStarterMode "Engine Starter Mode: There are several phases in a starting action and different reasons why a start cannot take place.0000b = start not requested0001b = starter active but not engaged0010b = starter active and engaged0011b = start finished; starter ...";
CM_ SG_ 2364540158 EngineTorqueMode "Engine Torque Mode: State signal which indicates which engine torque mode is currently generating, limiting, or controlling the torque.  Note that the modes are not in prioritized order. Not all modes may be relevant for a given device.  Some devices...";
CM_ SG_ 2364540158 EngineDemandPercentTorque "Engine Demand - Percent Torque: The requested torque output of the engine by all dynamic internal inputs, including smoke control, noise control and low and high speed governing.";
CM_ SG_ 2364540158 SrAddrssOfCntrllngDvFrEngnCntrl "Source Address of Controlling Device for Engine Control: The source address of the SAE J1939 device currently controlling the engine.  It is used to expand the torque mode parameter (see SPN 899) in cases where control is in response to an ECU that i...";
CM_ BO_ 2364541694 "Engine Gas Flow Rate 1";
CM_ SG_ 2364541694 EngineIntakeAirMassFlowRate "Engine Intake Air Mass Flow Rate: Mass flow rate of fresh air entering the engine air intake, before any EGR mixer, if used.  Flow rate of fresh air conducted to the engine cylinders to support combustion.  See SPN 23978 for alternate range and resol...";
CM_ SG_ 2364541694 EngnExhstGsRrltn1MssFlwRt "Engine Exhaust Gas Recirculation 1 Mass Flow Rate: Flow rate of gas through the EGR system. Flow rate of the exhaust gas being recirculated into the combustion air.";
CM_ SG_ 2364541694 EngnExhstGsRrltn2MssFlwRt "Engine Exhaust Gas Recirculation 2 Mass Flow Rate: Flow rate of gas through the second EGR system. Flow rate of the exhaust gas being recirculated from the 2nd EGR system into combustion air.";
CM_ SG_ 2364541694 TargetFreshAirMassFlow "Target Fresh Air Mass Flow: The intended mass flow rate of fresh air entering the engine air intake, before any EGR mixer, if used.";
CM_ BO_ 2364542206 "Electronic Transmission Controller #8";
CM_ SG_ 2364542206 TrnsmssnClthCnvrtrInptSpd "Transmission Clutch/Converter Input Speed: Rotational velocity of the input to a transmission's master clutch or torque converter. In most cases the rotational velocity will be the same as engine flywheel speed unless there is an intermediate device,...";
CM_ SG_ 2364542206 TrnsmssnTrqCnvrtrRt "Transmission Torque Converter Ratio: Ratio of the transmissions torque converter output torque to torque converter input torque at current speed.The ratio of 1.000 (03E8h) indicates torque converter lockup.If the ratio is less than 1 and the ratio ca...";
CM_ SG_ 2364542206 TransmissionShiftInhibitReason "Transmission Shift Inhibit Reason: Parameter indicates the reason that the requested transmission range shift is being prevented.In most circumstances, the 'Shift Inhibited' states will be enunciated after a shift request has been made that cannot be...";
CM_ SG_ 2364542206 TrnsmssnTrqCnvrtrLkpInhtRsn "Transmission Torque Converter Lockup Inhibit Reason: Parameter indicates the reason that transmission torque converter clutch lockup is being prevented.In most circumstances, the 'Lockup Inhibited' states will be enunciated after a lockup request has...";
CM_ SG_ 2364542206 TrnsmssnTrqCnvrtrLkpInhtIndtr "Transmission Torque Converter Lockup Inhibit Indicator: Parameter conveys a transmission request for the Torque Converter Lockup Inhibit Indicator to be active or inactive. The inhibit indicator can be of lamp or text form, located on (but not limite...";
CM_ SG_ 2364542206 TrnsmssnExpltMnlMdIndtr "Transmission Explicit Manual Mode Indicator: This parameter indicates if transmission is in an explicit Manual Mode as requested through SPN 23296 (Transmission Explicit Manual Mode Indicator Request). The transmission manufacturer may opt to maintai...";
CM_ BO_ 2364542462 "Land Leveling System Operational Information";
CM_ SG_ 2364542462 BladeAutoModeCommand "Blade Auto Mode Command: Allows other controllers to command to the primary control system what they think is the appropriate auto control mode to be engaged in, based on the information they have available to them.  When in automatic mode, the blade...";
CM_ SG_ 2364542462 BladeControlModeSwitch "Blade Control Mode Switch: Indicates the blade control mode switch state the user has set for the land leveling system.  The switch value directly correlates to the current switch state, regardless of the switch being used.  This parameter is intende...";
CM_ SG_ 2364542462 DesiredGradeOffsetSwitch "Desired Grade Offset Switch: Indicates the grade offset switch state the user has set for the land leveling system.  The desired grade offset value is the vertical offset measured from a given elevation reference point to the bottom edge of the blade...";
CM_ SG_ 2364542462 LftBldCntrlMdOprtrCntrl "Left Blade Control Mode Operator Control: This parameter indicates the left blade control mode operator control state the user has set for the land leveling system.  The operator control value directly relates to the current operator control state co...";
CM_ SG_ 2364542462 LftDsrdBldOffstOprtrCntrl "Left Desired Blade Offset Operator Control: This parameter indicates the left blade offset operator control state the user has set for the land leveling system.  The left desired blade offset value is the offset measured from a given reference point ...";
CM_ SG_ 2364542462 RghtBldCntrlMdOprtrCntrl "Right Blade Control Mode Operator Control: This parameter indicates the right blade control mode operator control state the user has set for the land leveling system.  The operator control value directly relates to the current operator control state ...";
CM_ SG_ 2364542462 RghtDsrdBldOffstOprtrCntrl "Right Desired Blade Offset Operator Control: This parameter indicates the right blade offset operator control state the user has set for the land leveling system.  The right desired blade offset value is the offset measured from a given reference poi...";
CM_ SG_ 2364542462 SdShftBldCntrlMdOprtrCntrl "Side-shift Blade Control Mode Operator Control: This parameter indicates the side-shift offset operator control state the user has set for the land leveling system. When an implement moves in a side-shift direction, it moves from side to side, usuall...";
CM_ SG_ 2364542462 SdShftDsrdBldOffstOprtrCntrl "Side-shift Desired Blade Offset Operator Control: This parameter indicates the side-shift blade control mode operator control state the user has set for the land leveling system.  When an implement moves in a side-shift direction, it moves from side ...";
CM_ SG_ 2364542462 StElvtnSnsr1RfrnElvtn "Set Elevation Sensor #1 Reference Elevation: Command from a display or other external device (i.e. remote switch) to the land leveling system controller instructing the controller to set the reference elevation based on data received from the corresp...";
CM_ SG_ 2364542462 StElvtnSnsr2RfrnElvtn "Set Elevation Sensor #2 Reference Elevation: Command from a display or other external device (i.e. remote switch) to the land leveling system controller instructing the controller to set the reference elevation based on data received from the corresp...";
CM_ BO_ 2364543998 "Slope Sensor Information";
CM_ SG_ 2364543998 PitchAndRollCompensated "Pitch and Roll Compensated: Compensated mode for the pitch and roll measurements.  Compensation is the use of multiple sensors together to enhance the output of pitch and roll measurements.00b = Compensation Off01b = Compensation On10b = Error11b = N...";
CM_ SG_ 2364543998 PitchAngle "Pitch Angle: The angle between the vehicle x-axis and the ground plane (i.e. rotation about the vehicle Y-axis).  The pitch angle for an angle of ascent is reported with a positive value. This parameter is defined according to a Z-Down axis system an...";
CM_ SG_ 2364543998 PitchAngleFigureOfMerit "Pitch Angle Figure of Merit: Figure of merit for pitch angle measurement.00b = Pitch angle fully functional.  Data is within sensor specification. 01b = Pitch angle degraded.  Data is suspect due to environmental conditions.10b = Error11b = Not avail...";
CM_ SG_ 2364543998 PitchRate "Pitch Rate: Pitch rate is the rate-of-change of the pitch angle over time, where the pitch angle vector is in the direction of travel of the vehicle. The pitch rate for increasing ascent over time is reported with a positive value. This parameter is ...";
CM_ SG_ 2364543998 PitchRateFigureOfMerit "Pitch Rate Figure of Merit: Figure of merit for the pitch rate measurement.00b = Pitch rate fully functional.  Data is within sensor specification.   01b = Pitch rate degraded.  Data is suspect due to environmental conditions.10b = Error11b = Not ava...";
CM_ SG_ 2364543998 RollAndPitchMeasurementLatency "Roll and Pitch Measurement Latency: The estimated measurement latency of the measurement.  NOTE: This is only the sensor latency and does not include any additional latencies that might exist because of the CAN Bus or overall system implementation. L...";
CM_ SG_ 2364543998 RollAngle "Roll Angle: The angle between the vehicle y-axis and the ground plane (i.e. rotation about the X-axis).  The roll angle for a roll to the right is reported with a positive value. Roll angle is the same for both Z-Down and Z-Up axis systems, since bot...";
CM_ SG_ 2364543998 RollAngleFigureOfMerit "Roll Angle Figure of Merit: Figure of merit for roll angle measurement.00b = Roll angle fully functional.  Data is within sensor specification.   01b = Roll angle degraded.  Data is suspect due to environmental conditions.10b = Error11b = Not availab...";
CM_ BO_ 2364544254 "Blade Information";
CM_ SG_ 2364544254 BladeRotationAngle "Blade Rotation Angle: The blade rotation angle measurement around the yaw (z-axis).  The Blade Rotation Angle is defined to be the angle from the null position on the machine.  The null position is orthogonal from the z-axis along the x-axis.  A posi...";
CM_ SG_ 2364544254 BladeRotationAngleFigureOfMerit "Blade Rotation Angle Figure of Merit: Figure of merit for blade rotation measurement.Bits00b = Blade Rotation Angle fully functional.  Data is within sensor specification.   01b = Blade Rotation Angle  degraded.  Data is suspect due to environmental ...";
CM_ SG_ 2364544254 RelativeBladeHeight "Relative Blade Height: The measured vertical distance from a fixed location on the machine blade to a ground-based reference (i.e. relative height).  Examples of a ground based reference include a curb, a stringline or the ground itself.  The measure...";
CM_ SG_ 2364544254 RtvBdHtAdBdRttAMstLt "Relative Blade Height and Blade Rotation Angle Measurement Latency: The estimated measurement latency of the measurement.NOTE: This is only the sensor latency and does not include any additional latencies that might exist because of the CAN Bus or ov...";
CM_ SG_ 2364544254 RltvBldHghtFgrOfMrt "Relative Blade Height Figure of Merit: Figure of merit for blade height measurement.Bits00b = Relative Blade Height fully functional.  Data is within sensor specification.   01b = Relative Blade Height degraded.  Data is suspect due to environmental ...";
CM_ BO_ 2364544510 "Requested Generator Total AC Reactive Power";
CM_ SG_ 2364544510 RqstdGnrtrOvrllPwrFtr "Requested Generator Overall Power Factor: The requested average power factor of the generator.";
CM_ SG_ 2364544510 RqstdGnrtrOvrllPwrFtrLggng "Requested Generator Overall Power Factor Lagging: The requested lead/lag status for the generator average AC power factor00b = Leading01b = Lagging10b = Reserved11b = Not available or Not installed";
CM_ SG_ 2364544510 RqstdGnrtrTtlARtvPwr "Requested Generator Total AC Reactive Power: The total reactive power requested to be delivered by the generator";
CM_ BO_ 2364544766 "Cylinder Combustion Status";
CM_ SG_ 2364544766 EngineCylinder1CombustionStatus "Engine Cylinder 1 Combustion Status: This parameter is used to indicate state of combustion in engine cylinder #100b = No combustion01b = Combustion exists10b = Error11b = Not available";
CM_ SG_ 2364544766 EngineCylinder2CombustionStatus "Engine Cylinder 2 Combustion Status: This parameter is used to indicate state of combustion in engine cylinder #200b = No combustion01b = Combustion exists10b = Error11b = Not available";
CM_ SG_ 2364544766 EngineCylinder3CombustionStatus "Engine Cylinder 3 Combustion Status: This parameter is used to indicate state of combustion in engine cylinder #300b = No combustion01b = Combustion exists10b = Error11b = Not available";
CM_ SG_ 2364544766 EngineCylinder4CombustionStatus "Engine Cylinder 4 Combustion Status: This parameter is used to indicate state of combustion in engine cylinder #400b = No combustion01b = Combustion exists10b = Error11b = Not available";
CM_ SG_ 2364544766 EngineCylinder5CombustionStatus "Engine Cylinder 5 Combustion Status: This parameter is used to indicate state of combustion in engine cylinder #500b = No combustion01b = Combustion exists10b = Error11b = Not available";
CM_ SG_ 2364544766 EngineCylinder6CombustionStatus "Engine Cylinder 6 Combustion Status: This parameter is used to indicate state of combustion in engine cylinder #600b = No combustion01b = Combustion exists10b = Error11b = Not available";
CM_ SG_ 2364544766 EngineCylinder7CombustionStatus "Engine Cylinder 7 Combustion Status: This parameter is used to indicate state of combustion in engine cylinder #700b = No combustion01b = Combustion exists10b = Error11b = Not available";
CM_ SG_ 2364544766 EngineCylinder8CombustionStatus "Engine Cylinder 8 Combustion Status: This parameter is used to indicate state of combustion in engine cylinder #800b = No combustion01b = Combustion exists10b = Error11b = Not available";
CM_ SG_ 2364544766 EngineCylinder9CombustionStatus "Engine Cylinder 9 Combustion Status: This parameter is used to indicate state of combustion in engine cylinder #900b = No combustion01b = Combustion exists10b = Error11b = Not available";
CM_ SG_ 2364544766 EngnClndr10CmstnStts "Engine Cylinder 10 Combustion Status: This parameter is used to indicate state of combustion in engine cylinder #1000b = No combustion01b = Combustion exists10b = Error11b = Not available";
CM_ SG_ 2364544766 EngnClndr11CmstnStts "Engine Cylinder 11 Combustion Status: This parameter is used to indicate state of combustion in engine cylinder #1100b = No combustion01b = Combustion exists10b = Error11b = Not available";
CM_ SG_ 2364544766 EngnClndr12CmstnStts "Engine Cylinder 12 Combustion Status: This parameter is used to indicate state of combustion in engine cylinder #1200b = No combustion01b = Combustion exists10b = Error11b = Not available";
CM_ SG_ 2364544766 EngnClndr13CmstnStts "Engine Cylinder 13 Combustion Status: This parameter is used to indicate state of combustion in engine cylinder #1300b = No combustion01b = Combustion exists10b = Error11b = Not available";
CM_ SG_ 2364544766 EngnClndr14CmstnStts "Engine Cylinder 14 Combustion Status: This parameter is used to indicate state of combustion in engine cylinder #1400b = No combustion01b = Combustion exists10b = Error11b = Not available";
CM_ SG_ 2364544766 EngnClndr15CmstnStts "Engine Cylinder 15 Combustion Status: This parameter is used to indicate state of combustion in engine cylinder #1500b = No combustion01b = Combustion exists10b = Error11b = Not available";
CM_ SG_ 2364544766 EngnClndr16CmstnStts "Engine Cylinder 16 Combustion Status: This parameter is used to indicate state of combustion in engine cylinder #1600b = No combustion01b = Combustion exists10b = Error11b = Not available";
CM_ SG_ 2364544766 EngnClndr17CmstnStts "Engine Cylinder 17 Combustion Status: This parameter is used to indicate state of combustion in engine cylinder #1700b = No combustion01b = Combustion exists10b = Error11b = Not available";
CM_ SG_ 2364544766 EngnClndr18CmstnStts "Engine Cylinder 18 Combustion Status: This parameter is used to indicate state of combustion in engine cylinder #1800b = No combustion01b = Combustion exists10b = Error11b = Not available";
CM_ SG_ 2364544766 EngnClndr19CmstnStts "Engine Cylinder 19 Combustion Status: This parameter is used to indicate state of combustion in engine cylinder #1900b = No combustion01b = Combustion exists10b = Error11b = Not available";
CM_ SG_ 2364544766 EngnClndr20CmstnStts "Engine Cylinder 20 Combustion Status: This parameter is used to indicate state of combustion in engine cylinder #2000b = No combustion01b = Combustion exists10b = Error11b = Not available";
CM_ SG_ 2364544766 EngnClndr21CmstnStts "Engine Cylinder 21 Combustion Status: This parameter is used to indicate state of combustion in engine cylinder #2100b = No combustion01b = Combustion exists10b = Error11b = Not available";
CM_ SG_ 2364544766 EngnClndr22CmstnStts "Engine Cylinder 22 Combustion Status: This parameter is used to indicate state of combustion in engine cylinder #2200b = No combustion01b = Combustion exists10b = Error11b = Not available";
CM_ SG_ 2364544766 EngnClndr23CmstnStts "Engine Cylinder 23 Combustion Status: This parameter is used to indicate state of combustion in engine cylinder #2300b = No combustion01b = Combustion exists10b = Error11b = Not available";
CM_ SG_ 2364544766 EngnClndr24CmstnStts "Engine Cylinder 24 Combustion Status: This parameter is used to indicate state of combustion in engine cylinder #2400b = No combustion01b = Combustion exists10b = Error11b = Not available";
CM_ BO_ 2364545022 "Engine Knock Level #1";
CM_ SG_ 2364545022 EngineCylinder1KnockLevel "Engine Cylinder 1 Knock Level: Used to indicate the level of knock for engine cylinder 1. The level of knock is reported using a relative scale where 0% is least level of knock, and increasing levels indicate more knock until 100% indicates the most ...";
CM_ SG_ 2364545022 EngineCylinder2KnockLevel "Engine Cylinder 2 Knock Level: Used to indicate the level of knock for engine cylinder 2. The level of knock is reported using a relative scale where 0% is least level of knock, and increasing levels indicate more knock until 100% indicates the most ...";
CM_ SG_ 2364545022 EngineCylinder3KnockLevel "Engine Cylinder 3 Knock Level: Used to indicate the level of knock for engine cylinder 3. The level of knock is reported using a relative scale where 0% is least level of knock, and increasing levels indicate more knock until 100% indicates the most ...";
CM_ SG_ 2364545022 EngineCylinder4KnockLevel "Engine Cylinder 4 Knock Level: Used to indicate the level of knock for engine cylinder 4. The level of knock is reported using a relative scale where 0% is least level of knock, and increasing levels indicate more knock until 100% indicates the most ...";
CM_ SG_ 2364545022 EngineCylinder5KnockLevel "Engine Cylinder 5 Knock Level: Used to indicate the level of knock for engine cylinder 5. The level of knock is reported using a relative scale where 0% is least level of knock, and increasing levels indicate more knock until 100% indicates the most ...";
CM_ SG_ 2364545022 EngineCylinder6KnockLevel "Engine Cylinder 6 Knock Level: Used to indicate the level of knock for engine cylinder 6. The level of knock is reported using a relative scale where 0% is least level of knock, and increasing levels indicate more knock until 100% indicates the most ...";
CM_ SG_ 2364545022 EngineCylinder7KnockLevel "Engine Cylinder 7 Knock Level: Used to indicate the level of knock for engine cylinder 7. The level of knock is reported using a relative scale where 0% is least level of knock, and increasing levels indicate more knock until 100% indicates the most ...";
CM_ SG_ 2364545022 EngineCylinder8KnockLevel "Engine Cylinder 8 Knock Level: Used to indicate the level of knock for engine cylinder 8. The level of knock is reported using a relative scale where 0% is least level of knock, and increasing levels indicate more knock until 100% indicates the most ...";
CM_ BO_ 2364545278 "Engine Knock Level #2";
CM_ SG_ 2364545278 EngineCylinder10KnockLevel "Engine Cylinder 10 Knock Level: Used to indicate the level of knock for engine cylinder 10. The level of knock is reported using a relative scale where 0% is least level of knock, and increasing levels indicate more knock until 100% indicates the mos...";
CM_ SG_ 2364545278 EngineCylinder11KnockLevel "Engine Cylinder 11 Knock Level: Used to indicate the level of knock for engine cylinder 11. The level of knock is reported using a relative scale where 0% is least level of knock, and increasing levels indicate more knock until 100% indicates the mos...";
CM_ SG_ 2364545278 EngineCylinder12KnockLevel "Engine Cylinder 12 Knock Level: Used to indicate the level of knock for engine cylinder 12. The level of knock is reported using a relative scale where 0% is least level of knock, and increasing levels indicate more knock until 100% indicates the mos...";
CM_ SG_ 2364545278 EngineCylinder13KnockLevel "Engine Cylinder 13 Knock Level: Used to indicate the level of knock for engine cylinder 13. The level of knock is reported using a relative scale where 0% is least level of knock, and increasing levels indicate more knock until 100% indicates the mos...";
CM_ SG_ 2364545278 EngineCylinder14KnockLevel "Engine Cylinder 14 Knock Level: Used to indicate the level of knock for engine cylinder 14. The level of knock is reported using a relative scale where 0% is least level of knock, and increasing levels indicate more knock until 100% indicates the mos...";
CM_ SG_ 2364545278 EngineCylinder15KnockLevel "Engine Cylinder 15 Knock Level: Used to indicate the level of knock for engine cylinder 15. The level of knock is reported using a relative scale where 0% is least level of knock, and increasing levels indicate more knock until 100% indicates the mos...";
CM_ SG_ 2364545278 EngineCylinder16KnockLevel "Engine Cylinder 16 Knock Level: Used to indicate the level of knock for engine cylinder 16. The level of knock is reported using a relative scale where 0% is least level of knock, and increasing levels indicate more knock until 100% indicates the mos...";
CM_ SG_ 2364545278 EngineCylinder9KnockLevel "Engine Cylinder 9 Knock Level: Used to indicate the level of knock for engine cylinder 9. The level of knock is reported using a relative scale where 0% is least level of knock, and increasing levels indicate more knock until 100% indicates the most ...";
CM_ BO_ 2364545534 "Engine Knock Level #3";
CM_ SG_ 2364545534 EngineCylinder17KnockLevel "Engine Cylinder 17 Knock Level: Used to indicate the level of knock for engine cylinder 17. The level of knock is reported using a relative scale where 0% is least level of knock, and increasing levels indicate more knock until 100% indicates the mos...";
CM_ SG_ 2364545534 EngineCylinder18KnockLevel "Engine Cylinder 18 Knock Level: Used to indicate the level of knock for engine cylinder 18. The level of knock is reported using a relative scale where 0% is least level of knock, and increasing levels indicate more knock until 100% indicates the mos...";
CM_ SG_ 2364545534 EngineCylinder19KnockLevel "Engine Cylinder 19 Knock Level: Used to indicate the level of knock for engine cylinder 19. The level of knock is reported using a relative scale where 0% is least level of knock, and increasing levels indicate more knock until 100% indicates the mos...";
CM_ SG_ 2364545534 EngineCylinder20KnockLevel "Engine Cylinder 20 Knock Level: Used to indicate the level of knock for engine cylinder 20. The level of knock is reported using a relative scale where 0% is least level of knock, and increasing levels indicate more knock until 100% indicates the mos...";
CM_ SG_ 2364545534 EngineCylinder21KnockLevel "Engine Cylinder 21 Knock Level: Used to indicate the level of knock for engine cylinder 21. The level of knock is reported using a relative scale where 0% is least level of knock, and increasing levels indicate more knock until 100% indicates the mos...";
CM_ SG_ 2364545534 EngineCylinder22KnockLevel "Engine Cylinder 22 Knock Level: Used to indicate the level of knock for engine cylinder 22. The level of knock is reported using a relative scale where 0% is least level of knock, and increasing levels indicate more knock until 100% indicates the mos...";
CM_ SG_ 2364545534 EngineCylinder23KnockLevel "Engine Cylinder 23 Knock Level: Used to indicate the level of knock for engine cylinder 23. The level of knock is reported using a relative scale where 0% is least level of knock, and increasing levels indicate more knock until 100% indicates the mos...";
CM_ SG_ 2364545534 EngineCylinder24KnockLevel "Engine Cylinder 24 Knock Level: Used to indicate the level of knock for engine cylinder 24. The level of knock is reported using a relative scale where 0% is least level of knock, and increasing levels indicate more knock until 100% indicates the mos...";
CM_ BO_ 2364546302 "Requested Generator Average Basic AC Quantities";
CM_ SG_ 2364546302 RqstdGnrtrAvrgLnLnARmsVltg "Requested Generator Average Line-Line AC RMS Voltage: The requested average AC RMS voltage to be delivered by the generator.";
CM_ BO_ 2364546814 "Generator Control 2";
CM_ SG_ 2364546814 EngineLoadSetpointRequest "Engine Load Setpoint Request: Setpoint request (in kW) sent to the engine by a genset control system.";
CM_ SG_ 2364546814 EngineSelfInducedDerateInhibit "Engine Self-Induced Derate Inhibit: Parameter to indicate if the genset control system allows the Engine Control Module to impose its own induced derate.00b = Engine is allowed to impose a self-induced derate01b = Engine is inhibited from imposing a ...";
CM_ SG_ 2364546814 GeneratorGoverningBias "Generator Governing Bias: Control signal used to govern the genset's speed or load (depending on isochronous or utility parallel operation, respectively)NOTE:  If this method of engine control is used, the PGN 0 (TSC1) is not expected to be received ...";
CM_ BO_ 2364548094 "Aftertreatment 1 SCR Dosing System Information 1";
CM_ SG_ 2364548094 Aftertreatment1ScrSystem1State "Aftertreatment 1 SCR System 1 State: Actual state of SCR system0000b = Dormant (sleep mode)0001b = Preparing dosing readiness (wake up; prepare to operate; wait for start)0010b = Normal dosing operation0011b = System error pending0100b = Purging (SCR...";
CM_ SG_ 2364548094 Aftertreatment1ScrSystem2State "Aftertreatment 1 SCR System 2 State: Actual state of SCR system 20000b = Dormant (sleep mode)0001b = Preparing dosing readiness (wake up; prepare to operate; wait for start)0010b = Normal dosing operation0011b = System error pending0100b = Purging (S...";
CM_ SG_ 2364548094 Atttt1DsExstFdAtDsQtt "Aftertreatment 1 Diesel Exhaust Fluid Actual Dosing Quantity: Actual reducing agent quantity of SCR-system";
CM_ SG_ 2364548094 Atttt1DsExstFdAtDsQttHR "Aftertreatment 1 Diesel Exhaust Fluid Actual Dosing Quantity (High Range): Actual dosing quantity of diesel exhaust fluid. See SPN 4331 if high range measurement is not needed.";
CM_ SG_ 2364548094 Atttt1DsExstFdDs1AstPss "Aftertreatment 1 Diesel Exhaust Fluid Doser 1 Absolute Pressure: The absolute pressure (measured closest to dosing valve) of the first or only DEF dosing unit for aftertreatment system 1 (exhaust bank 1).";
CM_ SG_ 2364548094 Atttt1DsExstFdAtQttOItt "Aftertreatment 1 Diesel Exhaust Fluid Actual Quantity of Integrator: The SCR requested diesel exhaust fluid integrator total quantity for aftertreatment system 1 (exhaust bank 1).";
CM_ BO_ 2364548350 "Aftertreatment 1 SCR Dosing System Requests 1";
CM_ SG_ 2364548350 Atttt1DsExstFdDsRqstdQtt "Aftertreatment 1 Diesel Exhaust Fluid Dosing Requested Quantity: Actual requested dosing quantity of diesel exhaust fluid.";
CM_ SG_ 2364548350 Atttt1DsExstFdDsRqstdQttHR "Aftertreatment 1 Diesel Exhaust Fluid Dosing Requested Quantity (High Range): Requested dosing quantity of diesel exhaust fluid. This SP is a high range measurement. See SPN 4348 if high range is not needed.";
CM_ SG_ 2364548350 Atttt1DsExstFdDsTstItPssStts "Aftertreatment 1 Diesel Exhaust Fluid Dosing Test Injection Permission Status: After a request to permit the DEF dosing test injection has been indicated, this permission status is expected by the DEF control unit for aftertreatment system 1.00b = no...";
CM_ SG_ 2364548350 Atttt1DsExstFdHdStssCPssStts "Aftertreatment 1 Diesel Exhaust Fluid Hydraulic Stiffness Check Permission Status: After a request to permit the DEF hydraulic stiffness check has been indicated, this permission status is expected by the DEF control unit for aftertreatment system 1....";
CM_ SG_ 2364548350 Aftrtrtmnt1SrSstmRqstdStt "Aftertreatment 1 SCR System Requested State: Requested state of SCR system for aftertreatment system 1 (exhaust bank 1).0000b = Dormant (sleep mode) 0001b = Preparing dosing readiness (wake up; prepare to operate; wait for start) 0010b = Normal dosin...";
CM_ SG_ 2364548350 Atttt1DsExstFdRqstdQttOItt "Aftertreatment 1 Diesel Exhaust Fluid Requested Quantity of Integrator: Represents the command for the diesel exhaust fluid quantity integrator in the dosing control unit.  See SPN 7783 for alternate resolution.";
CM_ BO_ 2364548606 "Aftertreatment 1 SCR Ammonia Information";
CM_ SG_ 2364548606 Aftertreatment1OutletNh3 "Aftertreatment 1 Outlet NH3: The amount of NH3 in the exhaust exiting the aftertreatment system measured by a NH3 sensor at the aftertreatment outlet, represented in NH3 molecule parts per million non-NH3 molecules in exhaust bank 1.";
CM_ SG_ 2364548606 Aftrtrtmnt1OtltNh3RdngStl "Aftertreatment 1 Outlet NH3 Reading Stable: Indicates that the NH3 reading of the aftertreatment outlet NH3 sensor is stable as determined by the manufacturer's control software in exhaust bank 1.00b = Reading is not stable01b = Reading is stable10b ...";
CM_ SG_ 2364548606 Aftrtrtmnt1OtltNh3SnsrPrlmnrFm "Aftertreatment 1 Outlet NH3 Sensor Preliminary FMI: Used to identify the applicable J1939-73 FMI detected in the aftertreatment outlet NH3 sensor by the manufacturer's sensor control software in exhaust bank 1. In the case of multiple failures the mo...";
CM_ SG_ 2364548606 Atttt1OttN3GsSsPwIR "Aftertreatment 1 Outlet NH3 Gas Sensor Power In Range: Indicates that the power supplied to the aftertreatment outlet NH3 gas sensor is within the manufacturer's specification in exhaust bank 1.00b = Power is not in range01b = Power is in range10b = ...";
CM_ SG_ 2364548606 Atttt1OttN3GsSsAtTpt "Aftertreatment 1 Outlet NH3 Gas Sensor at Temperature: Indicates that the heater element of the aftertreatment outlet NH3 gas sensor is within the manufacturer's specified range for accurate measurements in exhaust bank 1.00b = Heater element is not ...";
CM_ SG_ 2364548606 Atttt1OttN3GsSsHtPF "Aftertreatment 1 Outlet NH3 Gas Sensor Heater Preliminary FMI: Used to identify the applicable J1939-73 FMI detected in the heater of the outlet NH3 exhaust gas sensor by the manufacturer's sensor control software in exhaust bank 1.  In the case of m...";
CM_ SG_ 2364548606 Atttt1OttN3GsSsHtCt "Aftertreatment 1 Outlet NH3 Gas Sensor Heater Control: Indicates the heater status in the warm-up process. Upon receiving a power-up command, the NH3 gas sensor ramps up according to a manufacturer defined profile. The Preheat 1, Preheat 2, and Autom...";
CM_ BO_ 2364548862 "Aftertreatment 2 SCR Dosing System Information 1";
CM_ SG_ 2364548862 Aftertreatment2ScrSystem1State "Aftertreatment 2 SCR System 1 State: Actual state of SCR system 1.0000b = Dormant (sleep mode)0001b = Preparing dosing readiness (wake up; prepare to operate; wait for start)0010b = Normal dosing operation0011b = System error pending0100b = Purging (...";
CM_ SG_ 2364548862 Aftertreatment2ScrSystem2State "Aftertreatment 2 SCR System 2 State: Actual state of SCR system 20000b = Dormant (sleep mode)0001b = Preparing dosing readiness (wake up; prepare to operate; wait for start)0010b = Normal dosing operation0011b = System error pending0100b = Purging (S...";
CM_ SG_ 2364548862 Atttt2DsExstFdAtDsQtt "Aftertreatment 2 Diesel Exhaust Fluid Actual Dosing Quantity: Actual reducing agent quantity of SCR system.";
CM_ SG_ 2364548862 Atttt2DsExstFdAtDsQttHR "Aftertreatment 2 Diesel Exhaust Fluid Actual Dosing Quantity (High Range): Actual dosing quantity of diesel exhaust fluid. See SPN 4384 if high range measurement is not needed.";
CM_ SG_ 2364548862 Atttt2DsExstFdDs1AstPss "Aftertreatment 2 Diesel Exhaust Fluid Doser 1 Absolute Pressure: The absolute pressure (measured closest to dosing valve) of the first or only DEF doser for aftertreatment system 2 (exhaust bank 2).";
CM_ SG_ 2364548862 Atttt2DsExstFdAtQttOItt "Aftertreatment 2 Diesel Exhaust Fluid Actual Quantity of Integrator: The SCR requested diesel exhaust fluid integrator total quantity for aftertreatment system 2 (exhaust bank 2).";
CM_ BO_ 2364549118 "Aftertreatment 2 SCR Dosing System Requests 1";
CM_ SG_ 2364549118 Atttt2DsExstFdDsRqstdQtt "Aftertreatment 2 Diesel Exhaust Fluid Dosing Requested Quantity: Actual requested dosing quantity of diesel exhaust fluid.";
CM_ SG_ 2364549118 Atttt2DsExstFdDsRqstdQttHR "Aftertreatment 2 Diesel Exhaust Fluid Dosing Requested Quantity (High Range): Requested dosing quantity of diesel exhaust fluid. This SP is a high range measurement. See SPN 4401 if high range is not needed.";
CM_ SG_ 2364549118 Atttt2DsExstFdDsTstItPssStts "Aftertreatment 2 Diesel Exhaust Fluid Dosing Test Injection Permission Status: After a request to permit the DEF dosing test injection has been indicated, this permission status is expected by the DEF control unit for aftertreatment system 2.00b = no...";
CM_ SG_ 2364549118 Atttt2DsExstFdHdStssCPssStts "Aftertreatment 2 Diesel Exhaust Fluid Hydraulic Stiffness Check Permission Status: After a request to permit the DEF hydraulic stiffness check has been indicated, this permission status is expected by the DEF control unit for aftertreatment system 2....";
CM_ SG_ 2364549118 Atttt2DsExstFdPpHtCd "Aftertreatment 2 Diesel Exhaust Fluid Pump Heater Command: Command for the Aftertreatment 2 Diesel Exhaust Fluid Pump Heater.  A value of 0% means no heating commanded, a value of 100% means full heating commanded.";
CM_ SG_ 2364549118 Aftrtrtmnt2SrSstmRqstdStt "Aftertreatment 2 SCR System Requested State: Requested state of SCR system for aftertreatment system 2 (exhaust bank 2).0000b = Dormant (sleep mode) 0001b = Preparing dosing readiness (wake up; prepare to operate; wait for start) 0010b = Normal dosin...";
CM_ SG_ 2364549118 Atttt2DsExstFdRqstdQttOItt "Aftertreatment 2 Diesel Exhaust Fluid Requested Quantity of Integrator: Represents the command for the diesel exhaust fluid quantity integrator in the dosing control unit. See SPN 7784 for alternate resolution.";
CM_ BO_ 2364549374 "Aftertreatment 2 SCR Ammonia Information";
CM_ SG_ 2364549374 Aftertreatment2OutletNh3 "Aftertreatment 2 Outlet NH3: The amount of NH3 in the exhaust exiting the aftertreatment system measured by a NH3 sensor at the aftertreatment outlet, represented in NH3 molecule parts per million non-NH3 molecules in exhaust bank 2.";
CM_ SG_ 2364549374 Aftrtrtmnt2OtltNh3RdngStl "Aftertreatment 2 Outlet NH3 Reading Stable: Indicates that the NH3 reading of the aftertreatment outlet NH3 sensor is stable as determined by the manufacturer's control software in exhaust bank 2.00b = Reading is not stable01b = Reading is stable10b ...";
CM_ SG_ 2364549374 Aftrtrtmnt2OtltNh3SnsrPrlmnrFm "Aftertreatment 2 Outlet NH3 Sensor Preliminary FMI: Used to identify the applicable J1939-73 FMI detected in the aftertreatment outlet NH3 sensor by the manufacturer's sensor control software in exhaust bank 2. In the case of multiple failures the mo...";
CM_ SG_ 2364549374 Atttt2OttN3GsSsPwIR "Aftertreatment 2 Outlet NH3 Gas Sensor Power In Range: Indicates that the power supplied to the aftertreatment outlet NH3 gas sensor is within the manufacturer's specification in exhaust bank 2.00b = Heater element is not in range01b = Heater element...";
CM_ SG_ 2364549374 Atttt2OttN3GsSsAtTpt "Aftertreatment 2 Outlet NH3 Gas Sensor at Temperature: Indicates that the heater element of the aftertreatment outlet NH3 gas sensor is within the manufacturer's specified range for accurate measurements in exhaust bank 2.00b = Heater element is not ...";
CM_ SG_ 2364549374 Atttt2OttN3GsSsHtPF "Aftertreatment 2 Outlet NH3 Gas Sensor Heater Preliminary FMI: Used to identify the applicable J1939-73 FMI detected in the heater of the outlet NH3 exhaust gas sensor by the manufacturer's sensor control software in exhaust bank 2. In the case of mu...";
CM_ SG_ 2364549374 Atttt2OttN3GsSsHtCt "Aftertreatment 2 Outlet NH3 Gas Sensor Heater Control: Indicates the heater status in the warm-up process. Upon receiving a power-up command, the NH3 gas sensor ramps up according to a manufacturer defined profile. The Preheat 1, Preheat 2, and Autom...";
CM_ BO_ 2364549630 "Slope Sensor Information 2";
CM_ SG_ 2364549630 PitchAngleExtendedRange "Pitch Angle (Extended Range): The angle between the vehicle x-axis and the ground plane (i.e. rotation about the vehicle Y-axis).  The pitch angle for an angle of ascent is reported with a positive value. This parameter is defined according to a Z-Do...";
CM_ SG_ 2364549630 PthAnglCmpnstnExtnddRng "Pitch Angle Compensation (Extended Range): Compensated mode for the pitch measurement.  Compensation is the use of multiple sensors together to enhance the output of the pitch measurement.00b = On01b = Off10b = Error11b = Not Available";
CM_ SG_ 2364549630 RllAnglCmpnstnExtnddRng "Roll Angle Compensation (Extended Range): Compensated mode for the roll angle measurement.  Compensation is the use of multiple sensors together to enhance the output of the roll angle measurement.00b = On01b = Off10b = Error11b = Not Available...";
CM_ SG_ 2364549630 RollAngleExtendedRange "Roll Angle (Extended Range): The angle between the vehicle y-axis and the ground plane (i.e. rotation about the X-axis).  The roll angle for a roll to the right is reported with a positive value. Roll angle is the same for both Z-Down and Z-Up axis s...";
CM_ SG_ 2364549630 PthAnglFgrOfMrtExtnddRng "Pitch Angle Figure of Merit (Extended Range): Figure of merit for pitch angle measurement.00b = Pitch angle fully functional. Data is within sensor specification.01b = Pitch angle degraded. Data is suspect due to environmental conditions.10b = Error1...";
CM_ SG_ 2364549630 RllAnglFgrOfMrtExtnddRng "Roll Angle Figure of Merit (Extended Range): Figure of merit for roll angle measurement.00b = Roll angle fully functional. Data is within sensor specification.01b = Roll angle degraded. Data is suspect due to environmental conditions.10b = Error11b =...";
CM_ SG_ 2364549630 RllAndPthMsrmntLtnExtnddRng "Roll and Pitch Measurement Latency (Extended Range): Time between start of sensor processing and CAN transmission";
CM_ BO_ 2364549886 "Angular Rate Information";
CM_ SG_ 2364549886 AngularRateMeasurementLatency "Angular Rate Measurement Latency: The estimated measurement latency of the measurement.NOTE: This is only the sensor latency and does not include any additional latencies that might exist because of the CAN Bus or overall system implementation. Laten...";
CM_ SG_ 2364549886 PitchRateExtendedRange "Pitch Rate (Extended Range): Pitch rate is the rate-of-change of the pitch angle over time, where the pitch angle vector is in the direction of travel of the vehicle. The pitch rate for increasing ascent over time is reported with a positive value. T...";
CM_ SG_ 2364549886 RollRateExtendedRange "Roll Rate (Extended Range): Roll rate is the rate-of-change of the roll angle over time.  The roll rate for increasing roll to the right is reported with a positive value. Roll angle is the same for both Z-Down and Z-Up axis systems, since both syste...";
CM_ SG_ 2364549886 YawRateExtendedRange "Yaw Rate (Extended Range): Yaw rate is the rate-of-change of the yaw angle over time.  A positive yaw rate signal results when the object turns clockwise.  This parameter is defined according to a Z-Down axis system and the sign of the value is in ac...";
CM_ SG_ 2364549886 PthRtFgrOfMrtExtnddRng "Pitch Rate Figure of Merit (Extended Range): Figure of merit for pitch rate measurement.00b = Pitch rate fully functional. Data is within sensor specification.01b = Pitch rate degraded. Data is suspect due to environmental conditions.10b = Error11b =...";
CM_ SG_ 2364549886 RllRtFgrOfMrtExtnddRng "Roll Rate Figure of Merit (Extended Range): Figure of merit for roll rate measurement.00b = Roll rate fully functional. Data is within sensor specification.01b = Roll rate degraded. Data is suspect due to environmental conditions.10b = Error11b = Not...";
CM_ SG_ 2364549886 YwRtFgrOfMrtExtnddRng "Yaw Rate Figure of Merit (Extended Range): Figure of merit for yaw angle measurement.00b = Yaw rate fully functional. Data is within sensor specification.01b = Yaw rate degraded. Data is suspect due to environmental conditions.10b = Error11b = Not av...";
CM_ BO_ 2364551166 "Advanced Emergency Braking System 1";
CM_ SG_ 2364551166 CollisionWarningLevel "Collision warning level: To implement different HMI (human machine interface) concepts, e.g. visual only, visual/audible, different warning tones etc., the AEBS provides different levels of collision warning.0000b = no warning0001b = warning level 1 ...";
CM_ SG_ 2364551166 FwdCsAdvdEBSstStt "Forward Collision Advanced Emergency Braking System State: Current operational state of forward collision advanced emergency braking system (AEBS)0000b = system is not ready (initialization not finished)0001b = system is temporarily not available (e....";
CM_ SG_ 2364551166 RdDprtrAdvndEmrgnBrkngSstmStt "Road Departure Advanced Emergency Braking System State: Current operational state of road departure advanced emergency braking system (AEBS)0000b = system is not ready (initialization not finished)0001b = system is temporarily not available (e.g. due...";
CM_ SG_ 2364551166 RvtOtDttdFAdvdEBSst "Relevant object detected for advanced emergency braking system: Indication if the advanced emergency braking system (AEBS) is monitoring a relevant object000b = No relevant object monitored001b = Relevant object is being monitored010b = Relevant obje...";
CM_ SG_ 2364551166 BndOffPrltOfRlvntOjt "Bend off probability of relevant object: Probabilty if monitored relevant object might start a turning maneuver, which could clear the travelling path of the host vehicle.000b = no indication for a bend off maneuver of the relevant object001b = low p...";
CM_ SG_ 2364551166 TmTCllsnWthRlvntOjt "Time to collision with relevant object: The time to collision is the duration after which the predicted travelling paths of host vehicle and relevant object lead to a distance of 0m between both.Note:  It is up to the system manufacturer to choose a ...";
CM_ BO_ 2364551422 "Wireless Status";
CM_ SG_ 2364551422 TransmitterCommandState "Transmitter Command State: The command contained in the signal received by the wireless transceiver from an off-board transmitter.0000b = Stop0001b = Clear0010b = Field Test0011b = Transmitter Test0100b = Standby0101b to 1101b = Reserved1110b = Error...";
CM_ SG_ 2364551422 TransmitterId1 "Transmitter ID 1: The ID of the off-board transmitter that sent the incoming message received by the wireless transceiver.";
CM_ SG_ 2364551422 WirelessRollingMessageCounter "Wireless Rolling Message Counter: A counter incremented with each instance of the Wireless Status message. The counter shall increment from 0 to 64255, rolling over to 0 on the next increment after 64255. The enables recipients of the Wireless Status...";
CM_ SG_ 2364551422 WirelessSignalStrength1 "Wireless Signal Strength 1: The absolute received signal strength of the signal received from the off-board transmitter. The signal strength is reported as a Received Signal Strength Indicator (RSSI) value calculated in dBm.";
CM_ BO_ 2364552958 "High Voltage Energy Storage System Status 2";
CM_ SG_ 2364552958 HvssDshrgPwrLmtDTSttOfChrg "HVESS Discharge Power Limit Due to State of Charge: Indicates whether or not discharge power of this HVES instance is being limited due to state of charge.This parameter provides HVES system level information. If there are multiple packs in the syste...";
CM_ SG_ 2364552958 HvssDshrgPwrLmtDTBttrTmprtr "HVESS Discharge Power Limit Due to Battery Temperature: Indicates whether or not discharge power of this HVES instance is being limited due to battery temperature.This parameter provides HVES system level information. If there are multiple packs in t...";
CM_ SG_ 2364552958 HvssDshrgPwrLmtDTBttrDgnstCndtn "HVESS Discharge Power Limit Due to Battery Diagnostic Condition: Indicates whether or not discharge power of this HVES instance is being limited due to a battery diagnostic condition.This parameter provides HVES system level information. If there are...";
CM_ SG_ 2364552958 HvssDshrgPwrLmtDTBttrOrCllVltg "HVESS Discharge Power Limit Due to Battery or Cell Voltage: Indicates whether or not discharge power of this HVES instance is being limited due to a battery or cell voltage level.This parameter provides HVES system level information. If there are mul...";
CM_ SG_ 2364552958 HvssDshrgPwrLmtDTBttrCrrnt "HVESS Discharge Power Limit Due to Battery Current: Indicates whether or not discharge power of this HVES instance is being limited due to battery current.This parameter provides HVES system level information. If there are multiple packs in the syste...";
CM_ SG_ 2364552958 HvssDshrgPwrLmtDTAnUndfndCs "HVESS Discharge Power Limit Due to an Undefined Cause: Indicates whether or not discharge power of this HVES instance is being limited due to an undefined cause.This parameter provides HVES system level information. If there are multiple packs in the...";
CM_ SG_ 2364552958 HvssChrgPwrLmtDTSttOfChrg "HVESS Charge Power Limit Due to State of Charge: Indicates whether or not charge power of this HVES instance is being limited due to state of charge.This parameter provides HVES system level information. If there are multiple packs in the system, the...";
CM_ SG_ 2364552958 HvssChrgPwrLmtDTBttrTmprtr "HVESS Charge Power Limit Due to Battery Temperature: Indicates whether or not charge power of this HVES instance is being limited due to battery temperature.This parameter provides HVES system level information. If there are multiple packs in the sys...";
CM_ SG_ 2364552958 HvssChrgPwrLmtDTBttrDgnstCndtn "HVESS Charge Power Limit Due to Battery Diagnostic Condition: Indicates whether or not charge power of this HVES instance is being limited due to a battery diagnostic condition.This parameter provides HVES system level information. If there are multi...";
CM_ SG_ 2364552958 HvssChrgPwrLmtDTBttrOrCllVltg "HVESS Charge Power Limit Due to Battery or Cell Voltage: Indicates whether or not charge power of this HVES instance is being limited due to a battery or cell voltage level.This parameter provides HVES system level information. If there are multiple ...";
CM_ SG_ 2364552958 HvssChrgPwrLmtDTBttrCrrnt "HVESS Charge Power Limit Due to Battery Current: Indicates whether or not charge power of this HVES instance is being limited due to battery current.This parameter provides HVES system level information. If there are multiple packs in the system, the...";
CM_ SG_ 2364552958 HvssChrgPwrLmtDTAnUndfndCs "HVESS Charge Power Limit Due to an Undefined Cause: Indicates whether or not charge power of this HVES instance is being limited due to an undefined cause.This parameter provides HVES system level information. If there are multiple packs in the syste...";
CM_ SG_ 2364552958 HvssDsPwLtDTPwMdEtsTpt "HVESS Discharge Power Limit due to Power Module Electronics Temperature: Indicates whether or not output discharge power is being limited due to Power Module Electronics Temperature (see SPN 22822 (HVESS Power Module Electronics Temperature)) approac...";
CM_ SG_ 2364552958 HvssCPwLtDTPwMdEtsTpt "HVESS Charge Power Limit due to Power Module Electronics Temperature: Indicates whether or not output charge power is being limited due to Power Module Electronics Temperature (see SPN 22822 (HVESS Power Module Electronics Temperature)) approaching o...";
CM_ BO_ 2364553214 "Engine Turbocharger Blowoff Actuator 1";
CM_ SG_ 2364553214 EngnTrhrgrCmprssrBlwffAttr1Pstn "Engine Turbocharger Compressor Blowoff Actuator 1 Position: Actual position of the turbocharger compressor blowoff actuator, where 0% represents fully closed and 100% represents fully open.";
CM_ SG_ 2364553214 ETCpssBwAtt1DsdPst "Engine Turbocharger Compressor Blowoff Actuator 1 Desired Position: The requested position of the Engine Turbocharger Compressor Blowoff actuator by the engine ECU, where 0% represents bypass fully closed and 100% represents fully open.  This is the ...";
CM_ SG_ 2364553214 ETCpssBwAtt1OptStts "Engine Turbocharger Compressor Blowoff Actuator 1 Operation Status: Used to identify the status of Engine Turbocharger Compressor Blowoff Actuator 1.0000b = Normal0001b = Alarm (fully operational but needs service)0010b = Alarm High Severity (functio...";
CM_ SG_ 2364553214 ETCpssBwAtt1Tpt "Engine Turbocharger Compressor Blowoff Actuator 1 Temperature: Temperature of the Engine Turbocharger Compressor Bypass Actuator 1 drive circuitry. Temperature excursions may affect the torque output.";
CM_ SG_ 2364553214 ETCpssBwAtt1TptStts "Engine Turbocharger Compressor Blowoff Actuator 1 Temperature Status: Used to identify the status of the Engine Turbocharger Compresssor Blowoff Actuator 1 drive circuitry temperature. Temperature excursions may affect the torque output.000b = High M...";
CM_ SG_ 2364553214 ETCpssBwAtt1PF "Engine Turbocharger Compressor Blowoff Actuator 1 Preliminary FMI: Used to identify the applicable J1939-73 FMI detected in the Engine Turbocharger Blowoff Actuator 1 by the manufacturer's software.  When there are multiple failures, the most severe ...";
CM_ BO_ 2364553470 "Engine Torque / Fuel Request";
CM_ SG_ 2364553470 EngineCylinderTorque "Engine Cylinder Torque: Calculated engine torque output per cylinder.";
CM_ SG_ 2364553470 EngineDualFuelModeCommand "Engine Dual Fuel Mode Command: Request to enable dual fuel mode.00b = De-activate dual fuel mode01b = Activate dual fuel mode10b = Reserved11b = Not available";
CM_ SG_ 2364553470 EngnClndrDslMssFlwRtCmmnd "Engine Cylinder Diesel Mass Flow Rate Command: Commanded Mass Flow rate of diesel fuel delivered to the engine normalized per cylinder.";
CM_ SG_ 2364553470 EngnClndrGsMssFlwRtCmmnd "Engine Cylinder Gas Mass Flow Rate Command: Commanded Mass Flow rate of gaseous fuel delivered to the engine normalized per cylinder.";
CM_ SG_ 2364553470 EngnGsSstttnFlPrntgCmmnd "Engine Gas Substitution Fuel Percentage Command: Percentage of Gaseous fuel used, in terms of % mass of fuel. 0% means no Gaseous fuel used and 100 % means completely gaseous fuel is used.Gas substitution is the process for a dual fuel engine system ...";
CM_ BO_ 2364553726 "Engine Air System Information";
CM_ SG_ 2364553726 EngineDesiredAirFuelRatio "Engine Desired Air Fuel Ratio: Reports the desired Air Fuel ratio for the engine.Air Fuel Ratio specifies the amount of air required to completely burn one unit of fuel in the engine to meet the required engine performance and emission standards.";
CM_ SG_ 2364553726 EngnFlSstm1TtlIntkMssArFlwRt "Engine Fuel System 1 Total Intake Mass Air Flow Rate: Mass Flow rate of air entering the engine (or the first fuel system on a configuration with more than 1 fuel system). This also includes the amount of exhaust gas recirculated, if any.";
CM_ SG_ 2364553726 EngnFlSstm2TtlIntkMssArFlwRt "Engine Fuel System 2 Total Intake Mass Air Flow Rate: Mass Flow rate of air entering the second fuel system of the engine. This also includes the amount of exhaust gas recirculated, if any.";
CM_ SG_ 2364553726 CommandedEquivalenceRatio "Commanded Equivalence Ratio: Indicates the commanded equivalence ratio for the engine. This is defined to be the ratio of the commanded fuel/air ratio to the stoichiometric fuel/air ratio.";
CM_ BO_ 2364553982 "Engine Cylinder 1 Combustion Information";
CM_ SG_ 2364553982 EngineCylinder1HeatRelease "Engine Cylinder 1 Heat Release: The amount of heat produced during combustion in Engine cylinder 1. The negative range is to cover thermodynamic behavior during misfire.";
CM_ SG_ 2364553982 EngineCylinder1PeakPressure "Engine Cylinder 1 Peak Pressure: Peak pressure in engine cylinder 1 in combustion cycle.";
CM_ SG_ 2364553982 EngnClndr1LwFrqnKnkLvl "Engine Cylinder 1 Low Frequency Knock Level: Indicates the level of low frequency knock for engine cylinder 1. This knock occurs at frequencies below the typical knock level reported on SPNs 1352 & 6398. The level of low frequency knock is reported u...";
CM_ SG_ 2364553982 EngnClndr1MxmmPrssrInrsRt "Engine Cylinder 1 Maximum Pressure Increase Rate: The maximum slope, in degrees of crank angle, of the pressure increase in engine cylinder 1 during the combustion cycle.";
CM_ SG_ 2364553982 EngnClndr1SnhrnsKnkLvl "Engine Cylinder 1 Synchronous Knock Level: Used to indicate the level of knock for engine cylinder 1. The level of knock is reported using a relative scale where 0% is least level of knock, and increasing levels indicate more knock until 100% indicat...";
CM_ SG_ 2364553982 EngnClndr1PrssrSnsrPrlmnrFm "Engine Cylinder 1 Pressure Sensor Preliminary FMI: Used to identify the applicable J1939-73 FMI detected in the engine cylinder 1 pressure sensor. In the case of multiple failures the most severe is communicated.A value of 31 is sent to indicate that...";
CM_ BO_ 2364554238 "Engine Cylinder 2 Combustion Information";
CM_ SG_ 2364554238 EngineCylinder2HeatRelease "Engine Cylinder 2 Heat Release: The amount of heat produced during combustion in engine cylinder 2.  The negative range is to cover thermodynamic behavior during misfire.";
CM_ SG_ 2364554238 EngineCylinder2PeakPressure "Engine Cylinder 2 Peak Pressure: Peak pressure in engine cylinder 2 in combustion cycle.";
CM_ SG_ 2364554238 EngnClndr2LwFrqnKnkLvl "Engine Cylinder 2 Low Frequency Knock Level: Indicates the level of low frequency knock for engine cylinder 2. This knock occurs at frequencies below the typical knock level reported on SPNs 1353 & 6402.  The level of low frequency knock is reported ...";
CM_ SG_ 2364554238 EngnClndr2MxmmPrssrInrsRt "Engine Cylinder 2 Maximum Pressure Increase Rate: The maximum slope, in degrees of crank angle, of the pressure increase in engine cylinder 2 during the combustion cycle.";
CM_ SG_ 2364554238 EngnClndr2SnhrnsKnkLvl "Engine Cylinder 2 Synchronous Knock Level: Used to indicate the level of knock for engine cylinder 2. The level of knock is reported using a relative scale where 0% is least level of knock, and increasing levels indicate more knock until 100% indicat...";
CM_ SG_ 2364554238 EngnClndr2PrssrSnsrPrlmnrFm "Engine Cylinder 2 Pressure Sensor Preliminary FMI: Used to identify the applicable J1939-73 FMI detected in the engine cylinder 2 pressure sensor.  In the case of multiple failures the most severe is communicated.A value of 31 is sent to indicate tha...";
CM_ BO_ 2364554494 "Engine Cylinder 3 Combustion Information";
CM_ SG_ 2364554494 EngineCylinder3HeatRelease "Engine Cylinder 3 Heat Release: The amount of heat produced during combustion in engine cylinder 3.  The negative range is to cover thermodynamic behavior during misfire.";
CM_ SG_ 2364554494 EngineCylinder3PeakPressure "Engine Cylinder 3 Peak Pressure: Peak pressure in engine cylinder 3 in combustion cycle.";
CM_ SG_ 2364554494 EngnClndr3LwFrqnKnkLvl "Engine Cylinder 3 Low Frequency Knock Level: Indicates the level of low frequency knock for engine cylinder 3. This knock occurs at frequencies below the typical knock level reported on SPNs 1354 & 6406.  The level of low frequency knock is reported ...";
CM_ SG_ 2364554494 EngnClndr3MxmmPrssrInrsRt "Engine Cylinder 3 Maximum Pressure Increase Rate: The maximum slope, in degrees of crank angle, of the pressure increase in engine cylinder 3 during the combustion cycle.";
CM_ SG_ 2364554494 EngnClndr3SnhrnsKnkLvl "Engine Cylinder 3 Synchronous Knock Level: Used to indicate the level of knock for engine cylinder 3. The level of knock is reported using a relative scale where 0% is least level of knock, and increasing levels indicate more knock until 100% indicat...";
CM_ SG_ 2364554494 EngnClndr3PrssrSnsrPrlmnrFm "Engine Cylinder 3 Pressure Sensor Preliminary FMI: Used to identify the applicable J1939-73 FMI detected in the engine cylinder 3 pressure sensor.  In the case of multiple failures the most severe is communicated.A value of 31 is sent to indicate tha...";
CM_ BO_ 2364554750 "Engine Cylinder 4 Combustion Information";
CM_ SG_ 2364554750 EngineCylinder4HeatRelease "Engine Cylinder 4 Heat Release: The amount of heat produced during combustion in engine cylinder 4.  The negative range is to cover thermodynamic behavior during misfire.";
CM_ SG_ 2364554750 EngineCylinder4PeakPressure "Engine Cylinder 4 Peak Pressure: Peak pressure in engine cylinder 4 in combustion cycle.";
CM_ SG_ 2364554750 EngnClndr4LwFrqnKnkLvl "Engine Cylinder 4 Low Frequency Knock Level: Indicates the level of low frequency knock for engine cylinder 4. This knock occurs at frequencies below the typical knock level reported on SPNs 1355 & 6410.  The level of low frequency knock is reported ...";
CM_ SG_ 2364554750 EngnClndr4MxmmPrssrInrsRt "Engine Cylinder 4 Maximum Pressure Increase Rate: The maximum slope, in degrees of crank angle, of the pressure increase in engine cylinder 4 during the combustion cycle.";
CM_ SG_ 2364554750 EngnClndr4SnhrnsKnkLvl "Engine Cylinder 4 Synchronous Knock Level: Used to indicate the level of knock for engine cylinder 4. The level of knock is reported using a relative scale where 0% is least level of knock, and increasing levels indicate more knock until 100% indicat...";
CM_ SG_ 2364554750 EngnClndr4PrssrSnsrPrlmnrFm "Engine Cylinder 4 Pressure Sensor Preliminary FMI: Used to identify the applicable J1939-73 FMI detected in the engine cylinder 4 pressure sensor. In the case of multiple failures the most severe is communicated.A value of 31 is sent to indicate that...";
CM_ BO_ 2364555006 "Engine Cylinder 5 Combustion Information";
CM_ SG_ 2364555006 EngineCylinder5HeatRelease "Engine Cylinder 5 Heat Release: The amount of heat produced during combustion in engine cylinder 5.  The negative range is to cover thermodynamic behavior during misfire.";
CM_ SG_ 2364555006 EngineCylinder5PeakPressure "Engine Cylinder 5 Peak Pressure: Peak pressure in engine cylinder 5 in combustion cycle.";
CM_ SG_ 2364555006 EngnClndr5LwFrqnKnkLvl "Engine Cylinder 5 Low Frequency Knock Level: Indicates the level of low frequency knock for engine cylinder 5. This knock occurs at frequencies below the typical knock level reported on SPNs 1356 & 6414.  The level of low frequency knock is reported ...";
CM_ SG_ 2364555006 EngnClndr5MxmmPrssrInrsRt "Engine Cylinder 5 Maximum Pressure Increase Rate: The maximum slope, in degrees of crank angle, of the pressure increase in engine cylinder 5 during the combustion cycle.";
CM_ SG_ 2364555006 EngnClndr5SnhrnsKnkLvl "Engine Cylinder 5 Synchronous Knock Level: Used to indicate the level of knock for engine cylinder 6. The level of knock is reported using a relative scale where 0% is least level of knock, and increasing levels indicate more knock until 100% indicat...";
CM_ SG_ 2364555006 EngnClndr5PrssrSnsrPrlmnrFm "Engine Cylinder 5 Pressure Sensor Preliminary FMI: Used to identify the applicable J1939-73 FMI detected in the engine cylinder 5 pressure sensor.  In the case of multiple failures the most severe is communicated.A value of 31 is sent to indicate tha...";
CM_ BO_ 2364555262 "Engine Cylinder 6 Combustion Information";
CM_ SG_ 2364555262 EngineCylinder6HeatRelease "Engine Cylinder 6 Heat Release: The amount of heat produced during combustion in engine cylinder 6.  The negative range is to cover thermodynamic behavior during misfire.";
CM_ SG_ 2364555262 EngineCylinder6PeakPressure "Engine Cylinder 6 Peak Pressure: Peak pressure in engine cylinder 6 in combustion cycle.";
CM_ SG_ 2364555262 EngnClndr6LwFrqnKnkLvl "Engine Cylinder 6 Low Frequency Knock Level: Indicates the level of low frequency knock for engine cylinder 6. This knock occurs at frequencies below the typical knock level reported on SPNs 1357 & 6418.  The level of low frequency knock is reported ...";
CM_ SG_ 2364555262 EngnClndr6MxmmPrssrInrsRt "Engine Cylinder 6 Maximum Pressure Increase Rate: The maximum slope, in degrees of crank angle, of the pressure increase in engine cylinder 6 during the combustion cycle.";
CM_ SG_ 2364555262 EngnClndr6SnhrnsKnkLvl "Engine Cylinder 6 Synchronous Knock Level: Used to indicate the level of knock for engine cylinder 6. The level of knock is reported using a relative scale where 0% is least level of knock, and increasing levels indicate more knock until 100% indicat...";
CM_ SG_ 2364555262 EngnClndr6PrssrSnsrPrlmnrFm "Engine Cylinder 6 Pressure Sensor Preliminary FMI: Used to identify the applicable J1939-73 FMI detected in the engine cylinder 6 pressure sensor.  In the case of multiple failures the most severe is communicated.A value of 31 is sent to indicate tha...";
CM_ BO_ 2364555518 "Engine Cylinder 7 Combustion Information";
CM_ SG_ 2364555518 EngineCylinder7HeatRelease "Engine Cylinder 7 Heat Release: The amount of heat produced during combustion in engine cylinder 7.  The negative range is to cover thermodynamic behavior during misfire.";
CM_ SG_ 2364555518 EngineCylinder7PeakPressure "Engine Cylinder 7 Peak Pressure: Peak pressure in engine cylinder 7 in combustion cycle.";
CM_ SG_ 2364555518 EngnClndr7LwFrqnKnkLvl "Engine Cylinder 7 Low Frequency Knock Level: Indicates the level of low frequency knock for engine cylinder 7. This knock occurs at frequencies below the typical knock level reported on SPNs 1358 & 6422.  The level of low frequency knock is reported ...";
CM_ SG_ 2364555518 EngnClndr7MxmmPrssrInrsRt "Engine Cylinder 7 Maximum Pressure Increase Rate: The maximum slope, in degrees of crank angle, of the pressure increase in engine cylinder 7 during the combustion cycle.";
CM_ SG_ 2364555518 EngnClndr7SnhrnsKnkLvl "Engine Cylinder 7 Synchronous Knock Level: Used to indicate the level of knock for engine cylinder 7. The level of knock is reported using a relative scale where 0% is least level of knock, and increasing levels indicate more knock until 100% indicat...";
CM_ SG_ 2364555518 EngnClndr7PrssrSnsrPrlmnrFm "Engine Cylinder 7 Pressure Sensor Preliminary FMI: Used to identify the applicable J1939-73 FMI detected in the engine cylinder 7 pressure sensor. In the case of multiple failures the most severe is communicated.A value of 31 is sent to indicate that...";
CM_ BO_ 2364555774 "Engine Cylinder 8 Combustion Information";
CM_ SG_ 2364555774 EngineCylinder8HeatRelease "Engine Cylinder 8 Heat Release: The amount of heat produced during combustion in engine cylinder 8.  The negative range is to cover thermodynamic behavior during misfire.";
CM_ SG_ 2364555774 EngineCylinder8PeakPressure "Engine Cylinder 8 Peak Pressure: Peak pressure in engine cylinder 8 in combustion cycle.";
CM_ SG_ 2364555774 EngnClndr8LwFrqnKnkLvl "Engine Cylinder 8 Low Frequency Knock Level: Indicates the level of low frequency knock for engine cylinder 8. This knock occurs at frequencies below the typical knock level reported on SPNs 1359 & 6426.  The level of low frequency knock is reported ...";
CM_ SG_ 2364555774 EngnClndr8MxmmPrssrInrsRt "Engine Cylinder 8 Maximum Pressure Increase Rate: The maximum slope, in degrees of crank angle, of the pressure increase in engine cylinder 8 during the combustion cycle.";
CM_ SG_ 2364555774 EngnClndr8SnhrnsKnkLvl "Engine Cylinder 8 Synchronous Knock Level: Used to indicate the level of knock for engine cylinder 8. The level of knock is reported using a relative scale where 0% is least level of knock, and increasing levels indicate more knock until 100% indicat...";
CM_ SG_ 2364555774 EngnClndr8PrssrSnsrPrlmnrFm "Engine Cylinder 8 Pressure Sensor Preliminary FMI: Used to identify the applicable J1939-73 FMI detected in the engine cylinder 8 pressure sensor.  In the case of multiple failures the most severe is communicated.A value of 31 is sent to indicate tha...";
CM_ BO_ 2364556030 "Engine Cylinder 9 Combustion Information";
CM_ SG_ 2364556030 EngineCylinder9HeatRelease "Engine Cylinder 9 Heat Release: The amount of heat produced during combustion in engine cylinder 9.  The negative range is to cover thermodynamic behavior during misfire.";
CM_ SG_ 2364556030 EngineCylinder9PeakPressure "Engine Cylinder 9 Peak Pressure: Peak pressure in engine cylinder 9 in combustion cycle.";
CM_ SG_ 2364556030 EngnClndr9LwFrqnKnkLvl "Engine Cylinder 9 Low Frequency Knock Level: Indicates the level of low frequency knock for engine cylinder 9. This knock occurs at frequencies below the typical knock level reported on SPNs 1360 & 6430.  The level of low frequency knock is reported ...";
CM_ SG_ 2364556030 EngnClndr9MxmmPrssrInrsRt "Engine Cylinder 9 Maximum Pressure Increase Rate: The maximum slope, in degrees of crank angle, of the pressure increase in engine cylinder 9 during the combustion cycle.";
CM_ SG_ 2364556030 EngnClndr9SnhrnsKnkLvl "Engine Cylinder 9 Synchronous Knock Level: Used to indicate the level of knock for engine cylinder 9. The level of knock is reported using a relative scale where 0% is least level of knock, and increasing levels indicate more knock until 100% indicat...";
CM_ SG_ 2364556030 EngnClndr9PrssrSnsrPrlmnrFm "Engine Cylinder 9 Pressure Sensor Preliminary FMI: Used to identify the applicable J1939-73 FMI detected in the engine cylinder 9 pressure sensor.  In the case of multiple failures the most severe is communicated.A value of 31 is sent to indicate tha...";
CM_ BO_ 2364556286 "Engine Cylinder 10 Combustion Information";
CM_ SG_ 2364556286 EngineCylinder10HeatRelease "Engine Cylinder 10 Heat Release: The amount of heat produced during combustion in engine cylinder 10.  The negative range is to cover thermodynamic behavior during misfire.";
CM_ SG_ 2364556286 EngineCylinder10PeakPressure "Engine Cylinder 10 Peak Pressure: Peak pressure in engine cylinder 10 in combustion cycle.";
CM_ SG_ 2364556286 EngnClndr10LwFrqnKnkLvl "Engine Cylinder 10 Low Frequency Knock Level: Indicates the level of low frequency knock for engine cylinder 10. This knock occurs at frequencies below the typical knock level reported on SPNs 1361 & 6434.  The level of low frequency knock is reporte...";
CM_ SG_ 2364556286 EngnClndr10MxmmPrssrInrsRt "Engine Cylinder 10 Maximum Pressure Increase Rate: The maximum slope, in degrees of crank angle, of the pressure increase in engine cylinder 10 during the combustion cycle.";
CM_ SG_ 2364556286 EngnClndr10SnhrnsKnkLvl "Engine Cylinder 10 Synchronous Knock Level: Used to indicate the level of knock for engine cylinder 10. The level of knock is reported using a relative scale where 0% is least level of knock, and increasing levels indicate more knock until 100% indic...";
CM_ SG_ 2364556286 EngnClndr10PrssrSnsrPrlmnrFm "Engine Cylinder 10 Pressure Sensor Preliminary FMI: Used to identify the applicable J1939-73 FMI detected in the engine cylinder 10 pressure sensor.  In the case of multiple failures the most severe is communicated.A value of 31 is sent to indicate t...";
CM_ BO_ 2364556542 "Engine Cylinder 11 Combustion Information";
CM_ SG_ 2364556542 EngineCylinder11HeatRelease "Engine Cylinder 11 Heat Release: The amount of heat produced during combustion in engine cylinder 11.  The negative range is to cover thermodynamic behavior during misfire.";
CM_ SG_ 2364556542 EngineCylinder11PeakPressure "Engine Cylinder 11 Peak Pressure: Peak pressure in engine cylinder 11 in combustion cycle.";
CM_ SG_ 2364556542 EngnClndr11LwFrqnKnkLvl "Engine Cylinder 11 Low Frequency Knock Level: Indicates the level of low frequency knock for engine cylinder 11. This knock occurs at frequencies below the typical knock level reported on SPNs 1362 & 6438.  The level of low frequency knock is reporte...";
CM_ SG_ 2364556542 EngnClndr11MxmmPrssrInrsRt "Engine Cylinder 11 Maximum Pressure Increase Rate: The maximum slope, in degrees of crank angle, of the pressure increase in engine cylinder 11 during the combustion cycle.";
CM_ SG_ 2364556542 EngnClndr11SnhrnsKnkLvl "Engine Cylinder 11 Synchronous Knock Level: Used to indicate the level of knock for engine cylinder 11. The level of knock is reported using a relative scale where 0% is least level of knock, and increasing levels indicate more knock until 100% indic...";
CM_ SG_ 2364556542 EngnClndr11PrssrSnsrPrlmnrFm "Engine Cylinder 11 Pressure Sensor Preliminary FMI: Used to identify the applicable J1939-73 FMI detected in the engine cylinder 11 pressure sensor.  In the case of multiple failures the most severe is communicated.A value of 31 is sent to indicate t...";
CM_ BO_ 2364556798 "Engine Cylinder 12 Combustion Information";
CM_ SG_ 2364556798 EngineCylinder12HeatRelease "Engine Cylinder 12 Heat Release: The amount of heat produced during combustion in engine cylinder 12.  The negative range is to cover thermodynamic behavior during misfire.";
CM_ SG_ 2364556798 EngineCylinder12PeakPressure "Engine Cylinder 12 Peak Pressure: Peak pressure in engine cylinder 12 in combustion cycle.";
CM_ SG_ 2364556798 EngnClndr12LwFrqnKnkLvl "Engine Cylinder 12 Low Frequency Knock Level: Indicates the level of low frequency knock for engine cylinder 12. This knock occurs at frequencies below the typical knock level reported on SPNs 1363 & 6442.  The level of low frequency knock is reporte...";
CM_ SG_ 2364556798 EngnClndr12MxmmPrssrInrsRt "Engine Cylinder 12 Maximum Pressure Increase Rate: The maximum slope, in degrees of crank angle, of the pressure increase in engine cylinder 12 during the combustion cycle.";
CM_ SG_ 2364556798 EngnClndr12SnhrnsKnkLvl "Engine Cylinder 12 Synchronous Knock Level: Used to indicate the level of knock for engine cylinder 12. The level of knock is reported using a relative scale where 0% is least level of knock, and increasing levels indicate more knock until 100% indic...";
CM_ SG_ 2364556798 EngnClndr12PrssrSnsrPrlmnrFm "Engine Cylinder 12 Pressure Sensor Preliminary FMI: Used to identify the applicable J1939-73 FMI detected in the engine cylinder 12 pressure sensor.  In the case of multiple failures the most severe is communicated.A value of 31 is sent to indicate t...";
CM_ BO_ 2364557054 "Engine Cylinder 13 Combustion Information";
CM_ SG_ 2364557054 EngineCylinder13HeatRelease "Engine Cylinder 13 Heat Release: The amount of heat produced during combustion in engine cylinder 13.  The negative range is to cover thermodynamic behavior during misfire.";
CM_ SG_ 2364557054 EngineCylinder13PeakPressure "Engine Cylinder 13 Peak Pressure: Peak pressure in engine cylinder 13 in combustion cycle.";
CM_ SG_ 2364557054 EngnClndr13LwFrqnKnkLvl "Engine Cylinder 13 Low Frequency Knock Level: Indicates the level of low frequency knock for engine cylinder 13. This knock occurs at frequencies below the typical knock level reported on SPNs 1364 & 6446.  The level of low frequency knock is reporte...";
CM_ SG_ 2364557054 EngnClndr13MxmmPrssrInrsRt "Engine Cylinder 13 Maximum Pressure Increase Rate: The maximum slope, in degrees of crank angle, of the pressure increase in engine cylinder 13 during the combustion cycle.";
CM_ SG_ 2364557054 EngnClndr13SnhrnsKnkLvl "Engine Cylinder 13 Synchronous Knock Level: Used to indicate the level of knock for engine cylinder 13. The level of knock is reported using a relative scale where 0% is least level of knock, and increasing levels indicate more knock until 100% indic...";
CM_ SG_ 2364557054 EngnClndr13PrssrSnsrPrlmnrFm "Engine Cylinder 13 Pressure Sensor Preliminary FMI: Used to identify the applicable J1939-73 FMI detected in the engine cylinder 13 pressure sensor.  In the case of multiple failures the most severe is communicated.A value of 31 is sent to indicate t...";
CM_ BO_ 2364557310 "Engine Cylinder 14 Combustion Information";
CM_ SG_ 2364557310 EngineCylinder14HeatRelease "Engine Cylinder 14 Heat Release: The amount of heat produced during combustion in engine cylinder 14.  The negative range is to cover thermodynamic behavior during misfire.";
CM_ SG_ 2364557310 EngineCylinder14PeakPressure "Engine Cylinder 14 Peak Pressure: Peak pressure in engine cylinder 14 in combustion cycle.";
CM_ SG_ 2364557310 EngnClndr14LwFrqnKnkLvl "Engine Cylinder 14 Low Frequency Knock Level: Indicates the level of low frequency knock for engine cylinder 14. This knock occurs at frequencies below the typical knock level reported on SPNs 1365 & 6450.  The level of low frequency knock is reporte...";
CM_ SG_ 2364557310 EngnClndr14MxmmPrssrInrsRt "Engine Cylinder 14 Maximum Pressure Increase Rate: The maximum slope, in degrees of crank angle, of the pressure increase in engine cylinder 14 during the combustion cycle.";
CM_ SG_ 2364557310 EngnClndr14SnhrnsKnkLvl "Engine Cylinder 14 Synchronous Knock Level: Used to indicate the level of knock for engine cylinder 14. The level of knock is reported using a relative scale where 0% is least level of knock, and increasing levels indicate more knock until 100% indic...";
CM_ SG_ 2364557310 EngnClndr14PrssrSnsrPrlmnrFm "Engine Cylinder 14 Pressure Sensor Preliminary FMI: Used to identify the applicable J1939-73 FMI detected in the engine cylinder 14 pressure sensor.  In the case of multiple failures the most severe is communicated.A value of 31 is sent to indicate t...";
CM_ BO_ 2364557566 "Engine Cylinder 15 Combustion Information";
CM_ SG_ 2364557566 EngineCylinder15HeatRelease "Engine Cylinder 15 Heat Release: The amount of heat produced during combustion in engine cylinder 15.  The negative range is to cover thermodynamic behavior during misfire.";
CM_ SG_ 2364557566 EngineCylinder15PeakPressure "Engine Cylinder 15 Peak Pressure: Peak pressure in engine cylinder 15 in combustion cycle.";
CM_ SG_ 2364557566 EngnClndr15LwFrqnKnkLvl "Engine Cylinder 15 Low Frequency Knock Level: Indicates the level of low frequency knock for engine cylinder 15. This knock occurs at frequencies below the typical knock level reported on SPNs 1366 & 6454.  The level of low frequency knock is reporte...";
CM_ SG_ 2364557566 EngnClndr15MxmmPrssrInrsRt "Engine Cylinder 15 Maximum Pressure Increase Rate: The maximum slope, in degrees of crank angle, of the pressure increase in engine cylinder 15 during the combustion cycle.";
CM_ SG_ 2364557566 EngnClndr15SnhrnsKnkLvl "Engine Cylinder 15 Synchronous Knock Level: Used to indicate the level of knock for engine cylinder 15. The level of knock is reported using a relative scale where 0% is least level of knock, and increasing levels indicate more knock until 100% indic...";
CM_ SG_ 2364557566 EngnClndr15PrssrSnsrPrlmnrFm "Engine Cylinder 15 Pressure Sensor Preliminary FMI: Used to identify the applicable J1939-73 FMI detected in the engine cylinder 15 pressure sensor.  In the case of multiple failures the most severe is communicated.A value of 31 is sent to indicate t...";
BA_DEF_ SG_  "SPN" INT 0 524287;
BA_DEF_ BO_  "VFrameFormat" ENUM  "StandardCAN","ExtendedCAN","reserved","J1939PG";
BA_DEF_  "DatabaseVersion" STRING ;
BA_DEF_  "BusType" STRING ;
BA_DEF_  "ProtocolType" STRING ;
BA_DEF_  "DatabaseCompiler" STRING ;
BA_DEF_DEF_  "SPN" 0;
BA_DEF_DEF_  "VFrameFormat" "J1939PG";
BA_DEF_DEF_  "DatabaseVersion" "";
BA_DEF_DEF_  "BusType" "";
BA_DEF_DEF_  "ProtocolType" "";
BA_DEF_DEF_  "DatabaseCompiler" "";
BA_ "ProtocolType" "J1939";
BA_ "BusType" "CAN";
BA_ "DatabaseCompiler" "CSS ELECTRONICS (WWW.CSSELECTRONICS.COM)";
BA_ "DatabaseVersion" "2.4";
BA_ "SPN" SG_ 2163223550 CrashChecksum 4975;
BA_ "SPN" SG_ 2163223550 CrashCounter 4974;
BA_ "SPN" SG_ 2163223550 CrashType 4973;
BA_ "SPN" SG_ 2230333950 WandAngle 5821;
BA_ "SPN" SG_ 2230333950 WandSensorFigureOfMerit 5822;
BA_ "SPN" SG_ 2230334206 MeasuredLinearDisplacement 5823;
BA_ "SPN" SG_ 2230334206 LnrDsplmntSnsrSnsrFgrOfMrt 5824;
BA_ "SPN" SG_ 2297441534 DropRelayControl 5403;
BA_ "SPN" SG_ 2297441534 GnrtrCrrntBstAtvStts 5012;
BA_ "SPN" SG_ 2297441534 LiftRelayControl 5402;
BA_ "SPN" SG_ 2297441534 MagnetForwardCurrent 5008;
BA_ "SPN" SG_ 2297441534 MagnetGeneratorControl 5551;
BA_ "SPN" SG_ 2297441534 MagnetReverseCurrent 5009;
BA_ "SPN" SG_ 2297441534 MaterialDropActiveStatus 5014;
BA_ "SPN" SG_ 2297441534 MaterialDropSwitch 5011;
BA_ "SPN" SG_ 2297441534 MaterialLiftActiveStatus 5013;
BA_ "SPN" SG_ 2297441534 MaterialLiftSwitch 5010;
BA_ "SPN" SG_ 2297441790 LngtdnlAlrtnExtnddRng 5348;
BA_ "SPN" SG_ 2297441790 LtrlAlrtnExtnddRng 5347;
BA_ "SPN" SG_ 2297441790 VrtlAlrtnExtnddRng 5349;
BA_ "SPN" SG_ 2297441790 LtrlAlrtnFgrOfMrtExtnddRng 5350;
BA_ "SPN" SG_ 2297441790 LngtdnlAlrtnFgrOfMrtExtnddRng 5351;
BA_ "SPN" SG_ 2297441790 VrtlAlrtnFgrOfMrtExtnddRng 5352;
BA_ "SPN" SG_ 2297441790 SpptVTsssRpttRtFAtSs 5353;
BA_ "SPN" SG_ 2297455358 TrnsmssnDrtnlOtptShftSpd 6585;
BA_ "SPN" SG_ 2297455358 TrnsmssnHdrsttLp1Prssr 6583;
BA_ "SPN" SG_ 2297455358 TrnsmssnHdrsttLp2Prssr 6584;
BA_ "SPN" SG_ 2297455358 TrnsmssnIntrmdtShftSpd 160;
BA_ "SPN" SG_ 2297499902 BrakePedalSwitch2 603;
BA_ "SPN" SG_ 2297499902 DmnddBrkAppltnPrssr 8484;
BA_ "SPN" SG_ 2298375934 FrontAxleLeftWheelSpeed 1592;
BA_ "SPN" SG_ 2298375934 FrontAxleRightWheelSpeed 1593;
BA_ "SPN" SG_ 2298375934 RearAxleLeftWheelSpeed 1594;
BA_ "SPN" SG_ 2298375934 RearAxleRightWheelSpeed 1595;
BA_ "SPN" SG_ 2348941054 DisengageDrivelineRequest 683;
BA_ "SPN" SG_ 2348941054 DsnggDffrntlLkRqstCntrl 689;
BA_ "SPN" SG_ 2348941054 DsnggDffrntlLkRqstCntrlFrnt 690;
BA_ "SPN" SG_ 2348941054 DsnggDffrntlLkRqstCntrlRr 691;
BA_ "SPN" SG_ 2348941054 DsnggDffrntlLkRqstFrntAxl1 685;
BA_ "SPN" SG_ 2348941054 DsnggDffrntlLkRqstFrntAxl2 686;
BA_ "SPN" SG_ 2348941054 DsnggDffrntlLkRqstRrAxl1 687;
BA_ "SPN" SG_ 2348941054 DsnggDffrntlLkRqstRrAxl2 688;
BA_ "SPN" SG_ 2348941054 RequestedPercentClutchSlip 684;
BA_ "SPN" SG_ 2348941054 TransmissionMode1 1852;
BA_ "SPN" SG_ 2348941054 TransmissionMode2 1853;
BA_ "SPN" SG_ 2348941054 TransmissionMode3 1854;
BA_ "SPN" SG_ 2348941054 TransmissionMode4 1855;
BA_ "SPN" SG_ 2348941054 TransmissionMode5 4246;
BA_ "SPN" SG_ 2348941054 TransmissionMode6 4247;
BA_ "SPN" SG_ 2348941054 TransmissionMode7 4248;
BA_ "SPN" SG_ 2348941054 TransmissionMode8 4249;
BA_ "SPN" SG_ 2348941054 TransmissionRequestedGear 525;
BA_ "SPN" SG_ 2348941054 TransmissionRequestedLaunchGear 4255;
BA_ "SPN" SG_ 2348941054 TrnsmssnAtNtrlMnlRtrnRqst 7695;
BA_ "SPN" SG_ 2348941054 TrnsmssnGrShftInhtRqst 681;
BA_ "SPN" SG_ 2348941054 TrnsmssnLdRdtnInhtRqst 5762;
BA_ "SPN" SG_ 2348941054 TrnsmssnRvrsGrShftInhtRqst 4242;
BA_ "SPN" SG_ 2348941054 TrnsmssnShftSltrDsplMdSwth 2985;
BA_ "SPN" SG_ 2348941054 TrnsmssnTrqCnvrtrLkpRqst 682;
BA_ "SPN" SG_ 2349137662 ExternalAccelerationDemand 2920;
BA_ "SPN" SG_ 2349137662 XbrControlMode 2916;
BA_ "SPN" SG_ 2349137662 XbrEbiMode 2914;
BA_ "SPN" SG_ 2349137662 XbrMessageChecksum 3188;
BA_ "SPN" SG_ 2349137662 XbrMessageCounter 3189;
BA_ "SPN" SG_ 2349137662 XbrPriority 2915;
BA_ "SPN" SG_ 2349137662 XbrUrgency 4099;
BA_ "SPN" SG_ 2349137662 XbrCompensationMode 15201;
BA_ "SPN" SG_ 2349137662 XbrBrakeHoldRequest 15263;
BA_ "SPN" SG_ 2349137662 XbrReason 23465;
BA_ "SPN" SG_ 2349399806 AuxiliaryIOChannel3 4158;
BA_ "SPN" SG_ 2349399806 AuxiliaryIOChannel4 4157;
BA_ "SPN" SG_ 2349399806 AuxiliaryIOChannel5 4156;
BA_ "SPN" SG_ 2349399806 AuxiliaryIOChannel6 4155;
BA_ "SPN" SG_ 2349465342 StaticRollAngle 5582;
BA_ "SPN" SG_ 2349465342 StaticRollAngleStatus 5583;
BA_ "SPN" SG_ 2349530878 CruiseControlDisableCommand 5603;
BA_ "SPN" SG_ 2349530878 CruiseControlPauseCommand 5605;
BA_ "SPN" SG_ 2349530878 CruiseControlResumeCommand 5604;
BA_ "SPN" SG_ 2349530878 IdleControlEnableState 8439;
BA_ "SPN" SG_ 2349530878 IdleControlRequestActivation 8440;
BA_ "SPN" SG_ 2349530878 IdleSpeedRequest 8438;
BA_ "SPN" SG_ 2349530878 CruiseControlSetCommand 9843;
BA_ "SPN" SG_ 2349530878 RemoteVehicleSpeedLimitRequest 9569;
BA_ "SPN" SG_ 2349596414 Aebs2MessageChecksum 5683;
BA_ "SPN" SG_ 2349596414 Aebs2MessageCounter 5682;
BA_ "SPN" SG_ 2349596414 DvAtvtDdFAdvdEBSst 5681;
BA_ "SPN" SG_ 2349727486 TransmissionMode10 6570;
BA_ "SPN" SG_ 2349727486 TransmissionMode9 6569;
BA_ "SPN" SG_ 2349727486 TrnsmssnPrDfndMxmmGrAtvtnRqst 11751;
BA_ "SPN" SG_ 2349727486 TrnsmssnOtptShftBrkRqst 11752;
BA_ "SPN" SG_ 2349727486 TrnsmssnRqstdRvrsLnhGr 11753;
BA_ "SPN" SG_ 2349727486 SltdMxmmGrLmtAtvtnRqst 11754;
BA_ "SPN" SG_ 2349727486 TransmissionMode11 12949;
BA_ "SPN" SG_ 2349727486 TransmissionMode12 12950;
BA_ "SPN" SG_ 2349727486 TransmissionMode13 12951;
BA_ "SPN" SG_ 2349727486 TransmissionMode14 12952;
BA_ "SPN" SG_ 2349727486 TransmissionMode15 12953;
BA_ "SPN" SG_ 2349727486 TransmissionMode16 12954;
BA_ "SPN" SG_ 2349727486 TransmissionMode17 12955;
BA_ "SPN" SG_ 2349727486 TransmissionMode18 12956;
BA_ "SPN" SG_ 2349727486 TransmissionMode19 12957;
BA_ "SPN" SG_ 2349727486 TransmissionMode20 12958;
BA_ "SPN" SG_ 2349727486 DsnggDffrntlLkRqstRrAxl3 13072;
BA_ "SPN" SG_ 2349727486 TrnsmssnCstMdDslRqst 22217;
BA_ "SPN" SG_ 2349727486 TrnsmssnExpltMnlMdRqst 23296;
BA_ "SPN" SG_ 2350644990 HvessPowerDownCommand 8124;
BA_ "SPN" SG_ 2350644990 HvessCellBalancingCommand 8127;
BA_ "SPN" SG_ 2350644990 HvessOperationConsent 8412;
BA_ "SPN" SG_ 2350644990 HvessControl1Counter 13027;
BA_ "SPN" SG_ 2350644990 HvessControl1Crc 13028;
BA_ "SPN" SG_ 2350644990 HvssHghVltgBsCnntCmmnd 8123;
BA_ "SPN" SG_ 2350644990 HvssHghVltgBsAtvIsltnTstCmmnd 8125;
BA_ "SPN" SG_ 2350644990 HvssHghVltgBsPssvIsltnTstCmmnd 8126;
BA_ "SPN" SG_ 2350644990 HvssEnlIntrnlChrgrCmmnd 8213;
BA_ "SPN" SG_ 2350644990 HvssHghVltgBsHghSdRsstrCnntRqst 8433;
BA_ "SPN" SG_ 2350644990 HvssHghVltgBsLwSdRsstrCnntRqst 8434;
BA_ "SPN" SG_ 2350644990 HvssThrmlMngmntMntnnRqst 20878;
BA_ "SPN" SG_ 2350710526 TsssOvdCtMdOstUsSp23369 7037;
BA_ "SPN" SG_ 2350710526 TsssOvdCtMdPtOstUsSp23370 7038;
BA_ "SPN" SG_ 2350710526 MssgCntrOsltUsSpn23375 7041;
BA_ "SPN" SG_ 2350710526 TsssRqstdOtptStSpdOstUsSp23371 7039;
BA_ "SPN" SG_ 2350710526 TsssRqstdTqTqLtOstUsSp23372 7040;
BA_ "SPN" SG_ 2350710526 TsssAtNtAtRtESwtOstUsSp23373 21251;
BA_ "SPN" SG_ 2350710526 TsssAtNtAtRtRqstOstUsSp23374 21252;
BA_ "SPN" SG_ 2350710526 MssgChksmOsltUsSpn23376 7042;
BA_ "SPN" SG_ 2350776062 EngineTimingAdvance 7355;
BA_ "SPN" SG_ 2350841598 AlternatorTorqueRampTimeCommand 7591;
BA_ "SPN" SG_ 2350841598 AltrntrExttnMxmmCrrntLmt 7590;
BA_ "SPN" SG_ 2350841598 AltrntrStpntVltgCmmnd 7589;
BA_ "SPN" SG_ 2350841598 AltrntrTrqRmpMxmmSpdCmmnd 7592;
BA_ "SPN" SG_ 2358902526 Joystick1Lamp10Command 4469;
BA_ "SPN" SG_ 2358902526 Joystick1Lamp1Command 4460;
BA_ "SPN" SG_ 2358902526 Joystick1Lamp2Command 4461;
BA_ "SPN" SG_ 2358902526 Joystick1Lamp3Command 4462;
BA_ "SPN" SG_ 2358902526 Joystick1Lamp4Command 4463;
BA_ "SPN" SG_ 2358902526 Joystick1Lamp5Command 4464;
BA_ "SPN" SG_ 2358902526 Joystick1Lamp6Command 4465;
BA_ "SPN" SG_ 2358902526 Joystick1Lamp7Command 4466;
BA_ "SPN" SG_ 2358902526 Joystick1Lamp8Command 4467;
BA_ "SPN" SG_ 2358902526 Joystick1Lamp9Command 4468;
BA_ "SPN" SG_ 2358902526 Joystick2Lamp10Command 4479;
BA_ "SPN" SG_ 2358902526 Joystick2Lamp1Command 4470;
BA_ "SPN" SG_ 2358902526 Joystick2Lamp2Command 4471;
BA_ "SPN" SG_ 2358902526 Joystick2Lamp3Command 4472;
BA_ "SPN" SG_ 2358902526 Joystick2Lamp4Command 4473;
BA_ "SPN" SG_ 2358902526 Joystick2Lamp5Command 4474;
BA_ "SPN" SG_ 2358902526 Joystick2Lamp6Command 4475;
BA_ "SPN" SG_ 2358902526 Joystick2Lamp7Command 4476;
BA_ "SPN" SG_ 2358902526 Joystick2Lamp8Command 4477;
BA_ "SPN" SG_ 2358902526 Joystick2Lamp9Command 4478;
BA_ "SPN" SG_ 2358902526 Joystick3Lamp10Command 4489;
BA_ "SPN" SG_ 2358902526 Joystick3Lamp1Command 4480;
BA_ "SPN" SG_ 2358902526 Joystick3Lamp2Command 4481;
BA_ "SPN" SG_ 2358902526 Joystick3Lamp3Command 4482;
BA_ "SPN" SG_ 2358902526 Joystick3Lamp4Command 4483;
BA_ "SPN" SG_ 2358902526 Joystick3Lamp5Command 4484;
BA_ "SPN" SG_ 2358902526 Joystick3Lamp6Command 4485;
BA_ "SPN" SG_ 2358902526 Joystick3Lamp7Command 4486;
BA_ "SPN" SG_ 2358902526 Joystick3Lamp8Command 4487;
BA_ "SPN" SG_ 2358902526 Joystick3Lamp9Command 4488;
BA_ "SPN" SG_ 2362572542 LevelPresetFrontAxleLeft 1732;
BA_ "SPN" SG_ 2362572542 LevelPresetFrontAxleRight 1757;
BA_ "SPN" SG_ 2362572542 LevelPresetRearAxleLeft 1758;
BA_ "SPN" SG_ 2362572542 LevelPresetRearAxleRight 1735;
BA_ "SPN" SG_ 2362638078 AllwLvlCntrlDrngBrkngCmmnd 5293;
BA_ "SPN" SG_ 2362638078 AtmtTrtnHlpLdTrnsfr 2984;
BA_ "SPN" SG_ 2362638078 DamperStiffnessRequestFrontAxle 1718;
BA_ "SPN" SG_ 2362638078 DamperStiffnessRequestRearAxle 1719;
BA_ "SPN" SG_ 2362638078 DmprStffnssRqstLftTgAxl 1720;
BA_ "SPN" SG_ 2362638078 KneelingCommandFrontAxle 1830;
BA_ "SPN" SG_ 2362638078 KneelingCommandRearAxle 1829;
BA_ "SPN" SG_ 2362638078 KneelingControlModeRequest 1747;
BA_ "SPN" SG_ 2362638078 KneelingRequestLeftSide 1749;
BA_ "SPN" SG_ 2362638078 KneelingRequestRightSide 1748;
BA_ "SPN" SG_ 2362638078 LevelControlModeRequest 1753;
BA_ "SPN" SG_ 2362638078 LiftAxle1PositionCommand 1752;
BA_ "SPN" SG_ 2362638078 LiftAxle2PositionCommand 1828;
BA_ "SPN" SG_ 2362638078 MemoryLevelRequest 5433;
BA_ "SPN" SG_ 2362638078 NominalLevelRequestFrontAxle 1751;
BA_ "SPN" SG_ 2362638078 NominalLevelRequestRearAxle 1750;
BA_ "SPN" SG_ 2362638078 PrhtAtmtArSspnsnCntrl 5274;
BA_ "SPN" SG_ 2362638078 ProhibitAirSuspensionControl 3215;
BA_ "SPN" SG_ 2362638078 SpdDpndntLvlCntrlRqst 5295;
BA_ "SPN" SG_ 2364539646 EngineMomentaryOverspeedEnable 606;
BA_ "SPN" SG_ 2364539646 MmntrEngnMxmmPwrEnl 5015;
BA_ "SPN" SG_ 2364539646 PercentClutchSlip 522;
BA_ "SPN" SG_ 2364539646 ProgressiveShiftDisable 607;
BA_ "SPN" SG_ 2364539646 TransmissionDrivelineEngaged 560;
BA_ "SPN" SG_ 2364539646 TransmissionShiftInProcess 574;
BA_ "SPN" SG_ 2364539646 TrnsmssnTrqCnvrtrLkpEnggd 573;
BA_ "SPN" SG_ 2364539646 TsssTqCvtLpTstIPss 4816;
BA_ "SPN" SG_ 2364539646 SAddssOCtDvFTsssCt 1482;
BA_ "SPN" SG_ 2364539646 TransmissionOutputShaftSpeed 191;
BA_ "SPN" SG_ 2364539646 TransmissionInputShaftSpeed 161;
BA_ "SPN" SG_ 2364539902 AcceleratorPedal1LowIdleSwitch 558;
BA_ "SPN" SG_ 2364539902 AcceleratorPedal2LowIdleSwitch 2970;
BA_ "SPN" SG_ 2364539902 AcceleratorPedalKickdownSwitch 559;
BA_ "SPN" SG_ 2364539902 AtlMxmmAvllEngnPrntTrq 3357;
BA_ "SPN" SG_ 2364539902 DpfThermalManagementActive 5399;
BA_ "SPN" SG_ 2364539902 EnginePercentLoadAtCurrentSpeed 92;
BA_ "SPN" SG_ 2364539902 EstimatedPumpingPercentTorque 5398;
BA_ "SPN" SG_ 2364539902 MmntrEngnMxmmPwrEnlFdk 5021;
BA_ "SPN" SG_ 2364539902 RemoteAcceleratorPedalPosition 974;
BA_ "SPN" SG_ 2364539902 RoadSpeedLimitStatus 1437;
BA_ "SPN" SG_ 2364539902 ScrThermalManagementActive 5400;
BA_ "SPN" SG_ 2364539902 VhlAlrtnRtLmtStts 2979;
BA_ "SPN" SG_ 2364539902 AcceleratorPedal2Position 29;
BA_ "SPN" SG_ 2364539902 AcceleratorPedal1Position 91;
BA_ "SPN" SG_ 2364540158 ActualEnginePercentTorque 513;
BA_ "SPN" SG_ 2364540158 AtlEngnPrntTrqFrtnl 4154;
BA_ "SPN" SG_ 2364540158 DrvrSDmndEngnPrntTrq 512;
BA_ "SPN" SG_ 2364540158 EngineSpeed 190;
BA_ "SPN" SG_ 2364540158 EngineStarterMode 1675;
BA_ "SPN" SG_ 2364540158 EngineTorqueMode 899;
BA_ "SPN" SG_ 2364540158 EngineDemandPercentTorque 2432;
BA_ "SPN" SG_ 2364540158 SrAddrssOfCntrllngDvFrEngnCntrl 1483;
BA_ "SPN" SG_ 2364541694 EngineIntakeAirMassFlowRate 132;
BA_ "SPN" SG_ 2364541694 EngnExhstGsRrltn1MssFlwRt 2659;
BA_ "SPN" SG_ 2364541694 EngnExhstGsRrltn2MssFlwRt 5257;
BA_ "SPN" SG_ 2364541694 TargetFreshAirMassFlow 12758;
BA_ "SPN" SG_ 2364542206 TrnsmssnClthCnvrtrInptSpd 5052;
BA_ "SPN" SG_ 2364542206 TrnsmssnTrqCnvrtrRt 3030;
BA_ "SPN" SG_ 2364542206 TransmissionShiftInhibitReason 10152;
BA_ "SPN" SG_ 2364542206 TrnsmssnTrqCnvrtrLkpInhtRsn 10151;
BA_ "SPN" SG_ 2364542206 TrnsmssnTrqCnvrtrLkpInhtIndtr 10150;
BA_ "SPN" SG_ 2364542206 TrnsmssnExpltMnlMdIndtr 23297;
BA_ "SPN" SG_ 2364542462 BladeAutoModeCommand 3158;
BA_ "SPN" SG_ 2364542462 BladeControlModeSwitch 3156;
BA_ "SPN" SG_ 2364542462 DesiredGradeOffsetSwitch 3157;
BA_ "SPN" SG_ 2364542462 LftBldCntrlMdOprtrCntrl 3334;
BA_ "SPN" SG_ 2364542462 LftDsrdBldOffstOprtrCntrl 3336;
BA_ "SPN" SG_ 2364542462 RghtBldCntrlMdOprtrCntrl 3335;
BA_ "SPN" SG_ 2364542462 RghtDsrdBldOffstOprtrCntrl 3337;
BA_ "SPN" SG_ 2364542462 SdShftBldCntrlMdOprtrCntrl 3338;
BA_ "SPN" SG_ 2364542462 SdShftDsrdBldOffstOprtrCntrl 3339;
BA_ "SPN" SG_ 2364542462 StElvtnSnsr1RfrnElvtn 5405;
BA_ "SPN" SG_ 2364542462 StElvtnSnsr2RfrnElvtn 5406;
BA_ "SPN" SG_ 2364543998 PitchAndRollCompensated 3326;
BA_ "SPN" SG_ 2364543998 PitchAngle 3318;
BA_ "SPN" SG_ 2364543998 PitchAngleFigureOfMerit 3323;
BA_ "SPN" SG_ 2364543998 PitchRate 3322;
BA_ "SPN" SG_ 2364543998 PitchRateFigureOfMerit 3325;
BA_ "SPN" SG_ 2364543998 RollAndPitchMeasurementLatency 3327;
BA_ "SPN" SG_ 2364543998 RollAngle 3319;
BA_ "SPN" SG_ 2364543998 RollAngleFigureOfMerit 3324;
BA_ "SPN" SG_ 2364544254 BladeRotationAngle 3331;
BA_ "SPN" SG_ 2364544254 BladeRotationAngleFigureOfMerit 3332;
BA_ "SPN" SG_ 2364544254 RelativeBladeHeight 3365;
BA_ "SPN" SG_ 2364544254 RtvBdHtAdBdRttAMstLt 3366;
BA_ "SPN" SG_ 2364544254 RltvBldHghtFgrOfMrt 3367;
BA_ "SPN" SG_ 2364544510 RqstdGnrtrOvrllPwrFtr 3384;
BA_ "SPN" SG_ 2364544510 RqstdGnrtrOvrllPwrFtrLggng 3385;
BA_ "SPN" SG_ 2364544510 RqstdGnrtrTtlARtvPwr 3383;
BA_ "SPN" SG_ 2364544766 EngineCylinder1CombustionStatus 3387;
BA_ "SPN" SG_ 2364544766 EngineCylinder2CombustionStatus 3388;
BA_ "SPN" SG_ 2364544766 EngineCylinder3CombustionStatus 3389;
BA_ "SPN" SG_ 2364544766 EngineCylinder4CombustionStatus 3390;
BA_ "SPN" SG_ 2364544766 EngineCylinder5CombustionStatus 3391;
BA_ "SPN" SG_ 2364544766 EngineCylinder6CombustionStatus 3392;
BA_ "SPN" SG_ 2364544766 EngineCylinder7CombustionStatus 3393;
BA_ "SPN" SG_ 2364544766 EngineCylinder8CombustionStatus 3394;
BA_ "SPN" SG_ 2364544766 EngineCylinder9CombustionStatus 3395;
BA_ "SPN" SG_ 2364544766 EngnClndr10CmstnStts 3396;
BA_ "SPN" SG_ 2364544766 EngnClndr11CmstnStts 3397;
BA_ "SPN" SG_ 2364544766 EngnClndr12CmstnStts 3398;
BA_ "SPN" SG_ 2364544766 EngnClndr13CmstnStts 3399;
BA_ "SPN" SG_ 2364544766 EngnClndr14CmstnStts 3400;
BA_ "SPN" SG_ 2364544766 EngnClndr15CmstnStts 3401;
BA_ "SPN" SG_ 2364544766 EngnClndr16CmstnStts 3402;
BA_ "SPN" SG_ 2364544766 EngnClndr17CmstnStts 3403;
BA_ "SPN" SG_ 2364544766 EngnClndr18CmstnStts 3404;
BA_ "SPN" SG_ 2364544766 EngnClndr19CmstnStts 3405;
BA_ "SPN" SG_ 2364544766 EngnClndr20CmstnStts 3406;
BA_ "SPN" SG_ 2364544766 EngnClndr21CmstnStts 3407;
BA_ "SPN" SG_ 2364544766 EngnClndr22CmstnStts 3408;
BA_ "SPN" SG_ 2364544766 EngnClndr23CmstnStts 3409;
BA_ "SPN" SG_ 2364544766 EngnClndr24CmstnStts 3410;
BA_ "SPN" SG_ 2364545022 EngineCylinder1KnockLevel 1352;
BA_ "SPN" SG_ 2364545022 EngineCylinder2KnockLevel 1353;
BA_ "SPN" SG_ 2364545022 EngineCylinder3KnockLevel 1354;
BA_ "SPN" SG_ 2364545022 EngineCylinder4KnockLevel 1355;
BA_ "SPN" SG_ 2364545022 EngineCylinder5KnockLevel 1356;
BA_ "SPN" SG_ 2364545022 EngineCylinder6KnockLevel 1357;
BA_ "SPN" SG_ 2364545022 EngineCylinder7KnockLevel 1358;
BA_ "SPN" SG_ 2364545022 EngineCylinder8KnockLevel 1359;
BA_ "SPN" SG_ 2364545278 EngineCylinder10KnockLevel 1361;
BA_ "SPN" SG_ 2364545278 EngineCylinder11KnockLevel 1362;
BA_ "SPN" SG_ 2364545278 EngineCylinder12KnockLevel 1363;
BA_ "SPN" SG_ 2364545278 EngineCylinder13KnockLevel 1364;
BA_ "SPN" SG_ 2364545278 EngineCylinder14KnockLevel 1365;
BA_ "SPN" SG_ 2364545278 EngineCylinder15KnockLevel 1366;
BA_ "SPN" SG_ 2364545278 EngineCylinder16KnockLevel 1367;
BA_ "SPN" SG_ 2364545278 EngineCylinder9KnockLevel 1360;
BA_ "SPN" SG_ 2364545534 EngineCylinder17KnockLevel 1368;
BA_ "SPN" SG_ 2364545534 EngineCylinder18KnockLevel 1369;
BA_ "SPN" SG_ 2364545534 EngineCylinder19KnockLevel 1370;
BA_ "SPN" SG_ 2364545534 EngineCylinder20KnockLevel 1371;
BA_ "SPN" SG_ 2364545534 EngineCylinder21KnockLevel 1372;
BA_ "SPN" SG_ 2364545534 EngineCylinder22KnockLevel 1373;
BA_ "SPN" SG_ 2364545534 EngineCylinder23KnockLevel 1374;
BA_ "SPN" SG_ 2364545534 EngineCylinder24KnockLevel 1375;
BA_ "SPN" SG_ 2364546302 RqstdGnrtrAvrgLnLnARmsVltg 3386;
BA_ "SPN" SG_ 2364546814 EngineLoadSetpointRequest 8430;
BA_ "SPN" SG_ 2364546814 EngineSelfInducedDerateInhibit 8429;
BA_ "SPN" SG_ 2364546814 GeneratorGoverningBias 3938;
BA_ "SPN" SG_ 2364548094 Aftertreatment1ScrSystem1State 4332;
BA_ "SPN" SG_ 2364548094 Aftertreatment1ScrSystem2State 7524;
BA_ "SPN" SG_ 2364548094 Atttt1DsExstFdAtDsQtt 4331;
BA_ "SPN" SG_ 2364548094 Atttt1DsExstFdAtDsQttHR 6595;
BA_ "SPN" SG_ 2364548094 Atttt1DsExstFdDs1AstPss 4334;
BA_ "SPN" SG_ 2364548094 Atttt1DsExstFdAtQttOItt 4333;
BA_ "SPN" SG_ 2364548350 Atttt1DsExstFdDsRqstdQtt 4348;
BA_ "SPN" SG_ 2364548350 Atttt1DsExstFdDsRqstdQttHR 6593;
BA_ "SPN" SG_ 2364548350 Atttt1DsExstFdDsTstItPssStts 7518;
BA_ "SPN" SG_ 2364548350 Atttt1DsExstFdHdStssCPssStts 7517;
BA_ "SPN" SG_ 2364548350 Aftrtrtmnt1SrSstmRqstdStt 4349;
BA_ "SPN" SG_ 2364548350 Atttt1DsExstFdRqstdQttOItt 4350;
BA_ "SPN" SG_ 2364548606 Aftertreatment1OutletNh3 4377;
BA_ "SPN" SG_ 2364548606 Aftrtrtmnt1OtltNh3RdngStl 4379;
BA_ "SPN" SG_ 2364548606 Aftrtrtmnt1OtltNh3SnsrPrlmnrFm 4378;
BA_ "SPN" SG_ 2364548606 Atttt1OttN3GsSsPwIR 4380;
BA_ "SPN" SG_ 2364548606 Atttt1OttN3GsSsAtTpt 4381;
BA_ "SPN" SG_ 2364548606 Atttt1OttN3GsSsHtPF 4382;
BA_ "SPN" SG_ 2364548606 Atttt1OttN3GsSsHtCt 4383;
BA_ "SPN" SG_ 2364548862 Aftertreatment2ScrSystem1State 4385;
BA_ "SPN" SG_ 2364548862 Aftertreatment2ScrSystem2State 7525;
BA_ "SPN" SG_ 2364548862 Atttt2DsExstFdAtDsQtt 4384;
BA_ "SPN" SG_ 2364548862 Atttt2DsExstFdAtDsQttHR 6596;
BA_ "SPN" SG_ 2364548862 Atttt2DsExstFdDs1AstPss 4387;
BA_ "SPN" SG_ 2364548862 Atttt2DsExstFdAtQttOItt 4386;
BA_ "SPN" SG_ 2364549118 Atttt2DsExstFdDsRqstdQtt 4401;
BA_ "SPN" SG_ 2364549118 Atttt2DsExstFdDsRqstdQttHR 6594;
BA_ "SPN" SG_ 2364549118 Atttt2DsExstFdDsTstItPssStts 7520;
BA_ "SPN" SG_ 2364549118 Atttt2DsExstFdHdStssCPssStts 7519;
BA_ "SPN" SG_ 2364549118 Atttt2DsExstFdPpHtCd 7087;
BA_ "SPN" SG_ 2364549118 Aftrtrtmnt2SrSstmRqstdStt 4402;
BA_ "SPN" SG_ 2364549118 Atttt2DsExstFdRqstdQttOItt 4403;
BA_ "SPN" SG_ 2364549374 Aftertreatment2OutletNh3 4443;
BA_ "SPN" SG_ 2364549374 Aftrtrtmnt2OtltNh3RdngStl 4445;
BA_ "SPN" SG_ 2364549374 Aftrtrtmnt2OtltNh3SnsrPrlmnrFm 4444;
BA_ "SPN" SG_ 2364549374 Atttt2OttN3GsSsPwIR 4446;
BA_ "SPN" SG_ 2364549374 Atttt2OttN3GsSsAtTpt 4447;
BA_ "SPN" SG_ 2364549374 Atttt2OttN3GsSsHtPF 4448;
BA_ "SPN" SG_ 2364549374 Atttt2OttN3GsSsHtCt 4449;
BA_ "SPN" SG_ 2364549630 PitchAngleExtendedRange 4976;
BA_ "SPN" SG_ 2364549630 PthAnglCmpnstnExtnddRng 4978;
BA_ "SPN" SG_ 2364549630 RllAnglCmpnstnExtnddRng 4980;
BA_ "SPN" SG_ 2364549630 RollAngleExtendedRange 4977;
BA_ "SPN" SG_ 2364549630 PthAnglFgrOfMrtExtnddRng 4979;
BA_ "SPN" SG_ 2364549630 RllAnglFgrOfMrtExtnddRng 4981;
BA_ "SPN" SG_ 2364549630 RllAndPthMsrmntLtnExtnddRng 4982;
BA_ "SPN" SG_ 2364549886 AngularRateMeasurementLatency 4989;
BA_ "SPN" SG_ 2364549886 PitchRateExtendedRange 4983;
BA_ "SPN" SG_ 2364549886 RollRateExtendedRange 4984;
BA_ "SPN" SG_ 2364549886 YawRateExtendedRange 4985;
BA_ "SPN" SG_ 2364549886 PthRtFgrOfMrtExtnddRng 4986;
BA_ "SPN" SG_ 2364549886 RllRtFgrOfMrtExtnddRng 4987;
BA_ "SPN" SG_ 2364549886 YwRtFgrOfMrtExtnddRng 4988;
BA_ "SPN" SG_ 2364551166 CollisionWarningLevel 5677;
BA_ "SPN" SG_ 2364551166 FwdCsAdvdEBSstStt 5676;
BA_ "SPN" SG_ 2364551166 RdDprtrAdvndEmrgnBrkngSstmStt 9748;
BA_ "SPN" SG_ 2364551166 RvtOtDttdFAdvdEBSst 5678;
BA_ "SPN" SG_ 2364551166 BndOffPrltOfRlvntOjt 5679;
BA_ "SPN" SG_ 2364551166 TmTCllsnWthRlvntOjt 5680;
BA_ "SPN" SG_ 2364551422 TransmitterCommandState 5751;
BA_ "SPN" SG_ 2364551422 TransmitterId1 5752;
BA_ "SPN" SG_ 2364551422 WirelessRollingMessageCounter 5750;
BA_ "SPN" SG_ 2364551422 WirelessSignalStrength1 5753;
BA_ "SPN" SG_ 2364552958 HvssDshrgPwrLmtDTSttOfChrg 8103;
BA_ "SPN" SG_ 2364552958 HvssDshrgPwrLmtDTBttrTmprtr 8104;
BA_ "SPN" SG_ 2364552958 HvssDshrgPwrLmtDTBttrDgnstCndtn 8105;
BA_ "SPN" SG_ 2364552958 HvssDshrgPwrLmtDTBttrOrCllVltg 8106;
BA_ "SPN" SG_ 2364552958 HvssDshrgPwrLmtDTBttrCrrnt 8107;
BA_ "SPN" SG_ 2364552958 HvssDshrgPwrLmtDTAnUndfndCs 8108;
BA_ "SPN" SG_ 2364552958 HvssChrgPwrLmtDTSttOfChrg 8109;
BA_ "SPN" SG_ 2364552958 HvssChrgPwrLmtDTBttrTmprtr 8110;
BA_ "SPN" SG_ 2364552958 HvssChrgPwrLmtDTBttrDgnstCndtn 8111;
BA_ "SPN" SG_ 2364552958 HvssChrgPwrLmtDTBttrOrCllVltg 8112;
BA_ "SPN" SG_ 2364552958 HvssChrgPwrLmtDTBttrCrrnt 8113;
BA_ "SPN" SG_ 2364552958 HvssChrgPwrLmtDTAnUndfndCs 8114;
BA_ "SPN" SG_ 2364552958 HvssDsPwLtDTPwMdEtsTpt 22824;
BA_ "SPN" SG_ 2364552958 HvssCPwLtDTPwMdEtsTpt 22823;
BA_ "SPN" SG_ 2364553214 EngnTrhrgrCmprssrBlwffAttr1Pstn 6315;
BA_ "SPN" SG_ 2364553214 ETCpssBwAtt1DsdPst 6314;
BA_ "SPN" SG_ 2364553214 ETCpssBwAtt1OptStts 6316;
BA_ "SPN" SG_ 2364553214 ETCpssBwAtt1Tpt 6313;
BA_ "SPN" SG_ 2364553214 ETCpssBwAtt1TptStts 6312;
BA_ "SPN" SG_ 2364553214 ETCpssBwAtt1PF 6311;
BA_ "SPN" SG_ 2364553470 EngineCylinderTorque 6389;
BA_ "SPN" SG_ 2364553470 EngineDualFuelModeCommand 6792;
BA_ "SPN" SG_ 2364553470 EngnClndrDslMssFlwRtCmmnd 6388;
BA_ "SPN" SG_ 2364553470 EngnClndrGsMssFlwRtCmmnd 6387;
BA_ "SPN" SG_ 2364553470 EngnGsSstttnFlPrntgCmmnd 6386;
BA_ "SPN" SG_ 2364553726 EngineDesiredAirFuelRatio 6392;
BA_ "SPN" SG_ 2364553726 EngnFlSstm1TtlIntkMssArFlwRt 6393;
BA_ "SPN" SG_ 2364553726 EngnFlSstm2TtlIntkMssArFlwRt 8310;
BA_ "SPN" SG_ 2364553726 CommandedEquivalenceRatio 23212;
BA_ "SPN" SG_ 2364553982 EngineCylinder1HeatRelease 6396;
BA_ "SPN" SG_ 2364553982 EngineCylinder1PeakPressure 6397;
BA_ "SPN" SG_ 2364553982 EngnClndr1LwFrqnKnkLvl 7609;
BA_ "SPN" SG_ 2364553982 EngnClndr1MxmmPrssrInrsRt 7629;
BA_ "SPN" SG_ 2364553982 EngnClndr1SnhrnsKnkLvl 6398;
BA_ "SPN" SG_ 2364553982 EngnClndr1PrssrSnsrPrlmnrFm 6399;
BA_ "SPN" SG_ 2364554238 EngineCylinder2HeatRelease 6400;
BA_ "SPN" SG_ 2364554238 EngineCylinder2PeakPressure 6401;
BA_ "SPN" SG_ 2364554238 EngnClndr2LwFrqnKnkLvl 7610;
BA_ "SPN" SG_ 2364554238 EngnClndr2MxmmPrssrInrsRt 7630;
BA_ "SPN" SG_ 2364554238 EngnClndr2SnhrnsKnkLvl 6402;
BA_ "SPN" SG_ 2364554238 EngnClndr2PrssrSnsrPrlmnrFm 6403;
BA_ "SPN" SG_ 2364554494 EngineCylinder3HeatRelease 6404;
BA_ "SPN" SG_ 2364554494 EngineCylinder3PeakPressure 6405;
BA_ "SPN" SG_ 2364554494 EngnClndr3LwFrqnKnkLvl 7611;
BA_ "SPN" SG_ 2364554494 EngnClndr3MxmmPrssrInrsRt 7631;
BA_ "SPN" SG_ 2364554494 EngnClndr3SnhrnsKnkLvl 6406;
BA_ "SPN" SG_ 2364554494 EngnClndr3PrssrSnsrPrlmnrFm 6407;
BA_ "SPN" SG_ 2364554750 EngineCylinder4HeatRelease 6408;
BA_ "SPN" SG_ 2364554750 EngineCylinder4PeakPressure 6409;
BA_ "SPN" SG_ 2364554750 EngnClndr4LwFrqnKnkLvl 7612;
BA_ "SPN" SG_ 2364554750 EngnClndr4MxmmPrssrInrsRt 7632;
BA_ "SPN" SG_ 2364554750 EngnClndr4SnhrnsKnkLvl 6410;
BA_ "SPN" SG_ 2364554750 EngnClndr4PrssrSnsrPrlmnrFm 6411;
BA_ "SPN" SG_ 2364555006 EngineCylinder5HeatRelease 6412;
BA_ "SPN" SG_ 2364555006 EngineCylinder5PeakPressure 6413;
BA_ "SPN" SG_ 2364555006 EngnClndr5LwFrqnKnkLvl 7613;
BA_ "SPN" SG_ 2364555006 EngnClndr5MxmmPrssrInrsRt 7633;
BA_ "SPN" SG_ 2364555006 EngnClndr5SnhrnsKnkLvl 6414;
BA_ "SPN" SG_ 2364555006 EngnClndr5PrssrSnsrPrlmnrFm 6415;
BA_ "SPN" SG_ 2364555262 EngineCylinder6HeatRelease 6416;
BA_ "SPN" SG_ 2364555262 EngineCylinder6PeakPressure 6417;
BA_ "SPN" SG_ 2364555262 EngnClndr6LwFrqnKnkLvl 7614;
BA_ "SPN" SG_ 2364555262 EngnClndr6MxmmPrssrInrsRt 7634;
BA_ "SPN" SG_ 2364555262 EngnClndr6SnhrnsKnkLvl 6418;
BA_ "SPN" SG_ 2364555262 EngnClndr6PrssrSnsrPrlmnrFm 6419;
BA_ "SPN" SG_ 2364555518 EngineCylinder7HeatRelease 6420;
BA_ "SPN" SG_ 2364555518 EngineCylinder7PeakPressure 6421;
BA_ "SPN" SG_ 2364555518 EngnClndr7LwFrqnKnkLvl 7615;
BA_ "SPN" SG_ 2364555518 EngnClndr7MxmmPrssrInrsRt 7635;
BA_ "SPN" SG_ 2364555518 EngnClndr7SnhrnsKnkLvl 6422;
BA_ "SPN" SG_ 2364555518 EngnClndr7PrssrSnsrPrlmnrFm 6423;
BA_ "SPN" SG_ 2364555774 EngineCylinder8HeatRelease 6424;
BA_ "SPN" SG_ 2364555774 EngineCylinder8PeakPressure 6425;
BA_ "SPN" SG_ 2364555774 EngnClndr8LwFrqnKnkLvl 7616;
BA_ "SPN" SG_ 2364555774 EngnClndr8MxmmPrssrInrsRt 7636;
BA_ "SPN" SG_ 2364555774 EngnClndr8SnhrnsKnkLvl 6426;
BA_ "SPN" SG_ 2364555774 EngnClndr8PrssrSnsrPrlmnrFm 6427;
BA_ "SPN" SG_ 2364556030 EngineCylinder9HeatRelease 6428;
BA_ "SPN" SG_ 2364556030 EngineCylinder9PeakPressure 6429;
BA_ "SPN" SG_ 2364556030 EngnClndr9LwFrqnKnkLvl 7617;
BA_ "SPN" SG_ 2364556030 EngnClndr9MxmmPrssrInrsRt 7637;
BA_ "SPN" SG_ 2364556030 EngnClndr9SnhrnsKnkLvl 6430;
BA_ "SPN" SG_ 2364556030 EngnClndr9PrssrSnsrPrlmnrFm 6431;
BA_ "SPN" SG_ 2364556286 EngineCylinder10HeatRelease 6432;
BA_ "SPN" SG_ 2364556286 EngineCylinder10PeakPressure 6433;
BA_ "SPN" SG_ 2364556286 EngnClndr10LwFrqnKnkLvl 7618;
BA_ "SPN" SG_ 2364556286 EngnClndr10MxmmPrssrInrsRt 7638;
BA_ "SPN" SG_ 2364556286 EngnClndr10SnhrnsKnkLvl 6434;
BA_ "SPN" SG_ 2364556286 EngnClndr10PrssrSnsrPrlmnrFm 6435;
BA_ "SPN" SG_ 2364556542 EngineCylinder11HeatRelease 6436;
BA_ "SPN" SG_ 2364556542 EngineCylinder11PeakPressure 6437;
BA_ "SPN" SG_ 2364556542 EngnClndr11LwFrqnKnkLvl 7619;
BA_ "SPN" SG_ 2364556542 EngnClndr11MxmmPrssrInrsRt 7639;
BA_ "SPN" SG_ 2364556542 EngnClndr11SnhrnsKnkLvl 6438;
BA_ "SPN" SG_ 2364556542 EngnClndr11PrssrSnsrPrlmnrFm 6439;
BA_ "SPN" SG_ 2364556798 EngineCylinder12HeatRelease 6440;
BA_ "SPN" SG_ 2364556798 EngineCylinder12PeakPressure 6441;
BA_ "SPN" SG_ 2364556798 EngnClndr12LwFrqnKnkLvl 7620;
BA_ "SPN" SG_ 2364556798 EngnClndr12MxmmPrssrInrsRt 7640;
BA_ "SPN" SG_ 2364556798 EngnClndr12SnhrnsKnkLvl 6442;
BA_ "SPN" SG_ 2364556798 EngnClndr12PrssrSnsrPrlmnrFm 6443;
BA_ "SPN" SG_ 2364557054 EngineCylinder13HeatRelease 6444;
BA_ "SPN" SG_ 2364557054 EngineCylinder13PeakPressure 6445;
BA_ "SPN" SG_ 2364557054 EngnClndr13LwFrqnKnkLvl 7621;
BA_ "SPN" SG_ 2364557054 EngnClndr13MxmmPrssrInrsRt 7641;
BA_ "SPN" SG_ 2364557054 EngnClndr13SnhrnsKnkLvl 6446;
BA_ "SPN" SG_ 2364557054 EngnClndr13PrssrSnsrPrlmnrFm 6447;
BA_ "SPN" SG_ 2364557310 EngineCylinder14HeatRelease 6448;
BA_ "SPN" SG_ 2364557310 EngineCylinder14PeakPressure 6449;
BA_ "SPN" SG_ 2364557310 EngnClndr14LwFrqnKnkLvl 7622;
BA_ "SPN" SG_ 2364557310 EngnClndr14MxmmPrssrInrsRt 7642;
BA_ "SPN" SG_ 2364557310 EngnClndr14SnhrnsKnkLvl 6450;
BA_ "SPN" SG_ 2364557310 EngnClndr14PrssrSnsrPrlmnrFm 6451;
BA_ "SPN" SG_ 2364557566 EngineCylinder15HeatRelease 6452;
BA_ "SPN" SG_ 2364557566 EngineCylinder15PeakPressure 6453;
BA_ "SPN" SG_ 2364557566 EngnClndr15LwFrqnKnkLvl 7623;
BA_ "SPN" SG_ 2364557566 EngnClndr15MxmmPrssrInrsRt 7643;
BA_ "SPN" SG_ 2364557566 EngnClndr15SnhrnsKnkLvl 6454;
BA_ "SPN" SG_ 2364557566 EngnClndr15PrssrSnsrPrlmnrFm 6455;
